VERSION ""

NS_ :

BS_:

BU_: FLZCU_VCU_EP FLZCU_PDCS_EP FLZCU_EP VCU_EP FLZCU_SignalRoute_EP BMS CDU FMCU_ISG FMCU ISG RMCU RMCU_E0V EVCC PDCS_EP PDCS_EP_E0V CIC_EP RmcuCdu RmcuCdu_E0V FmcuVcu_EP FmcuVcu_EP_E0V

BO_ 515 EVCC_1: 24 EVCC
 SG_ EVCC_1_CRC1 : 7|8@0+ (1,0) [0|255] ""  FLZCU_VCU_EP,VCU_EP,BMS,CDU,PDCS_EP,PDCS_EP_E0V,RmcuCdu,RmcuCdu_E0V,FmcuVcu_EP,FmcuVcu_EP_E0V
 SG_ EVCC_1_RollgCntr1 : 11|4@0+ (1,0) [0|14] ""  FLZCU_VCU_EP,VCU_EP,BMS,CDU,PDCS_EP,PDCS_EP_E0V,RmcuCdu,RmcuCdu_E0V,FmcuVcu_EP,FmcuVcu_EP_E0V
 SG_ EVCC_1_Resd1 : 15|4@0+ (1,0) [0|15] ""  FLZCU_VCU_EP,VCU_EP,BMS,CDU,PDCS_EP,PDCS_EP_E0V,RmcuCdu,RmcuCdu_E0V,FmcuVcu_EP,FmcuVcu_EP_E0V
 SG_ EVCC_GunConnectSt : 23|2@0+ (1,0) [0|3] ""  FLZCU_VCU_EP,VCU_EP,BMS,CDU,RMCU,RMCU_E0V,PDCS_EP,PDCS_EP_E0V,RmcuCdu,RmcuCdu_E0V,FmcuVcu_EP,FmcuVcu_EP_E0V
 SG_ EVCC_ElectronicLockSts : 21|3@0+ (1,0) [0|4] ""  FLZCU_VCU_EP,VCU_EP,BMS,CDU,PDCS_EP,PDCS_EP_E0V,RmcuCdu,RmcuCdu_E0V,FmcuVcu_EP,FmcuVcu_EP_E0V
 SG_ EVCC_PPCode : 18|4@0+ (1,0) [0|15] ""  CDU,RmcuCdu,RmcuCdu_E0V
 SG_ EVCC_CC_RCR4_Sts : 30|13@0+ (1,0) [0|3400] "R"  FLZCU_VCU_EP,VCU_EP,BMS,CDU,PDCS_EP,PDCS_EP_E0V,RmcuCdu,RmcuCdu_E0V,FmcuVcu_EP,FmcuVcu_EP_E0V
 SG_ EVCC_CP_DutyCycleFault : 33|1@0+ (1,0) [0|1] ""  FLZCU_VCU_EP,VCU_EP,BMS,CDU,PDCS_EP,PDCS_EP_E0V,RmcuCdu,RmcuCdu_E0V,FmcuVcu_EP,FmcuVcu_EP_E0V
 SG_ EVCC_COUNTRY_SUPPORT : 32|2@0+ (1,0) [0|3] ""  FLZCU_VCU_EP,VCU_EP,BMS,CDU,PDCS_EP,PDCS_EP_E0V,RmcuCdu,RmcuCdu_E0V,FmcuVcu_EP,FmcuVcu_EP_E0V
 SG_ EVCC_CP_DutyCycleValue : 46|8@0+ (1,0) [0|100] "%"  CDU,RmcuCdu,RmcuCdu_E0V
 SG_ EVCC_CPSts : 54|3@0+ (1,0) [0|7] ""  FLZCU_VCU_EP,VCU_EP,BMS,CDU,PDCS_EP,PDCS_EP_E0V,RmcuCdu,RmcuCdu_E0V,FmcuVcu_EP,FmcuVcu_EP_E0V
 SG_ EVCC_S2Swtsts : 51|2@0+ (1,0) [0|3] ""  FLZCU_VCU_EP,VCU_EP,BMS,CDU,PDCS_EP,PDCS_EP_E0V,RmcuCdu,RmcuCdu_E0V,FmcuVcu_EP,FmcuVcu_EP_E0V
 SG_ EVCC_CC_ConnectSts : 49|2@0+ (1,0) [0|3] ""  FLZCU_VCU_EP,VCU_EP,BMS,CDU,PDCS_EP,PDCS_EP_E0V,RmcuCdu,RmcuCdu_E0V,FmcuVcu_EP,FmcuVcu_EP_E0V
 SG_ EVCC_CC_ConnectDischarSts : 63|2@0+ (1,0) [0|3] ""  FLZCU_VCU_EP,VCU_EP,BMS,CDU,PDCS_EP,PDCS_EP_E0V,RmcuCdu,RmcuCdu_E0V,FmcuVcu_EP,FmcuVcu_EP_E0V
 SG_ EVCC_CC2_ConnectSts : 61|2@0+ (1,0) [0|3] ""  FLZCU_VCU_EP,VCU_EP,BMS,RMCU,RMCU_E0V,PDCS_EP,PDCS_EP_E0V,RmcuCdu,RmcuCdu_E0V,FmcuVcu_EP,FmcuVcu_EP_E0V
 SG_ EVCC_CC2_Alarm : 59|1@0+ (1,0) [0|1] ""  FLZCU_VCU_EP,VCU_EP,BMS,PDCS_EP,PDCS_EP_E0V,FmcuVcu_EP,FmcuVcu_EP_E0V
 SG_ EVCC_ChargeType : 58|3@0+ (1,0) [0|7] ""  FLZCU_VCU_EP,VCU_EP,BMS,CDU,RMCU,RMCU_E0V,PDCS_EP,PDCS_EP_E0V,RmcuCdu,RmcuCdu_E0V,FmcuVcu_EP,FmcuVcu_EP_E0V
 SG_ EVCC_1_CRC2 : 71|8@0+ (1,0) [0|255] ""  FLZCU_VCU_EP,VCU_EP,BMS,CDU,PDCS_EP,PDCS_EP_E0V,RmcuCdu,RmcuCdu_E0V,FmcuVcu_EP,FmcuVcu_EP_E0V
 SG_ EVCC_1_RollgCntr2 : 75|4@0+ (1,0) [0|14] ""  FLZCU_VCU_EP,VCU_EP,BMS,CDU,PDCS_EP,PDCS_EP_E0V,RmcuCdu,RmcuCdu_E0V,FmcuVcu_EP,FmcuVcu_EP_E0V
 SG_ EVCC_1_Resd2 : 79|4@0+ (1,0) [0|15] ""  FLZCU_VCU_EP,VCU_EP,BMS,CDU,PDCS_EP,PDCS_EP_E0V,RmcuCdu,RmcuCdu_E0V,FmcuVcu_EP,FmcuVcu_EP_E0V
 SG_ EVCC_FaultLevel : 87|3@0+ (1,0) [0|7] ""  FLZCU_VCU_EP,VCU_EP,BMS,PDCS_EP,PDCS_EP_E0V,FmcuVcu_EP,FmcuVcu_EP_E0V
 SG_ EVCC_CPMaxVolt : 84|10@0+ (0.1,0) [0|102.2] "V"  FLZCU_VCU_EP,VCU_EP,BMS,CDU,PDCS_EP,PDCS_EP_E0V,RmcuCdu,RmcuCdu_E0V,FmcuVcu_EP,FmcuVcu_EP_E0V
 SG_ EVCC_DCPlusTemp : 90|8@0+ (1,-40) [-40|213] "��"  FLZCU_VCU_EP,VCU_EP,BMS,PDCS_EP,PDCS_EP_E0V,FmcuVcu_EP,FmcuVcu_EP_E0V
 SG_ EVCC_DCMinusTemp : 98|8@0+ (1,-40) [-40|213] "��"  FLZCU_VCU_EP,VCU_EP,BMS,PDCS_EP,PDCS_EP_E0V,FmcuVcu_EP,FmcuVcu_EP_E0V
 SG_ EVCC_TotalFaultNum : 106|8@0+ (1,0) [0|63] ""  FLZCU_VCU_EP,VCU_EP,PDCS_EP,PDCS_EP_E0V,FmcuVcu_EP,FmcuVcu_EP_E0V
 SG_ EVCC_1_Resd4 : 122|3@0+ (1,0) [0|7] ""  Vector__XXX
 SG_ EVCC_FaultNum1 : 114|8@0+ (1,0) [0|255] ""  FLZCU_VCU_EP,VCU_EP,PDCS_EP,PDCS_EP_E0V,FmcuVcu_EP,FmcuVcu_EP_E0V
 SG_ EVCC_1_CRC3 : 135|8@0+ (1,0) [0|255] ""  Vector__XXX
 SG_ EVCC_1_RollgCntr3 : 139|4@0+ (1,0) [0|14] ""  Vector__XXX
 SG_ EVCC_1_Resd3 : 143|4@0+ (1,0) [0|15] ""  Vector__XXX
 SG_ EVCC_FaultNum2 : 151|8@0+ (1,0) [0|255] ""  FLZCU_VCU_EP,VCU_EP,PDCS_EP,PDCS_EP_E0V,FmcuVcu_EP,FmcuVcu_EP_E0V
 SG_ EVCC_CPVolt : 159|7@0+ (0.1,0) [0|12.7] "V"  Vector__XXX
 SG_ EVCC_PPRes : 167|13@0+ (1,0) [0|8191] "��"  Vector__XXX
 SG_ EVCC_ChargingStage : 183|8@0+ (1,0) [0|255] ""  FLZCU_VCU_EP,VCU_EP,BMS,RMCU,RMCU_E0V,PDCS_EP,PDCS_EP_E0V,RmcuCdu,RmcuCdu_E0V,FmcuVcu_EP,FmcuVcu_EP_E0V

BO_ 1113 EVCC_2: 64 EVCC
 SG_ EVCC_PLCAvgAttenuation : 7|8@0+ (1,0) [0|255] "db"  Vector__XXX
 SG_ EVCC_StopChrgnReason : 15|2@0+ (1,0) [0|3] ""  Vector__XXX
 SG_ EVCC_A_POSITIVE : 13|2@0+ (1,0) [0|3] ""  Vector__XXX
 SG_ EVCC_SupplierCode : 23|16@0+ (1,0) [0|65535] ""  Vector__XXX
 SG_ EVCC_HwVersion : 39|8@0+ (1,0) [0|255] ""  Vector__XXX
 SG_ EVCC_SwMajorVersion : 47|8@0+ (1,0) [0|255] ""  Vector__XXX
 SG_ EVCC_SwMinorVersion : 55|8@0+ (1,0) [0|255] ""  Vector__XXX
 SG_ EVCC_SwPatchVersion : 63|8@0+ (1,0) [0|255] ""  Vector__XXX
 SG_ EVCC_2_CRC2 : 71|8@0+ (1,0) [0|255] ""  Vector__XXX
 SG_ EVCC_2_RollgCntr2 : 75|4@0+ (1,0) [0|14] ""  Vector__XXX
 SG_ EVCC_2_Resd2 : 79|4@0+ (1,0) [0|15] ""  Vector__XXX
 SG_ EVCC_SwVersionYear : 87|8@0+ (1,0) [0|255] ""  Vector__XXX
 SG_ EVCC_SwVersionMonth : 95|8@0+ (1,0) [0|12] ""  Vector__XXX
 SG_ EVCC_SwVersionDay : 103|8@0+ (1,0) [0|31] ""  Vector__XXX
 SG_ EVSE_MaxVol : 111|14@0+ (0.1,0) [0|1638.3] "V"  FLZCU_VCU_EP,VCU_EP,BMS,RMCU,RMCU_E0V,PDCS_EP,PDCS_EP_E0V,RmcuCdu,RmcuCdu_E0V,FmcuVcu_EP,FmcuVcu_EP_E0V
 SG_ EVCC_GB_RX_ERROR : 123|4@0+ (1,0) [0|15] ""  BMS
 SG_ EVCC_GB_CHM_ERROR : 125|2@0+ (1,0) [0|3] ""  BMS
 SG_ EVCC_GB_CML_ERROR : 126|1@0+ (1,0) [0|1] ""  BMS
 SG_ EVCC_APP_DM_ERROR : 113|3@0+ (1,0) [0|7] ""  Vector__XXX
 SG_ EVCC_2_CRC3 : 135|8@0+ (1,0) [0|255] ""  Vector__XXX
 SG_ EVCC_2_RollgCntr3 : 139|4@0+ (1,0) [0|14] ""  Vector__XXX
 SG_ EVCC_2_Resd3 : 143|4@0+ (1,0) [0|15] ""  Vector__XXX
 SG_ EVSE_MinVol : 151|14@0+ (0.1,0) [0|1638.3] "V"  FLZCU_VCU_EP,VCU_EP,BMS,RMCU,RMCU_E0V,PDCS_EP,PDCS_EP_E0V,RmcuCdu,RmcuCdu_E0V,FmcuVcu_EP,FmcuVcu_EP_E0V
 SG_ EVSE_MaxCur : 153|14@0+ (0.1,0) [0|1638.3] "A"  FLZCU_VCU_EP,VCU_EP,BMS,PDCS_EP,PDCS_EP_E0V,FmcuVcu_EP,FmcuVcu_EP_E0V
 SG_ EVSE_MinCur : 171|10@0+ (0.1,0) [0|102.3] "A"  FLZCU_VCU_EP,VCU_EP,BMS,RMCU,RMCU_E0V,PDCS_EP,PDCS_EP_E0V,RmcuCdu,RmcuCdu_E0V,FmcuVcu_EP,FmcuVcu_EP_E0V
 SG_ EVCC_GB_SPECIAL_ERROR : 186|3@0+ (1,0) [0|7] ""  BMS
 SG_ EVCC_GB_CRM_ERROR : 188|2@0+ (1,0) [0|3] ""  BMS
 SG_ EVCC_GB_CRO_ERROR : 189|1@0+ (1,0) [0|1] ""  BMS
 SG_ EVCC_GB_CCS_ERROR : 177|2@0+ (1,0) [0|3] ""  BMS
 SG_ EVCC_GB_CST_ERROR : 190|1@0+ (1,0) [0|1] ""  BMS
 SG_ EVCC_GB_CSD_ERROR : 191|1@0+ (1,0) [0|1] ""  BMS
 SG_ EVCC_2_CRC4 : 199|8@0+ (1,0) [0|255] ""  Vector__XXX
 SG_ EVCC_2_RollgCntr4 : 203|4@0+ (1,0) [0|14] ""  Vector__XXX
 SG_ EVCC_2_Resd4 : 207|4@0+ (1,0) [0|15] ""  Vector__XXX
 SG_ EVSE_MaxPwr : 215|11@0+ (1,0) [0|2047] "KW"  FLZCU_VCU_EP,VCU_EP,BMS,PDCS_EP,PDCS_EP_E0V,FmcuVcu_EP,FmcuVcu_EP_E0V
 SG_ EVSE_OutputVol : 220|14@0+ (0.1,0) [0|1638.3] "V"  FLZCU_VCU_EP,VCU_EP,BMS,RMCU,RMCU_E0V,PDCS_EP,PDCS_EP_E0V,RmcuCdu,RmcuCdu_E0V,FmcuVcu_EP,FmcuVcu_EP_E0V
 SG_ EVSE_OutputCur : 238|12@0+ (0.5,0) [0|2047.5] "A"  BMS
 SG_ EVCC_MATCHING_ERROR : 242|3@0+ (1,0) [0|7] ""  Vector__XXX
 SG_ EVCC_MATCHED_ERROR : 255|1@0+ (1,0) [0|1] ""  Vector__XXX
 SG_ EVCC_BC_B1_ERROR : 254|2@0+ (1,0) [0|3] ""  Vector__XXX
 SG_ EVCC_BC_B2_ERROR : 252|2@0+ (1,0) [0|3] ""  Vector__XXX
 SG_ EVCC_BC_STATE_REQ_TO : 250|1@0+ (1,0) [0|1] ""  Vector__XXX
 SG_ EVCC_BC_C2_ERROR : 249|2@0+ (1,0) [0|3] ""  Vector__XXX
 SG_ EVCC_2_CRC5 : 263|8@0+ (1,0) [0|255] ""  Vector__XXX
 SG_ EVCC_2_RollgCntr5 : 267|4@0+ (1,0) [0|14] ""  Vector__XXX
 SG_ EVCC_2_Resd5 : 271|4@0+ (1,0) [0|15] ""  Vector__XXX
 SG_ EVCC_BC_EMC_ERROR : 279|3@0+ (1,0) [0|7] ""  Vector__XXX
 SG_ EVCC_BC_STOP_ERROR : 276|3@0+ (1,0) [0|7] ""  Vector__XXX
 SG_ EVCC_CONNECTING_ERROR : 273|3@0+ (1,0) [0|7] ""  Vector__XXX
 SG_ EVCC_SLEEP_AEF_DETECT : 286|1@0+ (1,0) [0|1] ""  Vector__XXX
 SG_ EVCC_V2G_REQ_TO_ERROR : 285|5@0+ (1,0) [0|31] ""  Vector__XXX
 SG_ EVCC_V2G_RES_TO_ERROR : 280|5@0+ (1,0) [0|31] ""  Vector__XXX
 SG_ EVCC_V2G_ERROR : 291|4@0+ (1,0) [0|15] ""  Vector__XXX
 SG_ EVCC_SSETUP_ERROR : 303|3@0+ (1,0) [0|7] ""  Vector__XXX
 SG_ EVCC_SDISCOVERY_ERROR : 300|3@0+ (1,0) [0|7] ""  Vector__XXX
 SG_ EVCC_PSS_ERROR : 297|3@0+ (1,0) [0|7] ""  Vector__XXX
 SG_ EVCC_AUTHORIZATION_ERROR : 310|3@0+ (1,0) [0|7] ""  Vector__XXX
 SG_ EVCC_CPD_ERROR : 307|3@0+ (1,0) [0|7] ""  Vector__XXX
 SG_ EVCC_POWERDELIVERY_CP_STATE : 304|1@0+ (1,0) [0|1] ""  Vector__XXX
 SG_ EVCC_CHARGINGSTATUS_ERROR : 319|3@0+ (1,0) [0|7] ""  Vector__XXX
 SG_ EVCC_SSTOP_ERROR : 316|3@0+ (1,0) [0|7] ""  Vector__XXX
 SG_ EVCC_2_Resd8 : 313|2@0+ (1,0) [0|3] ""  Vector__XXX
 SG_ EVCC_2_CRC6 : 327|8@0+ (1,0) [0|255] ""  Vector__XXX
 SG_ EVCC_2_RollgCntr6 : 331|4@0+ (1,0) [0|14] ""  Vector__XXX
 SG_ EVCC_2_Resd6 : 335|4@0+ (1,0) [0|15] ""  Vector__XXX
 SG_ EVCC_CABLECHECK_ERROR : 343|3@0+ (1,0) [0|7] ""  Vector__XXX
 SG_ EVCC_PRECHARGE_ERROR : 340|3@0+ (1,0) [0|7] ""  Vector__XXX
 SG_ EVCC_CURRENTDEMAND_ERROR : 337|3@0+ (1,0) [0|7] ""  Vector__XXX
 SG_ EVCC_WDETECTION_ERROR : 350|3@0+ (1,0) [0|7] ""  Vector__XXX
 SG_ EVCC_V2GTP_ERROR : 347|3@0+ (1,0) [0|7] ""  Vector__XXX
 SG_ EVCC_EXI_ERROR : 344|3@0+ (1,0) [0|7] ""  Vector__XXX
 SG_ EVCC_NET_ERROR : 357|4@0+ (1,0) [0|15] ""  Vector__XXX
 SG_ EVCC_EMC_ERROR : 353|3@0+ (1,0) [0|7] ""  Vector__XXX
 SG_ EVCC_DIN_ERROR : 366|4@0+ (1,0) [0|15] ""  Vector__XXX
 SG_ EVCC_DIN_SSETUP_ERROR : 362|3@0+ (1,0) [0|7] ""  Vector__XXX
 SG_ EVCC_DIN_SDISCOVERY_ERROR : 375|3@0+ (1,0) [0|7] ""  Vector__XXX
 SG_ EVCC_DIN_SPS_ERROR : 372|3@0+ (1,0) [0|7] ""  Vector__XXX
 SG_ EVCC_DIN_CAUTHENTICATION_ERROR : 369|3@0+ (1,0) [0|7] ""  Vector__XXX
 SG_ EVCC_DIN_CPD_ERROR : 382|3@0+ (1,0) [0|7] ""  Vector__XXX
 SG_ EVCC_2_Resd9 : 376|1@0+ (1,0) [0|1] ""  Vector__XXX
 SG_ EVCC_DIN_CABLECHECK_ERROR : 379|3@0+ (1,0) [0|7] ""  Vector__XXX
 SG_ EVCC_2_CRC7 : 391|8@0+ (1,0) [0|255] ""  Vector__XXX
 SG_ EVCC_2_RollgCntr7 : 395|4@0+ (1,0) [0|14] ""  Vector__XXX
 SG_ EVCC_2_Resd7 : 399|4@0+ (1,0) [0|15] ""  Vector__XXX
 SG_ EVCC_DIN_PRECHARGE_ERROR : 407|3@0+ (1,0) [0|7] ""  Vector__XXX
 SG_ EVCC_DIN_POWERDELIVERY_ERROR : 404|3@0+ (1,0) [0|7] ""  Vector__XXX
 SG_ EVCC_DIN_CURRENTDEMAND_ERROR : 401|3@0+ (1,0) [0|7] ""  Vector__XXX
 SG_ EVCC_DIN_WDETECTION_ERROR : 414|3@0+ (1,0) [0|7] ""  Vector__XXX
 SG_ EVCC_DIN_SSTOP_ERROR : 411|3@0+ (1,0) [0|7] ""  Vector__XXX
 SG_ EVCC_DIN_METERINGRECEIPT_ERROR : 408|3@0+ (1,0) [0|7] ""  Vector__XXX
 SG_ EVCC_SLAC_RETRY_TIMEOUT : 421|1@0+ (1,0) [0|1] ""  Vector__XXX
 SG_ EVCC_SLAC_AMPMAP_ERROR : 420|2@0+ (1,0) [0|3] ""  Vector__XXX
 SG_ EVCC_SLAC_ATTEN_ERROR : 418|2@0+ (1,0) [0|3] ""  Vector__XXX
 SG_ EVCC_SLAC_BCB_FAILED : 416|1@0+ (1,0) [0|1] ""  Vector__XXX
 SG_ EVCC_SLAC_JOIN_ERROR : 431|3@0+ (1,0) [0|7] ""  Vector__XXX
 SG_ EVCC_SLAC_PAUSE_RETRY_OVERFLOW : 428|1@0+ (1,0) [0|1] ""  Vector__XXX
 SG_ EVCC_SLAC_RESUME_ERROR : 427|2@0+ (1,0) [0|3] ""  Vector__XXX
 SG_ EVCC_SLAC_ETH_ERROR : 425|2@0+ (1,0) [0|3] ""  Vector__XXX
 SG_ EVCC_SLAC_DISLINK_RETRY_OVERFLOW : 439|1@0+ (1,0) [0|1] ""  Vector__XXX
 SG_ EVCC_SLAC_INIT_RETRY_OVERFLOW : 438|1@0+ (1,0) [0|1] ""  Vector__XXX
 SG_ EVCC_APP_PSS_ERROR : 437|2@0+ (1,0) [0|3] ""  Vector__XXX
 SG_ EVCC_APP_CPD_ERROR : 435|2@0+ (1,0) [0|3] ""  Vector__XXX
 SG_ EVCC_APP_DTC_ERROR : 433|2@0+ (1,0) [0|3] ""  Vector__XXX
 SG_ EVCC_DIN_CCPC_ERROR : 447|3@0+ (1,0) [0|7] ""  Vector__XXX
 SG_ EVCC_V2G_CCPC_ERROR : 444|3@0+ (1,0) [0|7] ""  Vector__XXX
 SG_ EVCC_GunConnectSt : 471|2@0+ (1,0) [0|3] ""  Vector__XXX
 SG_ EVCC_ElectronicLockRes : 479|16@0+ (1,0) [0|65534] ""  Vector__XXX
 SG_ EVCC_ElectronicLockSignal_Rel : 465|2@0+ (1,0) [0|3] ""  Vector__XXX
 SG_ EVCC_PLCNodeFwVer : 495|16@0+ (1,0) [0|65535] ""  Vector__XXX
 SG_ EVCC_BatVolConfig : 511|2@0+ (1,0) [0|3] ""  Vector__XXX
 SG_ EVCC_2_Resd10 : 509|6@0+ (1,0) [0|63] ""  Vector__XXX

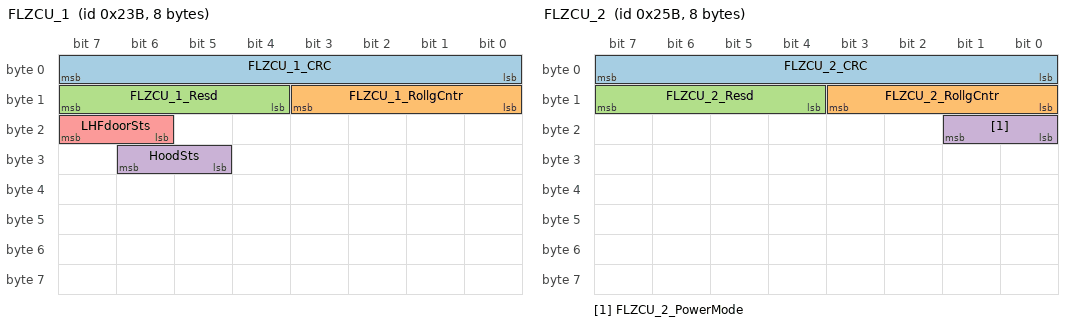
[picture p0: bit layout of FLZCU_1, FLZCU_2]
BO_ 571 FLZCU_1: 8 FLZCU_VCU_EP
 SG_ FLZCU_1_CRC : 7|8@0+ (1,0) [0|255] ""  Vector__XXX
 SG_ FLZCU_1_RollgCntr : 11|4@0+ (1,0) [0|14] ""  Vector__XXX
 SG_ FLZCU_1_Resd : 15|4@0+ (1,0) [0|15] ""  Vector__XXX
 SG_ HoodSts : 30|2@0+ (1,0) [0|3] ""  PDCS_EP,PDCS_EP_E0V,FmcuVcu_EP,FmcuVcu_EP_E0V
 SG_ LHFdoorSts : 23|2@0+ (1,0) [0|3] ""  CDU,RmcuCdu,RmcuCdu_E0V

BO_ 603 FLZCU_2: 8 Vector__XXX
 SG_ FLZCU_2_CRC : 7|8@0+ (1,0) [0|255] ""  FMCU_ISG,FMCU,ISG,RMCU,RMCU_E0V,PDCS_EP,PDCS_EP_E0V,RmcuCdu,RmcuCdu_E0V,FmcuVcu_EP,FmcuVcu_EP_E0V
 SG_ FLZCU_2_RollgCntr : 11|4@0+ (1,0) [0|14] ""  FMCU_ISG,FMCU,ISG,RMCU,RMCU_E0V,PDCS_EP,PDCS_EP_E0V,RmcuCdu,RmcuCdu_E0V,FmcuVcu_EP,FmcuVcu_EP_E0V
 SG_ FLZCU_2_Resd : 15|4@0+ (1,0) [0|15] ""  FMCU_ISG,FMCU,ISG,RMCU,RMCU_E0V,PDCS_EP,PDCS_EP_E0V,RmcuCdu,RmcuCdu_E0V,FmcuVcu_EP,FmcuVcu_EP_E0V
 SG_ FLZCU_2_PowerMode : 17|2@0+ (1,0) [0|3] ""  FMCU_ISG,FMCU,ISG,RMCU,RMCU_E0V,PDCS_EP,PDCS_EP_E0V,RmcuCdu,RmcuCdu_E0V,FmcuVcu_EP,FmcuVcu_EP_E0V

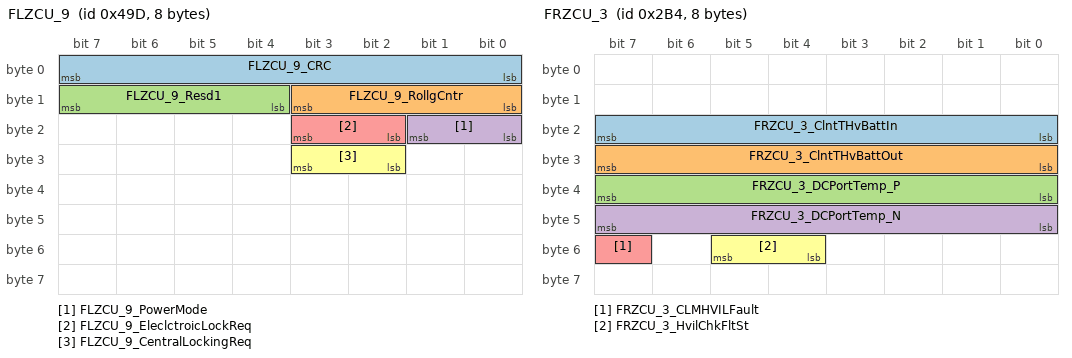
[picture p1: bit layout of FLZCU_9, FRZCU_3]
BO_ 1181 FLZCU_9: 8 FLZCU_VCU_EP
 SG_ FLZCU_9_CRC : 7|8@0+ (1,0) [0|255] ""  CIC_EP
 SG_ FLZCU_9_RollgCntr : 11|4@0+ (1,0) [0|14] ""  CIC_EP
 SG_ FLZCU_9_Resd1 : 15|4@0+ (1,0) [0|15] ""  CIC_EP
 SG_ FLZCU_9_PowerMode : 17|2@0+ (1,0) [0|3] ""  BMS,CIC_EP
 SG_ FLZCU_9_EleclctroicLockReq : 19|2@0+ (1,0) [0|3] ""  CDU,PDCS_EP,PDCS_EP_E0V,RmcuCdu,RmcuCdu_E0V,FmcuVcu_EP,FmcuVcu_EP_E0V
 SG_ FLZCU_9_CentralLockingReq : 27|2@0+ (1,0) [0|3] ""  CDU,EVCC,CIC_EP,RmcuCdu,RmcuCdu_E0V

BO_ 692 FRZCU_3: 8 Vector__XXX
 SG_ FRZCU_3_ClntTHvBattIn : 23|8@0+ (1,-40) [-40|120] "grad celsius (��C)"  BMS,PDCS_EP,PDCS_EP_E0V,FmcuVcu_EP,FmcuVcu_EP_E0V
 SG_ FRZCU_3_ClntTHvBattOut : 31|8@0+ (1,-40) [-40|120] "grad celsius (��C)"  BMS,PDCS_EP,PDCS_EP_E0V,FmcuVcu_EP,FmcuVcu_EP_E0V
 SG_ FRZCU_3_DCPortTemp_P : 39|8@0+ (1,-40) [-40|213] "grad celsius (��C)"  BMS
 SG_ FRZCU_3_DCPortTemp_N : 47|8@0+ (1,-40) [-40|213] "grad celsius (��C)"  BMS
 SG_ FRZCU_3_CLMHVILFault : 55|1@0+ (1,0) [0|1] ""  PDCS_EP,PDCS_EP_E0V,FmcuVcu_EP,FmcuVcu_EP_E0V
 SG_ FRZCU_3_HvilChkFltSt : 53|2@0+ (1,0) [0|3] ""  PDCS_EP,PDCS_EP_E0V,FmcuVcu_EP,FmcuVcu_EP_E0V

BO_ 469 FMCU_1: 32 FMCU_ISG
 SG_ FMCU_1_CRC1 : 7|8@0+ (1,0) [0|255] ""  FLZCU_VCU_EP,FLZCU_PDCS_EP,VCU_EP,PDCS_EP,PDCS_EP_E0V
 SG_ FMCU_1_RollgCntr1 : 11|4@0+ (1,0) [0|14] ""  FLZCU_VCU_EP,FLZCU_PDCS_EP,VCU_EP,PDCS_EP,PDCS_EP_E0V
 SG_ FMCU_1_Resd1 : 15|4@0+ (1,0) [0|15] ""  FLZCU_VCU_EP,FLZCU_PDCS_EP,VCU_EP,PDCS_EP,PDCS_EP_E0V
 SG_ FMCU_TorqMax : 23|12@0+ (0.25,0) [0|350] "Nm"  FLZCU_VCU_EP,FLZCU_PDCS_EP,VCU_EP,RMCU,RMCU_E0V,PDCS_EP,PDCS_EP_E0V,CIC_EP,RmcuCdu,RmcuCdu_E0V
 SG_ FMCU_TorqMin : 27|12@0+ (0.25,-350) [-350|0] "Nm"  FLZCU_VCU_EP,FLZCU_PDCS_EP,VCU_EP,RMCU,RMCU_E0V,PDCS_EP,PDCS_EP_E0V,CIC_EP,RmcuCdu,RmcuCdu_E0V
 SG_ FMCU_TorqAct : 47|12@0+ (0.25,-350) [-350|350] "Nm"  FLZCU_VCU_EP,FLZCU_PDCS_EP,VCU_EP,RMCU,RMCU_E0V,PDCS_EP,PDCS_EP_E0V,RmcuCdu,RmcuCdu_E0V
 SG_ FMCU_ModeSt : 51|4@0+ (1,0) [0|15] ""  FLZCU_VCU_EP,FLZCU_PDCS_EP,VCU_EP,FLZCU_SignalRoute_EP,BMS,PDCS_EP,PDCS_EP_E0V
 SG_ FMCU_1_CRC2 : 71|8@0+ (1,0) [0|255] ""  FLZCU_VCU_EP,FLZCU_PDCS_EP,VCU_EP,PDCS_EP,PDCS_EP_E0V
 SG_ FMCU_1_RollgCntr2 : 75|4@0+ (1,0) [0|14] ""  FLZCU_VCU_EP,FLZCU_PDCS_EP,VCU_EP,PDCS_EP,PDCS_EP_E0V
 SG_ FMCU_1_Resd2 : 79|4@0+ (1,0) [0|15] ""  FLZCU_VCU_EP,FLZCU_PDCS_EP,VCU_EP,PDCS_EP,PDCS_EP_E0V
 SG_ FMCU_SpdAct : 87|16@0+ (1,-32767) [-32767|32766] "rpm"  FLZCU_VCU_EP,FLZCU_PDCS_EP,VCU_EP,RMCU,RMCU_E0V,PDCS_EP,PDCS_EP_E0V,RmcuCdu,RmcuCdu_E0V
 SG_ FMCU_TrqActDampingReq : 103|12@0+ (0.25,-350) [-350|350] "Nm"  FLZCU_VCU_EP,FLZCU_PDCS_EP,VCU_EP,PDCS_EP,PDCS_EP_E0V
 SG_ FMCU_FMCUDeratSts : 107|4@0+ (1,0) [0|15] ""  FLZCU_VCU_EP,FLZCU_PDCS_EP,VCU_EP,FLZCU_SignalRoute_EP,PDCS_EP,PDCS_EP_E0V
 SG_ FMCU_UdcAct : 119|10@0+ (1,0) [0|1021] "V"  FLZCU_VCU_EP,FLZCU_PDCS_EP,VCU_EP,BMS,PDCS_EP,PDCS_EP_E0V
 SG_ FMCU_1_CRC3 : 135|8@0+ (1,0) [0|255] ""  FLZCU_VCU_EP,FLZCU_PDCS_EP,VCU_EP,PDCS_EP,PDCS_EP_E0V
 SG_ FMCU_1_RollgCntr3 : 139|4@0+ (1,0) [0|14] ""  FLZCU_VCU_EP,FLZCU_PDCS_EP,VCU_EP,PDCS_EP,PDCS_EP_E0V
 SG_ FMCU_1_Resd3 : 143|4@0+ (1,0) [0|15] ""  FLZCU_VCU_EP,FLZCU_PDCS_EP,VCU_EP,PDCS_EP,PDCS_EP_E0V
 SG_ FMCU_IdcAct : 151|11@0+ (1,-1023) [-1023|1021] "A"  FLZCU_VCU_EP,FLZCU_PDCS_EP,VCU_EP,BMS,PDCS_EP,PDCS_EP_E0V
 SG_ FMCU_ErrLvl : 156|3@0+ (1,0) [0|7] ""  FLZCU_VCU_EP,FLZCU_PDCS_EP,VCU_EP,RMCU,RMCU_E0V,PDCS_EP,PDCS_EP_E0V,RmcuCdu,RmcuCdu_E0V
 SG_ FMCU_InterlockStatus : 152|1@0+ (1,0) [0|1] ""  FLZCU_VCU_EP,FLZCU_PDCS_EP,VCU_EP,PDCS_EP,PDCS_EP_E0V
 SG_ FMCU_DampActive : 153|1@0+ (1,0) [0|1] ""  FLZCU_VCU_EP,FLZCU_PDCS_EP,VCU_EP,PDCS_EP,PDCS_EP_E0V
 SG_ FMCU_E_ClutchErrLvl : 173|3@0+ (1,0) [0|7] ""  FLZCU_VCU_EP,FLZCU_PDCS_EP,PDCS_EP,PDCS_EP_E0V
 SG_ FMCU_E_ClutchActMod : 170|3@0+ (1,0) [0|7] ""  FLZCU_VCU_EP,FLZCU_PDCS_EP,PDCS_EP,PDCS_EP_E0V
 SG_ FMCU_E_ClutchStus : 183|2@0+ (1,0) [0|3] ""  FLZCU_VCU_EP,FLZCU_PDCS_EP,PDCS_EP,PDCS_EP_E0V
 SG_ FMCU_E_ClutchCurr : 191|6@0+ (0.2,0) [0|10] ""  FLZCU_VCU_EP,FLZCU_PDCS_EP,PDCS_EP,PDCS_EP_E0V
 SG_ FMCU_E_ClutchEngMilLampReq : 185|2@0+ (1,0) [0|3] ""  FLZCU_VCU_EP,FLZCU_PDCS_EP,PDCS_EP,PDCS_EP_E0V
 SG_ FMCU_NegTrqAvailMin_2s : 212|13@0+ (0.25,-350) [-350|0] ""  FLZCU_VCU_EP,FLZCU_PDCS_EP,VCU_EP,PDCS_EP,PDCS_EP_E0V
 SG_ FMCU_PosTrqAvailMax_2s : 228|13@0+ (0.25,0) [0|350] ""  FLZCU_VCU_EP,FLZCU_PDCS_EP,VCU_EP,PDCS_EP,PDCS_EP_E0V

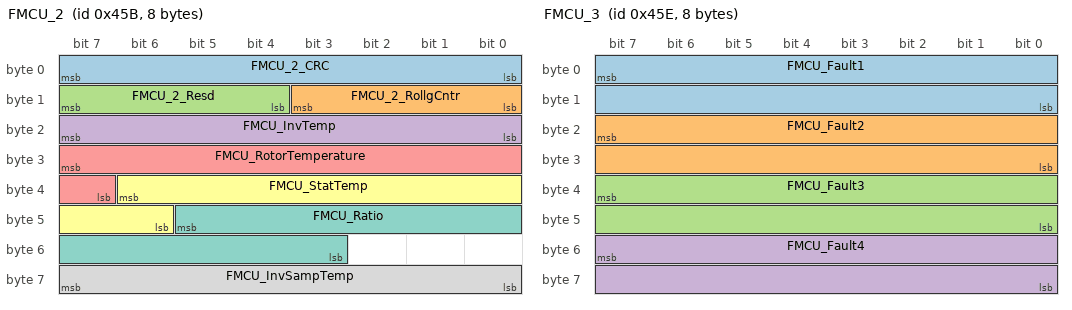
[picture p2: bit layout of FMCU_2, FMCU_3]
BO_ 1115 FMCU_2: 8 FMCU_ISG
 SG_ FMCU_2_CRC : 7|8@0+ (1,0) [0|255] ""  FLZCU_VCU_EP,FLZCU_PDCS_EP,VCU_EP,PDCS_EP,PDCS_EP_E0V
 SG_ FMCU_2_RollgCntr : 11|4@0+ (1,0) [0|14] ""  FLZCU_VCU_EP,FLZCU_PDCS_EP,VCU_EP,PDCS_EP,PDCS_EP_E0V
 SG_ FMCU_2_Resd : 15|4@0+ (1,0) [0|15] ""  FLZCU_VCU_EP,FLZCU_PDCS_EP,VCU_EP,PDCS_EP,PDCS_EP_E0V
 SG_ FMCU_InvTemp : 23|8@0+ (1,-40) [-40|213] "oC"  FLZCU_VCU_EP,FLZCU_PDCS_EP,VCU_EP,PDCS_EP,PDCS_EP_E0V
 SG_ FMCU_RotorTemperature : 31|9@0+ (1,-40) [-40|469] "oC"  FLZCU_VCU_EP,FLZCU_PDCS_EP,VCU_EP,PDCS_EP,PDCS_EP_E0V
 SG_ FMCU_StatTemp : 38|9@0+ (1,-40) [-40|469] "oC"  FLZCU_VCU_EP,FLZCU_PDCS_EP,VCU_EP,PDCS_EP,PDCS_EP_E0V
 SG_ FMCU_Ratio : 45|11@0+ (0.01,1) [8|15] ""  FLZCU_VCU_EP,FLZCU_PDCS_EP,VCU_EP,PDCS_EP,PDCS_EP_E0V
 SG_ FMCU_InvSampTemp : 63|8@0+ (1,-40) [-40|213] "oC"  FLZCU_VCU_EP,FLZCU_PDCS_EP,VCU_EP,PDCS_EP,PDCS_EP_E0V

BO_ 1118 FMCU_3: 8 FMCU_ISG
 SG_ FMCU_Fault1 : 7|16@0+ (1,0) [0|65535] ""  FLZCU_VCU_EP,FLZCU_PDCS_EP
 SG_ FMCU_Fault2 : 23|16@0+ (1,0) [0|65535] ""  FLZCU_VCU_EP,FLZCU_PDCS_EP
 SG_ FMCU_Fault3 : 39|16@0+ (1,0) [0|65535] ""  FLZCU_VCU_EP,FLZCU_PDCS_EP
 SG_ FMCU_Fault4 : 55|16@0+ (1,0) [0|65535] ""  FLZCU_VCU_EP,FLZCU_PDCS_EP

BO_ 1088 FMCU_4: 16 FMCU_ISG
 SG_ FMCU_WPhaseCurrent : 23|11@0+ (1,-1023) [-1023|1023] "A"  FLZCU_VCU_EP,FLZCU_PDCS_EP
 SG_ FMCU_VPhaseCurrent : 26|11@0+ (1,-1023) [-1023|1023] "A"  FLZCU_VCU_EP,FLZCU_PDCS_EP
 SG_ FMCU_UPhaseCurrent : 47|11@0+ (1,-1023) [-1023|1023] "A"  FLZCU_VCU_EP,FLZCU_PDCS_EP
 SG_ FMCU_4_SWInfo : 63|8@0+ (1,0) [0|255] ""  FLZCU_VCU_EP,FLZCU_PDCS_EP
 SG_ FMCU_4_CRC : 71|8@0+ (1,0) [0|255] ""  FLZCU_VCU_EP,FLZCU_PDCS_EP,VCU_EP,PDCS_EP,PDCS_EP_E0V
 SG_ FMCU_4_RollgCntr : 75|4@0+ (1,0) [0|14] ""  FLZCU_VCU_EP,FLZCU_PDCS_EP,VCU_EP,PDCS_EP,PDCS_EP_E0V
 SG_ FMCU_4_Resd : 79|4@0+ (1,0) [0|15] ""  FLZCU_VCU_EP,FLZCU_PDCS_EP,VCU_EP,PDCS_EP,PDCS_EP_E0V
 SG_ FMCU_TempW : 87|8@0+ (1,-40) [-40|213] "oC"  FLZCU_VCU_EP,FLZCU_PDCS_EP,VCU_EP,PDCS_EP,PDCS_EP_E0V
 SG_ FMCU_TempV : 95|8@0+ (1,-40) [-40|213] "oC"  FLZCU_VCU_EP,FLZCU_PDCS_EP,VCU_EP,PDCS_EP,PDCS_EP_E0V
 SG_ FMCU_TempU : 103|8@0+ (1,-40) [-40|213] "oC"  FLZCU_VCU_EP,FLZCU_PDCS_EP,VCU_EP,PDCS_EP,PDCS_EP_E0V
 SG_ FMCU_CoolantTemp : 111|8@0+ (1,-40) [-40|213] "oC"  FLZCU_VCU_EP,FLZCU_PDCS_EP,VCU_EP,PDCS_EP,PDCS_EP_E0V
 SG_ FMCU_Delta_TJ_Coolant : 119|8@0+ (1,-40) [-40|213] "oC"  FLZCU_VCU_EP,FLZCU_PDCS_EP,VCU_EP,PDCS_EP,PDCS_EP_E0V
 SG_ FMCU_IGBTmode : 122|3@0+ (1,0) [0|7] ""  FLZCU_VCU_EP,FLZCU_PDCS_EP,VCU_EP,PDCS_EP,PDCS_EP_E0V

BO_TX_BU_ 571 : FLZCU_VCU_EP,FLZCU_PDCS_EP,FLZCU_EP,FLZCU_SignalRoute_EP;

BO_TX_BU_ 1181 : FLZCU_VCU_EP,FLZCU_PDCS_EP,FLZCU_EP,FLZCU_SignalRoute_EP;

BO_TX_BU_ 469 : FMCU_ISG,FMCU,FmcuVcu_EP,FmcuVcu_EP_E0V;

BO_TX_BU_ 1115 : FMCU_ISG,FMCU,FmcuVcu_EP,FmcuVcu_EP_E0V;

BO_TX_BU_ 1118 : FMCU_ISG,FMCU,FmcuVcu_EP,FmcuVcu_EP_E0V;

BO_TX_BU_ 1088 : FMCU_ISG,FMCU,FmcuVcu_EP,FmcuVcu_EP_E0V;
CM_ SG_ 515 EVCC_1_CRC1 "Profile1A:E2E CRC (SAE J1850 CRC-8) for 8 Bytes
DataID:0x007B";
CM_ SG_ 515 EVCC_1_RollgCntr1 "Profile1A:E2E Rolling message counter(the maximum value of Alive counter is 14)";
CM_ SG_ 515 EVCC_1_Resd1 "Profile1A:E2E Reserved";
CM_ SG_ 515 EVCC_GunConnectSt "���ǹ����״̬
0-δ����
1-������
2-�����쳣";
CM_ SG_ 515 EVCC_PPCode "PP��ֵ����";
CM_ SG_ 515 EVCC_CP_DutyCycleFault "CP pwm fault";
CM_ SG_ 515 EVCC_COUNTRY_SUPPORT "ŷ��������֧��";
CM_ SG_ 515 EVCC_CP_DutyCycleValue "CPռ�ձ�";
CM_ SG_ 515 EVCC_CPSts "CP����";
CM_ SG_ 515 EVCC_S2Swtsts "S2״̬
0-�Ͽ���1-�պ�";
CM_ SG_ 515 EVCC_CC_ConnectSts "CC����״̬
 0x0:CCδ����
0x1:CC������
0x2:CC������    
0x3:��Ч";
CM_ SG_ 515 EVCC_CC_ConnectDischarSts "V2L �ŵ�ǹconnect states  
 0x0:CCδ����
0x1:CC������
0x2:CC������    
0x3:��Ч";
CM_ SG_ 515 EVCC_CC2_ConnectSts "CC2 connect state";
CM_ SG_ 515 EVCC_CC2_Alarm "CC2���ӹ���
0x0:�޹���
0x1:�й���";
CM_ SG_ 515 EVCC_ChargeType "�������
1-���������źų��
2-15118�������
3-15118ֱ�����
4-70121ֱ�����
5-�����ŵ�";
CM_ SG_ 515 EVCC_1_CRC2 "Profile1A:E2E CRC (SAE J1850 CRC-8) for 8 Bytes
DataID:0x007C";
CM_ SG_ 515 EVCC_1_RollgCntr2 "Profile1A:E2E Rolling message counter(the maximum value of Alive counter is 14)";
CM_ SG_ 515 EVCC_1_Resd2 "Profile1A:E2E Reserved";
CM_ SG_ 515 EVCC_FaultLevel "���ϵȼ�";
CM_ SG_ 515 EVCC_CPMaxVolt "charger CP MaxVolt value";
CM_ SG_ 515 EVCC_DCPlusTemp "DC+ temperature";
CM_ SG_ 515 EVCC_DCMinusTemp "DC-temperature";
CM_ SG_ 515 EVCC_TotalFaultNum "������";
CM_ SG_ 515 EVCC_1_Resd4 "Reserved";
CM_ SG_ 515 EVCC_FaultNum1 "���ϴ���";
CM_ SG_ 515 EVCC_1_CRC3 "Profile1A:E2E CRC (SAE J1850 CRC-8) for 8 Bytes
DataID:No ASIL requirements.Not configure
CRC Reserved.";
CM_ SG_ 515 EVCC_1_RollgCntr3 "Profile1A:E2E Rolling message counter(the maximum value of Alive counter is 14)";
CM_ SG_ 515 EVCC_1_Resd3 "Profile1A:E2E Reserved";
CM_ SG_ 515 EVCC_FaultNum2 "���ϴ���";
CM_ SG_ 515 EVCC_CPVolt "CPʵʱ��ѹ";
CM_ SG_ 515 EVCC_PPRes "PPʵʱ��ֵ";
CM_ SG_ 515 EVCC_ChargingStage "ŷ��������״̬";
CM_ SG_ 1113 EVCC_PLCAvgAttenuation "PLCͨѶƽ��˥��ֵ
EVCC�����޽��սڵ�";
CM_ SG_ 1113 EVCC_StopChrgnReason "EVCCֹͣ���ԭ��
EVCC�����޽��սڵ�";
CM_ SG_ 1113 EVCC_A_POSITIVE "A+�ź�
1-A+�ź�
2-û��A+�ź�";
CM_ SG_ 1113 EVCC_SupplierCode "Supplier Code";
CM_ SG_ 1113 EVCC_HwVersion "Hardware Version";
CM_ SG_ 1113 EVCC_SwMajorVersion "Software Major Version";
CM_ SG_ 1113 EVCC_SwMinorVersion "Software Minor Version";
CM_ SG_ 1113 EVCC_SwPatchVersion "Software Patch Version";
CM_ SG_ 1113 EVCC_2_CRC2 "Profile1A:E2E CRC (SAE J1850 CRC-8) for 8 Bytes
DataID:No ASIL requirements.Not configure
CRC Reserved.";
CM_ SG_ 1113 EVCC_2_RollgCntr2 "Profile1A:E2E Rolling message counter(the maximum value of Alive counter is 14)";
CM_ SG_ 1113 EVCC_2_Resd2 "Profile1A:E2E Reserved";
CM_ SG_ 1113 EVCC_SwVersionYear "Software Version Year-2000";
CM_ SG_ 1113 EVCC_SwVersionMonth "Software Version Month";
CM_ SG_ 1113 EVCC_SwVersionDay "Software Version Day";
CM_ SG_ 1113 EVSE_MaxVol "���׮����ѹ";
CM_ SG_ 1113 EVCC_GB_RX_ERROR "GB charge������
0x1:���յ�BST����
0x2:���յ�BEM����
0x3:����BHM��ʱ
0x4:����BRM��ʱ
0x5:����BCP��ʱ
0x6:����BRO��ʱ
0x7:����BCL��ʱ
0x8:����BCS��ʱ
0x9:����BST��ʱ
0xA:����BSD��ʱ";
CM_ SG_ 1113 EVCC_GB_CHM_ERROR "GB CHM������
0x1:����BHM���ݴ���
0x2:����BHM������Ч";
CM_ SG_ 1113 EVCC_GB_CML_ERROR "GB CML������
0x1:����BRO���ݴ���";
CM_ SG_ 1113 EVCC_APP_DM_ERROR "CPCM Decide Message Set������
0x1:���ģʽ(AC/DC)ƥ��ʧ��
0x2:Pnc��Eimƥ��ʧ��
0x3:����ģʽ�ڼ䣬PWM����ȷ
0x4:���ļ�����ʧ��";
CM_ SG_ 1113 EVCC_2_CRC3 "Profile1A:E2E CRC (SAE J1850 CRC-8) for 8 Bytes
DataID:No ASIL requirements.Not configure
CRC Reserved.";
CM_ SG_ 1113 EVCC_2_RollgCntr3 "Profile1A:E2E Rolling message counter(the maximum value of Alive counter is 14)";
CM_ SG_ 1113 EVCC_2_Resd3 "Profile1A:E2E Reserved";
CM_ SG_ 1113 EVSE_MinVol "���׮��С��ѹ";
CM_ SG_ 1113 EVSE_MaxCur "���׮������";
CM_ SG_ 1113 EVSE_MinCur "���׮��С����";
CM_ SG_ 1113 EVCC_GB_SPECIAL_ERROR "GB charge���������
0x1:������״̬����
0x2:��Ե��ⳬʱ
0x3:Ԥ�䳬ʱ
0x4:EV������BRO=0xAA����ʱ
0x5:ǹ������ʱ";
CM_ SG_ 1113 EVCC_GB_CRM_ERROR "GB CRM������
0x1:����BRM���ݴ���
0x2:����BCP���ݴ���";
CM_ SG_ 1113 EVCC_GB_CRO_ERROR "GB CRO������
0x1:����BCL���ݴ���";
CM_ SG_ 1113 EVCC_GB_CCS_ERROR "GB CCS������
0x1:����BCL���ݴ���
0x2:����BCS���ݴ���";
CM_ SG_ 1113 EVCC_GB_CST_ERROR "GB CST������
0x1:����BST���ݴ���";
CM_ SG_ 1113 EVCC_GB_CSD_ERROR "GB CSD������
0x1:����BSD���ݴ���";
CM_ SG_ 1113 EVCC_2_CRC4 "Profile1A:E2E CRC (SAE J1850 CRC-8) for 8 Bytes
DataID:No ASIL requirements.Not configure
CRC Reserved.";
CM_ SG_ 1113 EVCC_2_RollgCntr4 "Profile1A:E2E Rolling message counter(the maximum value of Alive counter is 14)";
CM_ SG_ 1113 EVCC_2_Resd4 "Profile1A:E2E Reserved";
CM_ SG_ 1113 EVSE_MaxPwr "���׮�����";
CM_ SG_ 1113 EVSE_OutputVol "���׮�����ѹ";
CM_ SG_ 1113 EVSE_OutputCur "���׮�������";
CM_ SG_ 1113 EVCC_MATCHING_ERROR "MATCHING������:
0x1:SLAC��ʱ
0x2:SLACʧ��
0x3:SLAC��⵽AEF����
0x4:SLAC��⵽��ǹ
0x5:SLAC�׶μ�⵽C״̬";
CM_ SG_ 1113 EVCC_MATCHED_ERROR "0x1:����Ͽ���ʱ";
CM_ SG_ 1113 EVCC_BC_B1_ERROR "BC_B1������:
0x1:��B1�׶μ�⵽C״̬
0x2:��B1�׶μ�⵽AEF״̬
0x3:��B1�׶μ�⵽Ӧ�ò�APP����";
CM_ SG_ 1113 EVCC_BC_B2_ERROR "BC_B2������:
0x1:B2�׶μ�⵽Ӧ�ò�APP����
0x2:B2�׶μ�⵽AEF����";
CM_ SG_ 1113 EVCC_BC_STATE_REQ_TO "0x1:״̬�仯����ʱB->C /C->B";
CM_ SG_ 1113 EVCC_BC_C2_ERROR "BC_C2������:
0x1:C2״̬ʱ��⵽AEF״̬
0x2:C2�׶μ�⵽B״̬
0x3:C2�׶μ�⵽Ӧ�ò����";
CM_ SG_ 1113 EVCC_2_CRC5 "Profile1A:E2E CRC (SAE J1850 CRC-8) for 8 Bytes
DataID:No ASIL requirements.Not configure
CRC Reserved.";
CM_ SG_ 1113 EVCC_2_RollgCntr5 "Profile1A:E2E Rolling message counter(the maximum value of Alive counter is 14)";
CM_ SG_ 1113 EVCC_2_Resd5 "Profile1A:E2E Reserved";
CM_ SG_ 1113 EVCC_BC_EMC_ERROR "BC_EMC������:
0x1:level2�׶�Ӧ�ò㱨��
0x2:level2�׶γ�ʱ
0x3:level3�׶�Ӧ�ò㱨��
0x4:level3�׶γ�ʱ
0x5:��β�׶γ�ʱ";
CM_ SG_ 1113 EVCC_BC_STOP_ERROR "BC_STOP������:
0x1:Ӧ�ò㱨��
0x2:Ӧ�ò㳬ʱ
0x3:��⵽AEF״̬
0x4:״̬����ʱC->B
0x5:��βӦ�ò����
0x6:��β����ʱ";
CM_ SG_ 1113 EVCC_CONNECTING_ERROR "connecting������:
0x1:connecting��ʱ
0x2:��⵽AEF����
0x3:��⵽C״̬
0x4:��⵽��·��ʧ
0x5:�汾Э��ʧ��
0x6:��Ч��SchemaID
0x7:SuppprtedAppProtocol��ʱ";
CM_ SG_ 1113 EVCC_SLEEP_AEF_DETECT "0x1:sleep�׶μ�⵽A/E/F״̬";
CM_ SG_ 1113 EVCC_V2G_REQ_TO_ERROR "V2G request��ʱ������:
0x1:SESSIONSETUP��ʱ
0x2:SERVICEDISCOVERY��ʱ
0x3:SERVICEDETAIL��ʱ
0x4:PAYMENTSERVICESELECTION��ʱ
0x5:PAYMENTDETAILS��ʱ
0x6:AUTHORIZATION��ʱ
0x7:CHARGEPARAMETERDISCOVERY��ʱ
0x8:POWERDELIVERY��ʱ
0x9:CERTIFICATEUPDATE��ʱ
0xA:CERTIFICATEINSTALLATION��ʱ
0xB:SESSIONSTOP��ʱ
0xC:METERINGRECEIPT��ʱ
0xD:CHARGINGSTATUS��ʱ
0xE:CABLECHECK��ʱ
0xF:PRECHARGE��ʱ
0x10:CURRENTDEMAND��ʱ
0x11:WELDINGDETECTION��ʱ";
CM_ SG_ 1113 EVCC_V2G_RES_TO_ERROR "V2G response��ʱ������:
0x1:SESSIONSETUP��ʱ
0x2:SERVICEDISCOVERY��ʱ
0x3:SERVICEDETAIL��ʱ
0x4:PAYMENTSERVICESELECTION��ʱ
0x5:PAYMENTDETAILS��ʱ
0x6:AUTHORIZATION��ʱ
0x7:CHARGEPARAMETERDISCOVERY��ʱ
0x8:POWERDELIVERY��ʱ
0x9:CERTIFICATEUPDATE��ʱ
0xA:CERTIFICATEINSTALLATION��ʱ
0xB:SESSIONSTOP��ʱ
0xC:METERINGRECEIPT��ʱ
0xD:CHARGINGSTATUS��ʱ
0xE:CABLECHECK��ʱ
0xF:PRECHARGE��ʱ
0x10:CURRENTDEMAND��ʱ
0x11:WELDINGDETECTION��ʱ";
CM_ SG_ 1113 EVCC_V2G_ERROR "V2G session������:
0x1:��⵽AEF����
0x2:��⵽��·��ʧ
0x3:��⵽TCP/TLS���Ӷ�ʧ
0x4:����B2�ڼ䣬��⵽״̬B1
0x5:����C2�ڼ䣬��⵽״̬B1\B2\C1
0x6:Ӧ�ò���ִ���
0x7:connecting�׶εļ�ʱ��ʱ
0x8:PWM���д���";
CM_ SG_ 1113 EVCC_SSETUP_ERROR "SessionSetup������:
0x1:Ӧ�ò㴦��req���ĳ���
0x2:req���ͳ���
0x3:�ȴ�res����
0x4:resӦ�ò㴦�����";
CM_ SG_ 1113 EVCC_SDISCOVERY_ERROR "ServiceDiscovery������:
0x1:Ӧ�ò㴦��req���ĳ���
0x2:req���ͳ���
0x3:�ȴ�res����
0x4:resӦ�ò㴦�����";
CM_ SG_ 1113 EVCC_PSS_ERROR "PaymentServiceSelection������:
0x1:Ӧ�ò㴦��req���ĳ���
0x2:req���ͳ���
0x3:�ȴ�res����
0x4:resӦ�ò㴦�����";
CM_ SG_ 1113 EVCC_AUTHORIZATION_ERROR "AUTHORIZATION������:
0x1:Ӧ�ò㴦��req���ĳ���
0x2:req���ͳ���
0x3:�ȴ�res����
0x4:resӦ�ò㴦�����
0x5:ǩ������
0x6:ongoing��ʱ";
CM_ SG_ 1113 EVCC_CPD_ERROR "ChargeParameterDiscovery������:
0x1:Ӧ�ò㴦��req���ĳ���
0x2:req���ͳ���
0x3:�ȴ�res����
0x4:resӦ�ò㴦�����
0x5:ongoing��ʱ";
CM_ SG_ 1113 EVCC_POWERDELIVERY_CP_STATE "0x1:POWERDELIVERY�׶�CP���Ƴ�ʱ";
CM_ SG_ 1113 EVCC_CHARGINGSTATUS_ERROR "ChargingStatus������:
0x1:Ӧ�ò㴦��req���ĳ���
0x2:req���ͳ���
0x3:�ȴ�res����
0x4:resӦ�ò㴦�����";
CM_ SG_ 1113 EVCC_SSTOP_ERROR "SessionStop������:
0x1:Ӧ�ò㴦��req���ĳ���
0x2:req���ͳ���
0x3:�ȴ�res����
0x4:resӦ�ò㴦�����";
CM_ SG_ 1113 EVCC_2_Resd8 "Reserved";
CM_ SG_ 1113 EVCC_2_CRC6 "Profile1A:E2E CRC (SAE J1850 CRC-8) for 8 Bytes
DataID:No ASIL requirements.Not configure
CRC Reserved.";
CM_ SG_ 1113 EVCC_2_RollgCntr6 "Profile1A:E2E Rolling message counter(the maximum value of Alive counter is 14)";
CM_ SG_ 1113 EVCC_2_Resd6 "Profile1A:E2E Reserved";
CM_ SG_ 1113 EVCC_CABLECHECK_ERROR "CableCheck������:
0x1:Ӧ�ò㴦��req���ĳ���
0x2:req���ͳ���
0x3:�ȴ�res����
0x4:resӦ�ò㴦�����
0x5:CableCheck��ʱ
0x6:cp״̬���Ƴ�ʱ";
CM_ SG_ 1113 EVCC_PRECHARGE_ERROR "PreCharge������:
0x1:Ӧ�ò㴦��req���ĳ���
0x2:req���ͳ���
0x3:�ȴ�res����
0x4:resӦ�ò㴦�����
0x5:PreCharge��ʱ";
CM_ SG_ 1113 EVCC_CURRENTDEMAND_ERROR "CurrentDemand������:
0x1:Ӧ�ò㴦��req���ĳ���
0x2:req���ͳ���
0x3:�ȴ�res����
0x4:resӦ�ò㴦�����";
CM_ SG_ 1113 EVCC_WDETECTION_ERROR "WeldingDetectiong������:
0x1:Ӧ�ò㴦��req���ĳ���
0x2:req���ͳ���
0x3:�ȴ�res����
0x4:resӦ�ò㴦�����";
CM_ SG_ 1113 EVCC_V2GTP_ERROR "OSI V2Gtp������:
0x1:�������ݷǷ�
0x2:v2gtp��ͷ���ʹ���
0x3:�������
0x4:V2GTP��ͷversion����
0x5:payload len����";
CM_ SG_ 1113 EVCC_EXI_ERROR "OSI EXI������:
0x1:appHand���ı���ʧ��
0x2:appHand���Ľ���ʧ��
0x3:һ�㱨�ı���ʧ��
0x4:һ�㱨�Ľ���ʧ��
0x5:din����ʧ��
0x6:din����ʧ��";
CM_ SG_ 1113 EVCC_NET_ERROR "OSI NET������:
0x1:udp�׶�setsocketopt����
0x2:udp�׶�bind����
0x3:udp�׶Σ�send���ʹ���
0x4:tcp�׶Σ���ȡ�׽��ִ���
0x5:tcp�׶Σ�����ʧ��
0x6:tcp�׶Σ��������ݴ���
0x7:udp�׶Σ�recv����
0x8:sdp res��ͷ����
0x9:sdp res ���ȴ���
0xA:sdp ����Ҫ��ƥ��
0xB:����������";
CM_ SG_ 1113 EVCC_EMC_ERROR "��ͣ������:
0x1:������ͣʧ��
0x2:������ͣ��ʱ
0x3:������ͣʧ��
0x4:������ͣ��ʱ
0x5:��β����ʧ��
0x6:��β������ʱ";
CM_ SG_ 1113 EVCC_DIN_ERROR "DinSession������:
0x1:DINSESSIONû����ͣ��ȴ��ȡ����ͣ����
0x2:��ģ�鷵���˴���
0x3:��⵽AEF����
0x4:PWM������Ч
0x5:���ĳ�ʱ
0x6:SLAC����
0x7:����Ͽ�
0x8:msg ���������������
0x9:����C2�ڼ��������״̬
0xA:Ӧ�ò㱨����
0xB:70121��ReadyToCharge��ʱ
0xC:70121��CommunicationSetup��ʱ
0xD:�ڻỰ�г���B1״̬";
CM_ SG_ 1113 EVCC_DIN_SSETUP_ERROR "Din SessionSetup������:
0x1:APP req�׶δ���
0x2:���ķ���ʧ��
0x3:�յ��Ļظ���������
0x4:respondCode = �������д���
0x5:respondCode = fail, pwm=off���쳣
0x6:app res �׶δ���";
CM_ SG_ 1113 EVCC_DIN_SDISCOVERY_ERROR "Din ServiceDiscovery������:
0x1:APP req�׶δ���
0x2:���ķ���ʧ��
0x3:�յ��Ļظ���������
0x4:respondCode = �������д���
0x5:respondCode = fail, pwm=off���쳣
0x6:app res �׶δ���";
CM_ SG_ 1113 EVCC_DIN_SPS_ERROR "Din ServicePaymentSelection������:
0x1:APP req�׶δ���
0x2:���ķ���ʧ��
0x3:�յ��Ļظ���������
0x4:respondCode = �������д���
0x5:respondCode = fail, pwm=off���쳣
0x6:app res �׶δ���";
CM_ SG_ 1113 EVCC_DIN_CAUTHENTICATION_ERROR "Din ContractAuthentication������:
0x1:APP req�׶δ���
0x2:���ķ���ʧ��
0x3:�յ��Ļظ���������
0x4:respondCode = �������д���
0x5:respondCode = fail, pwm=off���쳣
0x6:app res �׶δ���
0x7:CAUTHENTICATION������ʱ";
CM_ SG_ 1113 EVCC_DIN_CPD_ERROR "Din ChargeParameterDiscovery������:
0x1:APP req�׶δ���
0x2:���ķ���ʧ��
0x3:�յ��Ļظ���������
0x4:�����˴�����
0x5:app res �׶δ���
0x6:CPD������ʱ";
CM_ SG_ 1113 EVCC_2_Resd9 "Reserved";
CM_ SG_ 1113 EVCC_DIN_CABLECHECK_ERROR "Din CableCheck������:
0x1:APP req�׶δ���
0x2:���ķ���ʧ��
0x3:�յ��Ļظ���������
0x4:�����˴�����
0x5:app res �׶δ���
0x6:CableCheck������ʱ
0x7:״̬���Ƴ�ʱ";
CM_ SG_ 1113 EVCC_2_CRC7 "Profile1A:E2E CRC (SAE J1850 CRC-8) for 8 Bytes
DataID:No ASIL requirements.Not configure
CRC Reserved.";
CM_ SG_ 1113 EVCC_2_RollgCntr7 "Profile1A:E2E Rolling message counter(the maximum value of Alive counter is 14)";
CM_ SG_ 1113 EVCC_2_Resd7 "Profile1A:E2E Reserved";
CM_ SG_ 1113 EVCC_DIN_PRECHARGE_ERROR "Din PreCharge������:
0x1:APP req�׶δ���
0x2:���ķ���ʧ��
0x3:�յ��Ļظ���������
0x4:�����˴�����
0x5:app res �׶δ���
0x6:precharge������ʱ";
CM_ SG_ 1113 EVCC_DIN_POWERDELIVERY_ERROR "Din PowerDelivery������:
0x1:APP req�׶δ���
0x2:���ķ���ʧ��
0x3:�յ��Ļظ���������
0x4:�����˴�����
0x5:app res �׶δ���
0x6:״̬���Ƴ�ʱ";
CM_ SG_ 1113 EVCC_DIN_CURRENTDEMAND_ERROR "Din CurrentDemand������:
0x1:APP req�׶δ���
0x2:���ķ���ʧ��
0x3:�յ��Ļظ���������
0x4:�����˴�����
0x5:app res �׶δ���";
CM_ SG_ 1113 EVCC_DIN_WDETECTION_ERROR "Din WeldingDetection������:
0x1:APP req�׶δ���
0x2:���ķ���ʧ��
0x3:�յ��Ļظ���������
0x4:�����˴�����
0x5:app res �׶δ���";
CM_ SG_ 1113 EVCC_DIN_SSTOP_ERROR "Din SessionStop������:
0x1:APP req�׶δ���
0x2:���ķ���ʧ��
0x3:�յ��Ļظ���������
0x4:�����˴�����
0x5:app res �׶δ���
0x6:״̬���Ƴ�ʱ";
CM_ SG_ 1113 EVCC_DIN_METERINGRECEIPT_ERROR "MeteringReceipt������:
0x1:Ӧ�ò㴦��req���ĳ���
0x2:req���ͳ���
0x3:�ȴ�res����
0x4:resӦ�ò㴦�����";
CM_ SG_ 1113 EVCC_SLAC_RETRY_TIMEOUT "0x1:����ʱ�䳬ʱ";
CM_ SG_ 1113 EVCC_SLAC_AMPMAP_ERROR "SLAC-AmpMap������
0x1:����AMPMAP CNF���ĳ�ʱ
0x2:AMPMAP���󳬹����Դ���
0x3:AMPMAP CNF��������";
CM_ SG_ 1113 EVCC_SLAC_ATTEN_ERROR "SLAC-Atten������
0x1:SLAC��û�з�����Ч��SECC
0x2:PARA CNF��������";
CM_ SG_ 1113 EVCC_SLAC_BCB_FAILED "0x1:BCB����ʧ�ܣ�û���ҵ���Ч��SECC";
CM_ SG_ 1113 EVCC_SLAC_JOIN_ERROR "SLAC-Join������
0x1:SlacMatchReq ���󳬹����Դ���
0x2:Set Key ���󳬹����Դ���
0x3:SLAC �������糬ʱ 
0x4:SlacMatchCnf ��������";
CM_ SG_ 1113 EVCC_SLAC_PAUSE_RETRY_OVERFLOW "0x1:SLAC��ͣ�׶Σ�set key�������Դ���";
CM_ SG_ 1113 EVCC_SLAC_RESUME_ERROR "SLAC-Resume������
0x1:SLAC�ָ����ӽ׶Σ�set key�������Դ���
0x2:SLAC �ָ����ӽ׶Σ��������糬ʱ";
CM_ SG_ 1113 EVCC_SLAC_ETH_ERROR "SLAC-Eth������
0x1:SLAC ������̫��֡���ȴ���
0x2:SLAC ������̫��֡��ʽ����
0x3:SLAC ������̫��MAC��ַ����";
CM_ SG_ 1113 EVCC_SLAC_DISLINK_RETRY_OVERFLOW "0x1:DisLink�׶Σ�set key�������Դ���";
CM_ SG_ 1113 EVCC_SLAC_INIT_RETRY_OVERFLOW "0x1:SLAC��ʼ���׶Σ���ȡ�汾��Ϣ�������Դ���";
CM_ SG_ 1113 EVCC_APP_PSS_ERROR "CPCM - PaymentServiceSelection������
0x1:res���ĵ�response����
0x2:�������ļ���������";
CM_ SG_ 1113 EVCC_APP_CPD_ERROR "CPCM - CHARGEPARAMETERDISCOVERY������
0x1:������Ӧ��mid��req���ĳ���
0x2:����res���ݴ���
0x3:������Ӧ��mid���res���ĳ���";
CM_ SG_ 1113 EVCC_APP_DTC_ERROR "CPCM - Err Detect������
0x1:ǹ��״̬����
0x2:CCPC�����Ҫ��ֹͣ
0x3:CCPC��Ϊ����ֹͣ";
CM_ SG_ 1113 EVCC_DIN_CCPC_ERROR "Din CCPC������
0x1:EVSE��С��ѹ��EV������ѹ��Ҫ��
0x2:EVSE��С������EV����������Ҫ��
0x3:���׮��ͣ
0x4:���׮��������";
CM_ SG_ 1113 EVCC_V2G_CCPC_ERROR "V2G CCPC������
0x1:EVSE��С��ѹ��EV������ѹ��Ҫ��
0x2:EVSE��С������EV����������Ҫ��
0x3:���׮��ͣ
0x4:���׮��������";
CM_ SG_ 1113 EVCC_GunConnectSt "���ǹ����״̬
0-δ����
1-������
2-�����쳣";
CM_ SG_ 1113 EVCC_ElectronicLockRes "�����������ź�ʵʱ��ֵ";
CM_ SG_ 1113 EVCC_ElectronicLockSignal_Rel "EVCC���Ƶ�������������";
CM_ SG_ 1113 EVCC_PLCNodeFwVer "PLC�̼��汾��";
CM_ SG_ 1113 EVCC_BatVolConfig "EVCC��������ѹƽ̨�����ź�";
CM_ SG_ 1113 EVCC_2_Resd10 "Reserved";
CM_ SG_ 571 FLZCU_1_CRC "Profile1A:E2E CRC (SAE J1850 CRC-8) for 8 Bytes
DataID:0x0036";
CM_ SG_ 571 FLZCU_1_RollgCntr "Profile1A:E2E Rolling message counter(the maximum value of Alive counter is 14)";
CM_ SG_ 571 FLZCU_1_Resd "Profile1A:E2E Reserved";
CM_ SG_ 603 FLZCU_2_CRC "Profile1A:E2E CRC (SAE J1850 CRC-8) for 8 Bytes
DataID:0x00A0";
CM_ SG_ 603 FLZCU_2_RollgCntr "Profile1A:E2E Rolling message counter(the maximum value of Alive counter is 14)";
CM_ SG_ 603 FLZCU_2_Resd "Profile1A:E2E Reserved";
CM_ SG_ 603 FLZCU_2_PowerMode "��ѹ��Դ״̬";
CM_ SG_ 1181 FLZCU_9_CRC "Profile1A:E2E CRC (SAE J1850 CRC-8) for 8 Bytes
DataID:0x009C";
CM_ SG_ 1181 FLZCU_9_RollgCntr "Profile1A:E2E Rolling message counter(the maximum value of Alive counter is 14)";
CM_ SG_ 1181 FLZCU_9_Resd1 "Profile1A:E2E Reserved";
CM_ SG_ 1181 FLZCU_9_PowerMode "��ѹ��Դ״̬";
CM_ SG_ 1181 FLZCU_9_EleclctroicLockReq "CDU�������пؽ���
����һ����������10֡��֮�󷵻�0x0";
CM_ SG_ 692 FRZCU_3_ClntTHvBattIn "battery inlet temperature";
CM_ SG_ 692 FRZCU_3_ClntTHvBattOut "battery oulet temperature";
CM_ SG_ 692 FRZCU_3_DCPortTemp_P "fast charge port pos cable temperature";
CM_ SG_ 692 FRZCU_3_DCPortTemp_N "fast charge port neg cable temperature";
CM_ SG_ 692 FRZCU_3_CLMHVILFault "CLM HVIL fault";
CM_ SG_ 692 FRZCU_3_HvilChkFltSt "��ѹ��������·������Ϣ";
CM_ SG_ 469 FMCU_1_CRC1 "Profile1A:E2E CRC (SAE J1850 CRC-8) for 8 Bytes
DataID:0x003C";
CM_ SG_ 469 FMCU_1_RollgCntr1 "Profile1A:E2E Rolling message counter(the maximum value of Alive counter is 14)";
CM_ SG_ 469 FMCU_1_Resd1 "Profile1A:E2E Reserved";
CM_ SG_ 469 FMCU_TorqMax "avaialbe/allowed maximum drive torque ���ݵ�ѹ����ĵ�������С����
��;D01�����ź����ֵ��Ϊ400���������ֵ��Ϊ0x640";
CM_ SG_ 469 FMCU_TorqMin "avaialbe/allowed minimum regenrative torque ���ݵ�ѹ����ĵ�������С����
��;D01�����ź���Сֵ��Ϊ-400���������ֵ��Ϊ0x640";
CM_ SG_ 469 FMCU_TorqAct "FMCU motor actual torque
��;D01�����ź����ֵ��Сֵ��Ϊ400��-400���������ֵ��Ϊ0xC80";
CM_ SG_ 469 FMCU_ModeSt "actual state of FMCU motor";
CM_ SG_ 469 FMCU_1_CRC2 "Profile1A:E2E CRC (SAE J1850 CRC-8) for 8 Bytes
DataID:0x003D";
CM_ SG_ 469 FMCU_1_RollgCntr2 "Profile1A:E2E Rolling message counter(the maximum value of Alive counter is 14)";
CM_ SG_ 469 FMCU_1_Resd2 "Profile1A:E2E Reserved";
CM_ SG_ 469 FMCU_SpdAct "FMCU motor actual speed";
CM_ SG_ 469 FMCU_TrqActDampingReq "Active damping requirement";
CM_ SG_ 469 FMCU_FMCUDeratSts "FMCU derating status";
CM_ SG_ 469 FMCU_UdcAct "actual bus voltage";
CM_ SG_ 469 FMCU_1_CRC3 "Profile1A:E2E CRC (SAE J1850 CRC-8) for 8 Bytes
DataID:0x003E";
CM_ SG_ 469 FMCU_1_RollgCntr3 "Profile1A:E2E Rolling message counter(the maximum value of Alive counter is 14)";
CM_ SG_ 469 FMCU_1_Resd3 "Profile1A:E2E Reserved";
CM_ SG_ 469 FMCU_IdcAct "actual HV current at generator";
CM_ SG_ 469 FMCU_ErrLvl "Error Level";
CM_ SG_ 469 FMCU_InterlockStatus "Interlock Status
0x0:Not Interlock (Fault) 
0x1:Interlock (Not Fault)";
CM_ SG_ 469 FMCU_DampActive "Damping state of FMCU motor";
CM_ SG_ 469 FMCU_E_ClutchErrLvl "�����������ϵȼ�";
CM_ SG_ 469 FMCU_E_ClutchActMod "0x0: open mode(������Ͽ�)
0x1: peak mode(���������)
0x2: hold mode(�������������)
0x3: peak timeout
��MCU�յ�peak modeָ���5sʱ����û���յ�hold modeָ�MCU�����״̬���Ͽ�����������Ȧ��
0x4��Fault mode";
CM_ SG_ 469 FMCU_E_ClutchStus "��������״̬";
CM_ SG_ 469 FMCU_E_ClutchCurr "����������Ȧ����+AD49";
CM_ SG_ 469 FMCU_E_ClutchEngMilLampReq "���������������MIL���ϵ�";
CM_ SG_ 469 FMCU_NegTrqAvailMin_2s "2s�������ź���Ϊ�˱����������Ť��Ԥ�⣬ֻ�Ǹ��ݵ���¶����ı���";
CM_ SG_ 469 FMCU_PosTrqAvailMax_2s "2s�������ź���Ϊ�˱����������Ť��Ԥ�⣬ֻ�Ǹ��ݵ���¶����ı���";
CM_ SG_ 1115 FMCU_2_CRC "Profile1A:E2E CRC (SAE J1850 CRC-8) for 8 Bytes
DataID:0x003F";
CM_ SG_ 1115 FMCU_2_RollgCntr "Profile1A:E2E Rolling message counter(the maximum value of Alive counter is 14)";
CM_ SG_ 1115 FMCU_2_Resd "Profile1A:E2E Reserved";
CM_ SG_ 1115 FMCU_InvTemp "Inverter temperature";
CM_ SG_ 1115 FMCU_RotorTemperature "Rotor Temperature";
CM_ SG_ 1115 FMCU_StatTemp "Motor stator temperature(NTC, measurement)";
CM_ SG_ 1115 FMCU_Ratio "Gearbox Ratio";
CM_ SG_ 1115 FMCU_InvSampTemp "Inverter temperature";
CM_ SG_ 1118 FMCU_Fault1 "refre to DTC Matrix:FMCU Fault ErroCode1";
CM_ SG_ 1118 FMCU_Fault2 "refre to DTC Matrix:FMCU Fault ErroCode2";
CM_ SG_ 1118 FMCU_Fault3 "refre to DTC Matrix:FMCU Fault ErroCode3";
CM_ SG_ 1118 FMCU_Fault4 "refre to DTC Matrix:FMCU Fault ErroCode4";
CM_ SG_ 1088 FMCU_WPhaseCurrent "W Phase current";
CM_ SG_ 1088 FMCU_VPhaseCurrent "V Phase current";
CM_ SG_ 1088 FMCU_UPhaseCurrent "U Phase current";
CM_ SG_ 1088 FMCU_4_SWInfo "�汾��Ϣ������variant��), �������ּ��,ǰ�ĸ�Bit��ʾ��Ӧ�̣����ĸ���ʾvariant";
CM_ SG_ 1088 FMCU_4_CRC "Profile1A:E2E CRC (SAE J1850 CRC-8) for 8 Bytes
DataID:0x0084";
CM_ SG_ 1088 FMCU_4_RollgCntr "Profile1A:E2E Rolling message counter(the maximum value of Alive counter is 14)";
CM_ SG_ 1088 FMCU_4_Resd "Profile1A:E2E Reserved";
CM_ SG_ 1088 FMCU_TempW "Temperature of phase W of NTC";
CM_ SG_ 1088 FMCU_TempV "Temperature of phase V of NTC";
CM_ SG_ 1088 FMCU_TempU "Temperature of phase U of NTC";
CM_ SG_ 1088 FMCU_CoolantTemp "Temperature of inverter cooling water";
CM_ SG_ 1088 FMCU_Delta_TJ_Coolant "Temperature of Tj minus coolant";
CM_ SG_ 1088 FMCU_IGBTmode "Motor drive state";

BA_DEF_ BO_  "NmMessage" ENUM "No","Yes";
BA_DEF_ BO_  "DiagState" ENUM  "No","Yes";
BA_DEF_ BO_  "GenMsgSendType" ENUM  "Cyclic","Event","IfActive","CE","CA","NoMsgSendType";
BA_DEF_ BO_  "GenMsgCycleTime" INT 0 0;
BA_DEF_ SG_  "GenSigSendType" ENUM  "Cyclic","OnChange","OnWrite","IfActive","OnChangeWithRepetition","OnWriteWithRepetition","IfActiveWithRepetition","NoSigSendType","OnChangeAndIfActive","OnChangeAndIfActiveWithRepetition","CA","CE","Event";
BA_DEF_ SG_  "GenSigStartValue" INT 0 0;
BA_DEF_ SG_  "GenSigInactiveValue" INT 0 0;
BA_DEF_ BO_  "GenMsgCycleTimeFast" INT 0 0;
BA_DEF_ BO_  "GenMsgNrOfRepetition" INT 0 0;
BA_DEF_ BO_  "GenMsgDelayTime" INT 0 0;
BA_DEF_ BO_  "CANFD_BRS" ENUM  "0","1";
BA_DEF_ BO_  "VFrameFormat" ENUM  "StandardCAN","ExtendedCAN","reserved","reserved","reserved","reserved","reserved","reserved","reserved","reserved","reserved","reserved","reserved","reserved","StandardCAN_FD","ExtendedCAN_FD";
BA_DEF_ BO_  "GenMsgILSupport" ENUM  "No","Yes";
BA_DEF_ SG_ "GenSigASIL" ENUM "QM","A","B","C","D","";
BA_DEF_DEF_  "NmMessage" "No";
BA_DEF_DEF_  "DiagState" "No";
BA_DEF_DEF_  "GenMsgSendType" "Cyclic";
BA_DEF_DEF_  "GenMsgCycleTime" 0;
BA_DEF_DEF_  "GenSigSendType" "Cyclic";
BA_DEF_DEF_  "GenSigStartValue" 0;
BA_DEF_DEF_  "GenSigInactiveValue" 0;
BA_DEF_DEF_  "GenMsgCycleTimeFast" 0;
BA_DEF_DEF_  "GenMsgNrOfRepetition" 0;
BA_DEF_DEF_  "GenMsgDelayTime" 0;
BA_DEF_DEF_  "CANFD_BRS" "1";
BA_DEF_DEF_  "VFrameFormat" "StandardCAN_FD";
BA_DEF_DEF_  "GenMsgILSupport" "No";
BA_DEF_DEF_ "GenSigASIL" "QM";
BA_ "GenMsgILSupport" BO_ 515 1;
BA_ "GenMsgCycleTime" BO_ 515 20;
BA_ "GenSigASIL"  SG_ 515 EVCC_1_CRC1 5;
BA_ "GenSigASIL"  SG_ 515 EVCC_1_RollgCntr1 5;
BA_ "GenSigASIL"  SG_ 515 EVCC_1_Resd1 5;
BA_ "GenSigASIL"  SG_ 515 EVCC_GunConnectSt 1;
BA_ "GenSigASIL"  SG_ 515 EVCC_ElectronicLockSts 1;
BA_ "GenSigASIL"  SG_ 515 EVCC_PPCode 5;
BA_ "GenSigASIL"  SG_ 515 EVCC_CC_RCR4_Sts 5;
BA_ "GenSigASIL"  SG_ 515 EVCC_CP_DutyCycleFault 1;
BA_ "GenSigASIL"  SG_ 515 EVCC_COUNTRY_SUPPORT 5;
BA_ "GenSigASIL"  SG_ 515 EVCC_CP_DutyCycleValue 1;
BA_ "GenSigASIL"  SG_ 515 EVCC_CPSts 1;
BA_ "GenSigASIL"  SG_ 515 EVCC_S2Swtsts 1;
BA_ "GenSigASIL"  SG_ 515 EVCC_CC_ConnectSts 1;
BA_ "GenSigASIL"  SG_ 515 EVCC_CC_ConnectDischarSts 1;
BA_ "GenSigASIL"  SG_ 515 EVCC_CC2_ConnectSts 1;
BA_ "GenSigASIL"  SG_ 515 EVCC_CC2_Alarm 1;
BA_ "GenSigASIL"  SG_ 515 EVCC_ChargeType 1;
BA_ "GenSigASIL"  SG_ 515 EVCC_1_CRC2 5;
BA_ "GenSigASIL"  SG_ 515 EVCC_1_RollgCntr2 5;
BA_ "GenSigASIL"  SG_ 515 EVCC_1_Resd2 5;
BA_ "GenSigASIL"  SG_ 515 EVCC_FaultLevel 1;
BA_ "GenSigASIL"  SG_ 515 EVCC_CPMaxVolt 5;
BA_ "GenSigStartValue" SG_ 515 EVCC_DCPlusTemp 254;
BA_ "GenSigASIL"  SG_ 515 EVCC_DCPlusTemp 5;
BA_ "GenSigStartValue" SG_ 515 EVCC_DCMinusTemp 254;
BA_ "GenSigASIL"  SG_ 515 EVCC_DCMinusTemp 5;
BA_ "GenSigASIL"  SG_ 515 EVCC_TotalFaultNum 5;
BA_ "GenSigASIL"  SG_ 515 EVCC_1_Resd4 5;
BA_ "GenSigASIL"  SG_ 515 EVCC_FaultNum1 5;
BA_ "GenSigASIL"  SG_ 515 EVCC_1_CRC3 5;
BA_ "GenSigASIL"  SG_ 515 EVCC_1_RollgCntr3 5;
BA_ "GenSigASIL"  SG_ 515 EVCC_1_Resd3 5;
BA_ "GenSigASIL"  SG_ 515 EVCC_FaultNum2 5;
BA_ "GenSigASIL"  SG_ 515 EVCC_CPVolt 1;
BA_ "GenSigASIL"  SG_ 515 EVCC_PPRes 1;
BA_ "GenSigASIL"  SG_ 515 EVCC_ChargingStage 5;
BA_ "GenMsgILSupport" BO_ 1113 1;
BA_ "GenMsgCycleTime" BO_ 1113 100;
BA_ "GenSigASIL"  SG_ 1113 EVCC_PLCAvgAttenuation 5;
BA_ "GenSigASIL"  SG_ 1113 EVCC_StopChrgnReason 5;
BA_ "GenSigASIL"  SG_ 1113 EVCC_A_POSITIVE 5;
BA_ "GenSigASIL"  SG_ 1113 EVCC_SupplierCode 5;
BA_ "GenSigASIL"  SG_ 1113 EVCC_HwVersion 5;
BA_ "GenSigASIL"  SG_ 1113 EVCC_SwMajorVersion 5;
BA_ "GenSigASIL"  SG_ 1113 EVCC_SwMinorVersion 5;
BA_ "GenSigASIL"  SG_ 1113 EVCC_SwPatchVersion 5;
BA_ "GenSigASIL"  SG_ 1113 EVCC_2_CRC2 5;
BA_ "GenSigASIL"  SG_ 1113 EVCC_2_RollgCntr2 5;
BA_ "GenSigASIL"  SG_ 1113 EVCC_2_Resd2 5;
BA_ "GenSigASIL"  SG_ 1113 EVCC_SwVersionYear 5;
BA_ "GenSigASIL"  SG_ 1113 EVCC_SwVersionMonth 5;
BA_ "GenSigASIL"  SG_ 1113 EVCC_SwVersionDay 5;
BA_ "GenSigASIL"  SG_ 1113 EVSE_MaxVol 5;
BA_ "GenSigASIL"  SG_ 1113 EVCC_GB_RX_ERROR 5;
BA_ "GenSigASIL"  SG_ 1113 EVCC_GB_CHM_ERROR 5;
BA_ "GenSigASIL"  SG_ 1113 EVCC_GB_CML_ERROR 5;
BA_ "GenSigASIL"  SG_ 1113 EVCC_APP_DM_ERROR 5;
BA_ "GenSigASIL"  SG_ 1113 EVCC_2_CRC3 5;
BA_ "GenSigASIL"  SG_ 1113 EVCC_2_RollgCntr3 5;
BA_ "GenSigASIL"  SG_ 1113 EVCC_2_Resd3 5;
BA_ "GenSigASIL"  SG_ 1113 EVSE_MinVol 5;
BA_ "GenSigASIL"  SG_ 1113 EVSE_MaxCur 5;
BA_ "GenSigASIL"  SG_ 1113 EVSE_MinCur 5;
BA_ "GenSigASIL"  SG_ 1113 EVCC_GB_SPECIAL_ERROR 5;
BA_ "GenSigASIL"  SG_ 1113 EVCC_GB_CRM_ERROR 5;
BA_ "GenSigASIL"  SG_ 1113 EVCC_GB_CRO_ERROR 5;
BA_ "GenSigASIL"  SG_ 1113 EVCC_GB_CCS_ERROR 5;
BA_ "GenSigASIL"  SG_ 1113 EVCC_GB_CST_ERROR 5;
BA_ "GenSigASIL"  SG_ 1113 EVCC_GB_CSD_ERROR 5;
BA_ "GenSigASIL"  SG_ 1113 EVCC_2_CRC4 5;
BA_ "GenSigASIL"  SG_ 1113 EVCC_2_RollgCntr4 5;
BA_ "GenSigASIL"  SG_ 1113 EVCC_2_Resd4 5;
BA_ "GenSigASIL"  SG_ 1113 EVSE_MaxPwr 5;
BA_ "GenSigASIL"  SG_ 1113 EVSE_OutputVol 5;
BA_ "GenSigASIL"  SG_ 1113 EVSE_OutputCur 5;
BA_ "GenSigASIL"  SG_ 1113 EVCC_MATCHING_ERROR 5;
BA_ "GenSigASIL"  SG_ 1113 EVCC_MATCHED_ERROR 5;
BA_ "GenSigASIL"  SG_ 1113 EVCC_BC_B1_ERROR 5;
BA_ "GenSigASIL"  SG_ 1113 EVCC_BC_B2_ERROR 5;
BA_ "GenSigASIL"  SG_ 1113 EVCC_BC_STATE_REQ_TO 5;
BA_ "GenSigASIL"  SG_ 1113 EVCC_BC_C2_ERROR 5;
BA_ "GenSigASIL"  SG_ 1113 EVCC_2_CRC5 5;
BA_ "GenSigASIL"  SG_ 1113 EVCC_2_RollgCntr5 5;
BA_ "GenSigASIL"  SG_ 1113 EVCC_2_Resd5 5;
BA_ "GenSigASIL"  SG_ 1113 EVCC_BC_EMC_ERROR 5;
BA_ "GenSigASIL"  SG_ 1113 EVCC_BC_STOP_ERROR 5;
BA_ "GenSigASIL"  SG_ 1113 EVCC_CONNECTING_ERROR 5;
BA_ "GenSigASIL"  SG_ 1113 EVCC_SLEEP_AEF_DETECT 5;
BA_ "GenSigASIL"  SG_ 1113 EVCC_V2G_REQ_TO_ERROR 5;
BA_ "GenSigASIL"  SG_ 1113 EVCC_V2G_RES_TO_ERROR 5;
BA_ "GenSigASIL"  SG_ 1113 EVCC_V2G_ERROR 5;
BA_ "GenSigASIL"  SG_ 1113 EVCC_SSETUP_ERROR 5;
BA_ "GenSigASIL"  SG_ 1113 EVCC_SDISCOVERY_ERROR 5;
BA_ "GenSigASIL"  SG_ 1113 EVCC_PSS_ERROR 5;
BA_ "GenSigASIL"  SG_ 1113 EVCC_AUTHORIZATION_ERROR 5;
BA_ "GenSigASIL"  SG_ 1113 EVCC_CPD_ERROR 5;
BA_ "GenSigASIL"  SG_ 1113 EVCC_POWERDELIVERY_CP_STATE 5;
BA_ "GenSigASIL"  SG_ 1113 EVCC_CHARGINGSTATUS_ERROR 5;
BA_ "GenSigASIL"  SG_ 1113 EVCC_SSTOP_ERROR 5;
BA_ "GenSigASIL"  SG_ 1113 EVCC_2_Resd8 5;
BA_ "GenSigASIL"  SG_ 1113 EVCC_2_CRC6 5;
BA_ "GenSigASIL"  SG_ 1113 EVCC_2_RollgCntr6 5;
BA_ "GenSigASIL"  SG_ 1113 EVCC_2_Resd6 5;
BA_ "GenSigASIL"  SG_ 1113 EVCC_CABLECHECK_ERROR 5;
BA_ "GenSigASIL"  SG_ 1113 EVCC_PRECHARGE_ERROR 5;
BA_ "GenSigASIL"  SG_ 1113 EVCC_CURRENTDEMAND_ERROR 5;
BA_ "GenSigASIL"  SG_ 1113 EVCC_WDETECTION_ERROR 5;
BA_ "GenSigASIL"  SG_ 1113 EVCC_V2GTP_ERROR 5;
BA_ "GenSigASIL"  SG_ 1113 EVCC_EXI_ERROR 5;
BA_ "GenSigASIL"  SG_ 1113 EVCC_NET_ERROR 5;
BA_ "GenSigASIL"  SG_ 1113 EVCC_EMC_ERROR 5;
BA_ "GenSigASIL"  SG_ 1113 EVCC_DIN_ERROR 5;
BA_ "GenSigASIL"  SG_ 1113 EVCC_DIN_SSETUP_ERROR 5;
BA_ "GenSigASIL"  SG_ 1113 EVCC_DIN_SDISCOVERY_ERROR 5;
BA_ "GenSigASIL"  SG_ 1113 EVCC_DIN_SPS_ERROR 5;
BA_ "GenSigASIL"  SG_ 1113 EVCC_DIN_CAUTHENTICATION_ERROR 5;
BA_ "GenSigASIL"  SG_ 1113 EVCC_DIN_CPD_ERROR 5;
BA_ "GenSigASIL"  SG_ 1113 EVCC_2_Resd9 5;
BA_ "GenSigASIL"  SG_ 1113 EVCC_DIN_CABLECHECK_ERROR 5;
BA_ "GenSigASIL"  SG_ 1113 EVCC_2_CRC7 5;
BA_ "GenSigASIL"  SG_ 1113 EVCC_2_RollgCntr7 5;
BA_ "GenSigASIL"  SG_ 1113 EVCC_2_Resd7 5;
BA_ "GenSigASIL"  SG_ 1113 EVCC_DIN_PRECHARGE_ERROR 5;
BA_ "GenSigASIL"  SG_ 1113 EVCC_DIN_POWERDELIVERY_ERROR 5;
BA_ "GenSigASIL"  SG_ 1113 EVCC_DIN_CURRENTDEMAND_ERROR 5;
BA_ "GenSigASIL"  SG_ 1113 EVCC_DIN_WDETECTION_ERROR 5;
BA_ "GenSigASIL"  SG_ 1113 EVCC_DIN_SSTOP_ERROR 5;
BA_ "GenSigASIL"  SG_ 1113 EVCC_DIN_METERINGRECEIPT_ERROR 5;
BA_ "GenSigASIL"  SG_ 1113 EVCC_SLAC_RETRY_TIMEOUT 5;
BA_ "GenSigASIL"  SG_ 1113 EVCC_SLAC_AMPMAP_ERROR 5;
BA_ "GenSigASIL"  SG_ 1113 EVCC_SLAC_ATTEN_ERROR 5;
BA_ "GenSigASIL"  SG_ 1113 EVCC_SLAC_BCB_FAILED 5;
BA_ "GenSigASIL"  SG_ 1113 EVCC_SLAC_JOIN_ERROR 5;
BA_ "GenSigASIL"  SG_ 1113 EVCC_SLAC_PAUSE_RETRY_OVERFLOW 5;
BA_ "GenSigASIL"  SG_ 1113 EVCC_SLAC_RESUME_ERROR 5;
BA_ "GenSigASIL"  SG_ 1113 EVCC_SLAC_ETH_ERROR 5;
BA_ "GenSigASIL"  SG_ 1113 EVCC_SLAC_DISLINK_RETRY_OVERFLOW 5;
BA_ "GenSigASIL"  SG_ 1113 EVCC_SLAC_INIT_RETRY_OVERFLOW 5;
BA_ "GenSigASIL"  SG_ 1113 EVCC_APP_PSS_ERROR 5;
BA_ "GenSigASIL"  SG_ 1113 EVCC_APP_CPD_ERROR 5;
BA_ "GenSigASIL"  SG_ 1113 EVCC_APP_DTC_ERROR 5;
BA_ "GenSigASIL"  SG_ 1113 EVCC_DIN_CCPC_ERROR 5;
BA_ "GenSigASIL"  SG_ 1113 EVCC_V2G_CCPC_ERROR 5;
BA_ "GenSigASIL"  SG_ 1113 EVCC_GunConnectSt 5;
BA_ "GenSigStartValue" SG_ 1113 EVCC_ElectronicLockRes 65535;
BA_ "GenSigASIL"  SG_ 1113 EVCC_ElectronicLockRes 5;
BA_ "GenSigASIL"  SG_ 1113 EVCC_ElectronicLockSignal_Rel 5;
BA_ "GenSigASIL"  SG_ 1113 EVCC_PLCNodeFwVer 5;
BA_ "GenSigASIL"  SG_ 1113 EVCC_BatVolConfig 5;
BA_ "GenSigASIL"  SG_ 1113 EVCC_2_Resd10 5;
BA_ "GenMsgILSupport" BO_ 571 1;
BA_ "GenMsgCycleTime" BO_ 571 20;
BA_ "GenSigASIL"  SG_ 571 FLZCU_1_CRC 5;
BA_ "GenSigASIL"  SG_ 571 FLZCU_1_RollgCntr 5;
BA_ "GenSigASIL"  SG_ 571 FLZCU_1_Resd 5;
BA_ "GenSigASIL"  SG_ 571 HoodSts 1;
BA_ "GenSigASIL"  SG_ 571 LHFdoorSts 1;
BA_ "GenMsgILSupport" BO_ 603 1;
BA_ "GenMsgCycleTime" BO_ 603 20;
BA_ "GenSigASIL"  SG_ 603 FLZCU_2_CRC 5;
BA_ "GenSigASIL"  SG_ 603 FLZCU_2_RollgCntr 5;
BA_ "GenSigASIL"  SG_ 603 FLZCU_2_Resd 5;
BA_ "GenSigASIL"  SG_ 603 FLZCU_2_PowerMode 3;
BA_ "GenMsgILSupport" BO_ 1181 1;
BA_ "GenMsgCycleTime" BO_ 1181 100;
BA_ "GenSigASIL"  SG_ 1181 FLZCU_9_CRC 5;
BA_ "GenSigASIL"  SG_ 1181 FLZCU_9_RollgCntr 5;
BA_ "GenSigASIL"  SG_ 1181 FLZCU_9_Resd1 5;
BA_ "GenSigASIL"  SG_ 1181 FLZCU_9_PowerMode 2;
BA_ "GenSigASIL"  SG_ 1181 FLZCU_9_EleclctroicLockReq 5;
BA_ "GenSigASIL"  SG_ 1181 FLZCU_9_CentralLockingReq 5;
BA_ "GenMsgILSupport" BO_ 692 1;
BA_ "GenMsgCycleTime" BO_ 692 20;
BA_ "GenSigStartValue" SG_ 692 FRZCU_3_ClntTHvBattIn 254;
BA_ "GenSigASIL"  SG_ 692 FRZCU_3_ClntTHvBattIn 5;
BA_ "GenSigStartValue" SG_ 692 FRZCU_3_ClntTHvBattOut 254;
BA_ "GenSigASIL"  SG_ 692 FRZCU_3_ClntTHvBattOut 5;
BA_ "GenSigStartValue" SG_ 692 FRZCU_3_DCPortTemp_P 254;
BA_ "GenSigASIL"  SG_ 692 FRZCU_3_DCPortTemp_P 5;
BA_ "GenSigStartValue" SG_ 692 FRZCU_3_DCPortTemp_N 254;
BA_ "GenSigASIL"  SG_ 692 FRZCU_3_DCPortTemp_N 5;
BA_ "GenSigASIL"  SG_ 692 FRZCU_3_CLMHVILFault 5;
BA_ "GenSigASIL"  SG_ 692 FRZCU_3_HvilChkFltSt 5;
BA_ "GenMsgILSupport" BO_ 469 1;
BA_ "GenMsgCycleTime" BO_ 469 10;
BA_ "GenSigASIL"  SG_ 469 FMCU_1_CRC1 5;
BA_ "GenSigASIL"  SG_ 469 FMCU_1_RollgCntr1 5;
BA_ "GenSigASIL"  SG_ 469 FMCU_1_Resd1 5;
BA_ "GenSigASIL"  SG_ 469 FMCU_TorqMax 1;
BA_ "GenSigStartValue" SG_ 469 FMCU_TorqMin 1400;
BA_ "GenSigASIL"  SG_ 469 FMCU_TorqMin 1;
BA_ "GenSigStartValue" SG_ 469 FMCU_TorqAct 2804;
BA_ "GenSigASIL"  SG_ 469 FMCU_TorqAct 3;
BA_ "GenSigASIL"  SG_ 469 FMCU_ModeSt 3;
BA_ "GenSigASIL"  SG_ 469 FMCU_1_CRC2 5;
BA_ "GenSigASIL"  SG_ 469 FMCU_1_RollgCntr2 5;
BA_ "GenSigASIL"  SG_ 469 FMCU_1_Resd2 5;
BA_ "GenSigASIL"  SG_ 469 FMCU_SpdAct 3;
BA_ "GenSigStartValue" SG_ 469 FMCU_TrqActDampingReq 1400;
BA_ "GenSigASIL"  SG_ 469 FMCU_TrqActDampingReq 1;
BA_ "GenSigASIL"  SG_ 469 FMCU_FMCUDeratSts 5;
BA_ "GenSigStartValue" SG_ 469 FMCU_UdcAct 1022;
BA_ "GenSigASIL"  SG_ 469 FMCU_UdcAct 3;
BA_ "GenSigASIL"  SG_ 469 FMCU_1_CRC3 5;
BA_ "GenSigASIL"  SG_ 469 FMCU_1_RollgCntr3 5;
BA_ "GenSigASIL"  SG_ 469 FMCU_1_Resd3 5;
BA_ "GenSigASIL"  SG_ 469 FMCU_IdcAct 3;
BA_ "GenSigASIL"  SG_ 469 FMCU_ErrLvl 5;
BA_ "GenSigStartValue" SG_ 469 FMCU_InterlockStatus 1;
BA_ "GenSigASIL"  SG_ 469 FMCU_InterlockStatus 5;
BA_ "GenSigASIL"  SG_ 469 FMCU_DampActive 1;
BA_ "GenSigASIL"  SG_ 469 FMCU_E_ClutchErrLvl 3;
BA_ "GenSigASIL"  SG_ 469 FMCU_E_ClutchActMod 3;
BA_ "GenSigASIL"  SG_ 469 FMCU_E_ClutchStus 3;
BA_ "GenSigASIL"  SG_ 469 FMCU_E_ClutchCurr 3;
BA_ "GenSigASIL"  SG_ 469 FMCU_E_ClutchEngMilLampReq 3;
BA_ "GenSigStartValue" SG_ 469 FMCU_NegTrqAvailMin_2s 1400;
BA_ "GenSigASIL"  SG_ 469 FMCU_NegTrqAvailMin_2s 5;
BA_ "GenSigASIL"  SG_ 469 FMCU_PosTrqAvailMax_2s 5;
BA_ "GenMsgILSupport" BO_ 1115 1;
BA_ "GenMsgCycleTime" BO_ 1115 100;
BA_ "GenSigASIL"  SG_ 1115 FMCU_2_CRC 5;
BA_ "GenSigASIL"  SG_ 1115 FMCU_2_RollgCntr 5;
BA_ "GenSigASIL"  SG_ 1115 FMCU_2_Resd 5;
BA_ "GenSigStartValue" SG_ 1115 FMCU_InvTemp 250;
BA_ "GenSigASIL"  SG_ 1115 FMCU_InvTemp 1;
BA_ "GenSigStartValue" SG_ 1115 FMCU_RotorTemperature 40;
BA_ "GenSigASIL"  SG_ 1115 FMCU_RotorTemperature 5;
BA_ "GenSigStartValue" SG_ 1115 FMCU_StatTemp 40;
BA_ "GenSigASIL"  SG_ 1115 FMCU_StatTemp 1;
BA_ "GenSigASIL"  SG_ 1115 FMCU_Ratio 3;
BA_ "GenSigStartValue" SG_ 1115 FMCU_InvSampTemp 250;
BA_ "GenSigASIL"  SG_ 1115 FMCU_InvSampTemp 1;
BA_ "GenMsgILSupport" BO_ 1118 1;
BA_ "GenMsgCycleTime" BO_ 1118 100;
BA_ "GenSigASIL"  SG_ 1118 FMCU_Fault1 5;
BA_ "GenSigASIL"  SG_ 1118 FMCU_Fault2 5;
BA_ "GenSigASIL"  SG_ 1118 FMCU_Fault3 5;
BA_ "GenSigASIL"  SG_ 1118 FMCU_Fault4 5;
BA_ "GenMsgILSupport" BO_ 1088 1;
BA_ "GenMsgCycleTime" BO_ 1088 100;
BA_ "GenSigASIL"  SG_ 1088 FMCU_WPhaseCurrent 5;
BA_ "GenSigASIL"  SG_ 1088 FMCU_VPhaseCurrent 5;
BA_ "GenSigASIL"  SG_ 1088 FMCU_UPhaseCurrent 5;
BA_ "GenSigASIL"  SG_ 1088 FMCU_4_SWInfo 5;
BA_ "GenSigASIL"  SG_ 1088 FMCU_4_CRC 5;
BA_ "GenSigASIL"  SG_ 1088 FMCU_4_RollgCntr 5;
BA_ "GenSigASIL"  SG_ 1088 FMCU_4_Resd 5;
BA_ "GenSigASIL"  SG_ 1088 FMCU_TempW 1;
BA_ "GenSigASIL"  SG_ 1088 FMCU_TempV 1;
BA_ "GenSigASIL"  SG_ 1088 FMCU_TempU 1;
BA_ "GenSigASIL"  SG_ 1088 FMCU_CoolantTemp 1;
BA_ "GenSigASIL"  SG_ 1088 FMCU_Delta_TJ_Coolant 1;
BA_ "GenSigASIL"  SG_ 1088 FMCU_IGBTmode 5;
VAL_ 515 EVCC_GunConnectSt 3 "Reserved" 2 "The connection is abnormal." 1 "Connect" 0 "Disconnect" ;
VAL_ 515 EVCC_ElectronicLockSts 4 "Elock error" 3 "Unlock error" 2 "Lock error" 1 "Lock" 0 "Unlock" ;
VAL_ 515 EVCC_PPCode 15 "Reserved" 14 "Reserved" 13 "Reserved" 12 "Reserved" 11 "Reserved" 10 "Abnormal value" 9 "V2L gun connected��AC��" 8 "S3 close��150 ����" 7 "S3 open��480 ����" 6 "Detection circuit fault" 5 "Disconnect" 4 "100��" 3 "220��" 2 "680��" 1 "1500��" 0 "Unknown" ;
VAL_ 515 EVCC_CC_RCR4_Sts 8191 "Invalid" 8190 "Valid" 8189 "Valid" 8188 "Valid" 8187 "Valid" 8186 "Valid" 8185 "Valid" 8184 "Valid" 8183 "Valid" 8182 "Valid" 8181 "Valid" 8180 "Valid" 8179 "Valid" 8178 "Valid" 8177 "Valid" 8176 "Valid" 8175 "Valid" 8174 "Valid" 8173 "Valid" 8172 "Valid" 8171 "Valid" 8170 "Valid" 8169 "Valid" 8168 "Valid" 8167 "Valid" 8166 "Valid" 8165 "Valid" 8164 "Valid" 8163 "Valid" 8162 "Valid" 8161 "Valid" 8160 "Valid" 8159 "Valid" 8158 "Valid" 8157 "Valid" 8156 "Valid" 8155 "Valid" 8154 "Valid" 8153 "Valid" 8152 "Valid" 8151 "Valid" 8150 "Valid" 8149 "Valid" 8148 "Valid" 8147 "Valid" 8146 "Valid" 8145 "Valid" 8144 "Valid" 8143 "Valid" 8142 "Valid" 8141 "Valid" 8140 "Valid" 8139 "Valid" 8138 "Valid" 8137 "Valid" 8136 "Valid" 8135 "Valid" 8134 "Valid" 8133 "Valid" 8132 "Valid" 8131 "Valid" 8130 "Valid" 8129 "Valid" 8128 "Valid" 8127 "Valid" 8126 "Valid" 8125 "Valid" 8124 "Valid" 8123 "Valid" 8122 "Valid" 8121 "Valid" 8120 "Valid" 8119 "Valid" 8118 "Valid" 8117 "Valid" 8116 "Valid" 8115 "Valid" 8114 "Valid" 8113 "Valid" 8112 "Valid" 8111 "Valid" 8110 "Valid" 8109 "Valid" 8108 "Valid" 8107 "Valid" 8106 "Valid" 8105 "Valid" 8104 "Valid" 8103 "Valid" 8102 "Valid" 8101 "Valid" 8100 "Valid" 8099 "Valid" 8098 "Valid" 8097 "Valid" 8096 "Valid" 8095 "Valid" 8094 "Valid" 8093 "Valid" 8092 "Valid" 8091 "Valid" 8090 "Valid" 8089 "Valid" 8088 "Valid" 8087 "Valid" 8086 "Valid" 8085 "Valid" 8084 "Valid" 8083 "Valid" 8082 "Valid" 8081 "Valid" 8080 "Valid" 8079 "Valid" 8078 "Valid" 8077 "Valid" 8076 "Valid" 8075 "Valid" 8074 "Valid" 8073 "Valid" 8072 "Valid" 8071 "Valid" 8070 "Valid" 8069 "Valid" 8068 "Valid" 8067 "Valid" 8066 "Valid" 8065 "Valid" 8064 "Valid" 8063 "Valid" 8062 "Valid" 8061 "Valid" 8060 "Valid" 8059 "Valid" 8058 "Valid" 8057 "Valid" 8056 "Valid" 8055 "Valid" 8054 "Valid" 8053 "Valid" 8052 "Valid" 8051 "Valid" 8050 "Valid" 8049 "Valid" 8048 "Valid" 8047 "Valid" 8046 "Valid" 8045 "Valid" 8044 "Valid" 8043 "Valid" 8042 "Valid" 8041 "Valid" 8040 "Valid" 8039 "Valid" 8038 "Valid" 8037 "Valid" 8036 "Valid" 8035 "Valid" 8034 "Valid" 8033 "Valid" 8032 "Valid" 8031 "Valid" 8030 "Valid" 8029 "Valid" 8028 "Valid" 8027 "Valid" 8026 "Valid" 8025 "Valid" 8024 "Valid" 8023 "Valid" 8022 "Valid" 8021 "Valid" 8020 "Valid" 8019 "Valid" 8018 "Valid" 8017 "Valid" 8016 "Valid" 8015 "Valid" 8014 "Valid" 8013 "Valid" 8012 "Valid" 8011 "Valid" 8010 "Valid" 8009 "Valid" 8008 "Valid" 8007 "Valid" 8006 "Valid" 8005 "Valid" 8004 "Valid" 8003 "Valid" 8002 "Valid" 8001 "Valid" 8000 "Valid" 7999 "Valid" 7998 "Valid" 7997 "Valid" 7996 "Valid" 7995 "Valid" 7994 "Valid" 7993 "Valid" 7992 "Valid" 7991 "Valid" 7990 "Valid" 7989 "Valid" 7988 "Valid" 7987 "Valid" 7986 "Valid" 7985 "Valid" 7984 "Valid" 7983 "Valid" 7982 "Valid" 7981 "Valid" 7980 "Valid" 7979 "Valid" 7978 "Valid" 7977 "Valid" 7976 "Valid" 7975 "Valid" 7974 "Valid" 7973 "Valid" 7972 "Valid" 7971 "Valid" 7970 "Valid" 7969 "Valid" 7968 "Valid" 7967 "Valid" 7966 "Valid" 7965 "Valid" 7964 "Valid" 7963 "Valid" 7962 "Valid" 7961 "Valid" 7960 "Valid" 7959 "Valid" 7958 "Valid" 7957 "Valid" 7956 "Valid" 7955 "Valid" 7954 "Valid" 7953 "Valid" 7952 "Valid" 7951 "Valid" 7950 "Valid" 7949 "Valid" 7948 "Valid" 7947 "Valid" 7946 "Valid" 7945 "Valid" 7944 "Valid" 7943 "Valid" 7942 "Valid" 7941 "Valid" 7940 "Valid" 7939 "Valid" 7938 "Valid" 7937 "Valid" 7936 "Valid" 7935 "Valid" 7934 "Valid" 7933 "Valid" 7932 "Valid" 7931 "Valid" 7930 "Valid" 7929 "Valid" 7928 "Valid" 7927 "Valid" 7926 "Valid" 7925 "Valid" 7924 "Valid" 7923 "Valid" 7922 "Valid" 7921 "Valid" 7920 "Valid" 7919 "Valid" 7918 "Valid" 7917 "Valid" 7916 "Valid" 7915 "Valid" 7914 "Valid" 7913 "Valid" 7912 "Valid" 7911 "Valid" 7910 "Valid" 7909 "Valid" 7908 "Valid" 7907 "Valid" 7906 "Valid" 7905 "Valid" 7904 "Valid" 7903 "Valid" 7902 "Valid" 7901 "Valid" 7900 "Valid" 7899 "Valid" 7898 "Valid" 7897 "Valid" 7896 "Valid" 7895 "Valid" 7894 "Valid" 7893 "Valid" 7892 "Valid" 7891 "Valid" 7890 "Valid" 7889 "Valid" 7888 "Valid" 7887 "Valid" 7886 "Valid" 7885 "Valid" 7884 "Valid" 7883 "Valid" 7882 "Valid" 7881 "Valid" 7880 "Valid" 7879 "Valid" 7878 "Valid" 7877 "Valid" 7876 "Valid" 7875 "Valid" 7874 "Valid" 7873 "Valid" 7872 "Valid" 7871 "Valid" 7870 "Valid" 7869 "Valid" 7868 "Valid" 7867 "Valid" 7866 "Valid" 7865 "Valid" 7864 "Valid" 7863 "Valid" 7862 "Valid" 7861 "Valid" 7860 "Valid" 7859 "Valid" 7858 "Valid" 7857 "Valid" 7856 "Valid" 7855 "Valid" 7854 "Valid" 7853 "Valid" 7852 "Valid" 7851 "Valid" 7850 "Valid" 7849 "Valid" 7848 "Valid" 7847 "Valid" 7846 "Valid" 7845 "Valid" 7844 "Valid" 7843 "Valid" 7842 "Valid" 7841 "Valid" 7840 "Valid" 7839 "Valid" 7838 "Valid" 7837 "Valid" 7836 "Valid" 7835 "Valid" 7834 "Valid" 7833 "Valid" 7832 "Valid" 7831 "Valid" 7830 "Valid" 7829 "Valid" 7828 "Valid" 7827 "Valid" 7826 "Valid" 7825 "Valid" 7824 "Valid" 7823 "Valid" 7822 "Valid" 7821 "Valid" 7820 "Valid" 7819 "Valid" 7818 "Valid" 7817 "Valid" 7816 "Valid" 7815 "Valid" 7814 "Valid" 7813 "Valid" 7812 "Valid" 7811 "Valid" 7810 "Valid" 7809 "Valid" 7808 "Valid" 7807 "Valid" 7806 "Valid" 7805 "Valid" 7804 "Valid" 7803 "Valid" 7802 "Valid" 7801 "Valid" 7800 "Valid" 7799 "Valid" 7798 "Valid" 7797 "Valid" 7796 "Valid" 7795 "Valid" 7794 "Valid" 7793 "Valid" 7792 "Valid" 7791 "Valid" 7790 "Valid" 7789 "Valid" 7788 "Valid" 7787 "Valid" 7786 "Valid" 7785 "Valid" 7784 "Valid" 7783 "Valid" 7782 "Valid" 7781 "Valid" 7780 "Valid" 7779 "Valid" 7778 "Valid" 7777 "Valid" 7776 "Valid" 7775 "Valid" 7774 "Valid" 7773 "Valid" 7772 "Valid" 7771 "Valid" 7770 "Valid" 7769 "Valid" 7768 "Valid" 7767 "Valid" 7766 "Valid" 7765 "Valid" 7764 "Valid" 7763 "Valid" 7762 "Valid" 7761 "Valid" 7760 "Valid" 7759 "Valid" 7758 "Valid" 7757 "Valid" 7756 "Valid" 7755 "Valid" 7754 "Valid" 7753 "Valid" 7752 "Valid" 7751 "Valid" 7750 "Valid" 7749 "Valid" 7748 "Valid" 7747 "Valid" 7746 "Valid" 7745 "Valid" 7744 "Valid" 7743 "Valid" 7742 "Valid" 7741 "Valid" 7740 "Valid" 7739 "Valid" 7738 "Valid" 7737 "Valid" 7736 "Valid" 7735 "Valid" 7734 "Valid" 7733 "Valid" 7732 "Valid" 7731 "Valid" 7730 "Valid" 7729 "Valid" 7728 "Valid" 7727 "Valid" 7726 "Valid" 7725 "Valid" 7724 "Valid" 7723 "Valid" 7722 "Valid" 7721 "Valid" 7720 "Valid" 7719 "Valid" 7718 "Valid" 7717 "Valid" 7716 "Valid" 7715 "Valid" 7714 "Valid" 7713 "Valid" 7712 "Valid" 7711 "Valid" 7710 "Valid" 7709 "Valid" 7708 "Valid" 7707 "Valid" 7706 "Valid" 7705 "Valid" 7704 "Valid" 7703 "Valid" 7702 "Valid" 7701 "Valid" 7700 "Valid" 7699 "Valid" 7698 "Valid" 7697 "Valid" 7696 "Valid" 7695 "Valid" 7694 "Valid" 7693 "Valid" 7692 "Valid" 7691 "Valid" 7690 "Valid" 7689 "Valid" 7688 "Valid" 7687 "Valid" 7686 "Valid" 7685 "Valid" 7684 "Valid" 7683 "Valid" 7682 "Valid" 7681 "Valid" 7680 "Valid" 7679 "Valid" 7678 "Valid" 7677 "Valid" 7676 "Valid" 7675 "Valid" 7674 "Valid" 7673 "Valid" 7672 "Valid" 7671 "Valid" 7670 "Valid" 7669 "Valid" 7668 "Valid" 7667 "Valid" 7666 "Valid" 7665 "Valid" 7664 "Valid" 7663 "Valid" 7662 "Valid" 7661 "Valid" 7660 "Valid" 7659 "Valid" 7658 "Valid" 7657 "Valid" 7656 "Valid" 7655 "Valid" 7654 "Valid" 7653 "Valid" 7652 "Valid" 7651 "Valid" 7650 "Valid" 7649 "Valid" 7648 "Valid" 7647 "Valid" 7646 "Valid" 7645 "Valid" 7644 "Valid" 7643 "Valid" 7642 "Valid" 7641 "Valid" 7640 "Valid" 7639 "Valid" 7638 "Valid" 7637 "Valid" 7636 "Valid" 7635 "Valid" 7634 "Valid" 7633 "Valid" 7632 "Valid" 7631 "Valid" 7630 "Valid" 7629 "Valid" 7628 "Valid" 7627 "Valid" 7626 "Valid" 7625 "Valid" 7624 "Valid" 7623 "Valid" 7622 "Valid" 7621 "Valid" 7620 "Valid" 7619 "Valid" 7618 "Valid" 7617 "Valid" 7616 "Valid" 7615 "Valid" 7614 "Valid" 7613 "Valid" 7612 "Valid" 7611 "Valid" 7610 "Valid" 7609 "Valid" 7608 "Valid" 7607 "Valid" 7606 "Valid" 7605 "Valid" 7604 "Valid" 7603 "Valid" 7602 "Valid" 7601 "Valid" 7600 "Valid" 7599 "Valid" 7598 "Valid" 7597 "Valid" 7596 "Valid" 7595 "Valid" 7594 "Valid" 7593 "Valid" 7592 "Valid" 7591 "Valid" 7590 "Valid" 7589 "Valid" 7588 "Valid" 7587 "Valid" 7586 "Valid" 7585 "Valid" 7584 "Valid" 7583 "Valid" 7582 "Valid" 7581 "Valid" 7580 "Valid" 7579 "Valid" 7578 "Valid" 7577 "Valid" 7576 "Valid" 7575 "Valid" 7574 "Valid" 7573 "Valid" 7572 "Valid" 7571 "Valid" 7570 "Valid" 7569 "Valid" 7568 "Valid" 7567 "Valid" 7566 "Valid" 7565 "Valid" 7564 "Valid" 7563 "Valid" 7562 "Valid" 7561 "Valid" 7560 "Valid" 7559 "Valid" 7558 "Valid" 7557 "Valid" 7556 "Valid" 7555 "Valid" 7554 "Valid" 7553 "Valid" 7552 "Valid" 7551 "Valid" 7550 "Valid" 7549 "Valid" 7548 "Valid" 7547 "Valid" 7546 "Valid" 7545 "Valid" 7544 "Valid" 7543 "Valid" 7542 "Valid" 7541 "Valid" 7540 "Valid" 7539 "Valid" 7538 "Valid" 7537 "Valid" 7536 "Valid" 7535 "Valid" 7534 "Valid" 7533 "Valid" 7532 "Valid" 7531 "Valid" 7530 "Valid" 7529 "Valid" 7528 "Valid" 7527 "Valid" 7526 "Valid" 7525 "Valid" 7524 "Valid" 7523 "Valid" 7522 "Valid" 7521 "Valid" 7520 "Valid" 7519 "Valid" 7518 "Valid" 7517 "Valid" 7516 "Valid" 7515 "Valid" 7514 "Valid" 7513 "Valid" 7512 "Valid" 7511 "Valid" 7510 "Valid" 7509 "Valid" 7508 "Valid" 7507 "Valid" 7506 "Valid" 7505 "Valid" 7504 "Valid" 7503 "Valid" 7502 "Valid" 7501 "Valid" 7500 "Valid" 7499 "Valid" 7498 "Valid" 7497 "Valid" 7496 "Valid" 7495 "Valid" 7494 "Valid" 7493 "Valid" 7492 "Valid" 7491 "Valid" 7490 "Valid" 7489 "Valid" 7488 "Valid" 7487 "Valid" 7486 "Valid" 7485 "Valid" 7484 "Valid" 7483 "Valid" 7482 "Valid" 7481 "Valid" 7480 "Valid" 7479 "Valid" 7478 "Valid" 7477 "Valid" 7476 "Valid" 7475 "Valid" 7474 "Valid" 7473 "Valid" 7472 "Valid" 7471 "Valid" 7470 "Valid" 7469 "Valid" 7468 "Valid" 7467 "Valid" 7466 "Valid" 7465 "Valid" 7464 "Valid" 7463 "Valid" 7462 "Valid" 7461 "Valid" 7460 "Valid" 7459 "Valid" 7458 "Valid" 7457 "Valid" 7456 "Valid" 7455 "Valid" 7454 "Valid" 7453 "Valid" 7452 "Valid" 7451 "Valid" 7450 "Valid" 7449 "Valid" 7448 "Valid" 7447 "Valid" 7446 "Valid" 7445 "Valid" 7444 "Valid" 7443 "Valid" 7442 "Valid" 7441 "Valid" 7440 "Valid" 7439 "Valid" 7438 "Valid" 7437 "Valid" 7436 "Valid" 7435 "Valid" 7434 "Valid" 7433 "Valid" 7432 "Valid" 7431 "Valid" 7430 "Valid" 7429 "Valid" 7428 "Valid" 7427 "Valid" 7426 "Valid" 7425 "Valid" 7424 "Valid" 7423 "Valid" 7422 "Valid" 7421 "Valid" 7420 "Valid" 7419 "Valid" 7418 "Valid" 7417 "Valid" 7416 "Valid" 7415 "Valid" 7414 "Valid" 7413 "Valid" 7412 "Valid" 7411 "Valid" 7410 "Valid" 7409 "Valid" 7408 "Valid" 7407 "Valid" 7406 "Valid" 7405 "Valid" 7404 "Valid" 7403 "Valid" 7402 "Valid" 7401 "Valid" 7400 "Valid" 7399 "Valid" 7398 "Valid" 7397 "Valid" 7396 "Valid" 7395 "Valid" 7394 "Valid" 7393 "Valid" 7392 "Valid" 7391 "Valid" 7390 "Valid" 7389 "Valid" 7388 "Valid" 7387 "Valid" 7386 "Valid" 7385 "Valid" 7384 "Valid" 7383 "Valid" 7382 "Valid" 7381 "Valid" 7380 "Valid" 7379 "Valid" 7378 "Valid" 7377 "Valid" 7376 "Valid" 7375 "Valid" 7374 "Valid" 7373 "Valid" 7372 "Valid" 7371 "Valid" 7370 "Valid" 7369 "Valid" 7368 "Valid" 7367 "Valid" 7366 "Valid" 7365 "Valid" 7364 "Valid" 7363 "Valid" 7362 "Valid" 7361 "Valid" 7360 "Valid" 7359 "Valid" 7358 "Valid" 7357 "Valid" 7356 "Valid" 7355 "Valid" 7354 "Valid" 7353 "Valid" 7352 "Valid" 7351 "Valid" 7350 "Valid" 7349 "Valid" 7348 "Valid" 7347 "Valid" 7346 "Valid" 7345 "Valid" 7344 "Valid" 7343 "Valid" 7342 "Valid" 7341 "Valid" 7340 "Valid" 7339 "Valid" 7338 "Valid" 7337 "Valid" 7336 "Valid" 7335 "Valid" 7334 "Valid" 7333 "Valid" 7332 "Valid" 7331 "Valid" 7330 "Valid" 7329 "Valid" 7328 "Valid" 7327 "Valid" 7326 "Valid" 7325 "Valid" 7324 "Valid" 7323 "Valid" 7322 "Valid" 7321 "Valid" 7320 "Valid" 7319 "Valid" 7318 "Valid" 7317 "Valid" 7316 "Valid" 7315 "Valid" 7314 "Valid" 7313 "Valid" 7312 "Valid" 7311 "Valid" 7310 "Valid" 7309 "Valid" 7308 "Valid" 7307 "Valid" 7306 "Valid" 7305 "Valid" 7304 "Valid" 7303 "Valid" 7302 "Valid" 7301 "Valid" 7300 "Valid" 7299 "Valid" 7298 "Valid" 7297 "Valid" 7296 "Valid" 7295 "Valid" 7294 "Valid" 7293 "Valid" 7292 "Valid" 7291 "Valid" 7290 "Valid" 7289 "Valid" 7288 "Valid" 7287 "Valid" 7286 "Valid" 7285 "Valid" 7284 "Valid" 7283 "Valid" 7282 "Valid" 7281 "Valid" 7280 "Valid" 7279 "Valid" 7278 "Valid" 7277 "Valid" 7276 "Valid" 7275 "Valid" 7274 "Valid" 7273 "Valid" 7272 "Valid" 7271 "Valid" 7270 "Valid" 7269 "Valid" 7268 "Valid" 7267 "Valid" 7266 "Valid" 7265 "Valid" 7264 "Valid" 7263 "Valid" 7262 "Valid" 7261 "Valid" 7260 "Valid" 7259 "Valid" 7258 "Valid" 7257 "Valid" 7256 "Valid" 7255 "Valid" 7254 "Valid" 7253 "Valid" 7252 "Valid" 7251 "Valid" 7250 "Valid" 7249 "Valid" 7248 "Valid" 7247 "Valid" 7246 "Valid" 7245 "Valid" 7244 "Valid" 7243 "Valid" 7242 "Valid" 7241 "Valid" 7240 "Valid" 7239 "Valid" 7238 "Valid" 7237 "Valid" 7236 "Valid" 7235 "Valid" 7234 "Valid" 7233 "Valid" 7232 "Valid" 7231 "Valid" 7230 "Valid" 7229 "Valid" 7228 "Valid" 7227 "Valid" 7226 "Valid" 7225 "Valid" 7224 "Valid" 7223 "Valid" 7222 "Valid" 7221 "Valid" 7220 "Valid" 7219 "Valid" 7218 "Valid" 7217 "Valid" 7216 "Valid" 7215 "Valid" 7214 "Valid" 7213 "Valid" 7212 "Valid" 7211 "Valid" 7210 "Valid" 7209 "Valid" 7208 "Valid" 7207 "Valid" 7206 "Valid" 7205 "Valid" 7204 "Valid" 7203 "Valid" 7202 "Valid" 7201 "Valid" 7200 "Valid" 7199 "Valid" 7198 "Valid" 7197 "Valid" 7196 "Valid" 7195 "Valid" 7194 "Valid" 7193 "Valid" 7192 "Valid" 7191 "Valid" 7190 "Valid" 7189 "Valid" 7188 "Valid" 7187 "Valid" 7186 "Valid" 7185 "Valid" 7184 "Valid" 7183 "Valid" 7182 "Valid" 7181 "Valid" 7180 "Valid" 7179 "Valid" 7178 "Valid" 7177 "Valid" 7176 "Valid" 7175 "Valid" 7174 "Valid" 7173 "Valid" 7172 "Valid" 7171 "Valid" 7170 "Valid" 7169 "Valid" 7168 "Valid" 7167 "Valid" 7166 "Valid" 7165 "Valid" 7164 "Valid" 7163 "Valid" 7162 "Valid" 7161 "Valid" 7160 "Valid" 7159 "Valid" 7158 "Valid" 7157 "Valid" 7156 "Valid" 7155 "Valid" 7154 "Valid" 7153 "Valid" 7152 "Valid" 7151 "Valid" 7150 "Valid" 7149 "Valid" 7148 "Valid" 7147 "Valid" 7146 "Valid" 7145 "Valid" 7144 "Valid" 7143 "Valid" 7142 "Valid" 7141 "Valid" 7140 "Valid" 7139 "Valid" 7138 "Valid" 7137 "Valid" 7136 "Valid" 7135 "Valid" 7134 "Valid" 7133 "Valid" 7132 "Valid" 7131 "Valid" 7130 "Valid" 7129 "Valid" 7128 "Valid" 7127 "Valid" 7126 "Valid" 7125 "Valid" 7124 "Valid" 7123 "Valid" 7122 "Valid" 7121 "Valid" 7120 "Valid" 7119 "Valid" 7118 "Valid" 7117 "Valid" 7116 "Valid" 7115 "Valid" 7114 "Valid" 7113 "Valid" 7112 "Valid" 7111 "Valid" 7110 "Valid" 7109 "Valid" 7108 "Valid" 7107 "Valid" 7106 "Valid" 7105 "Valid" 7104 "Valid" 7103 "Valid" 7102 "Valid" 7101 "Valid" 7100 "Valid" 7099 "Valid" 7098 "Valid" 7097 "Valid" 7096 "Valid" 7095 "Valid" 7094 "Valid" 7093 "Valid" 7092 "Valid" 7091 "Valid" 7090 "Valid" 7089 "Valid" 7088 "Valid" 7087 "Valid" 7086 "Valid" 7085 "Valid" 7084 "Valid" 7083 "Valid" 7082 "Valid" 7081 "Valid" 7080 "Valid" 7079 "Valid" 7078 "Valid" 7077 "Valid" 7076 "Valid" 7075 "Valid" 7074 "Valid" 7073 "Valid" 7072 "Valid" 7071 "Valid" 7070 "Valid" 7069 "Valid" 7068 "Valid" 7067 "Valid" 7066 "Valid" 7065 "Valid" 7064 "Valid" 7063 "Valid" 7062 "Valid" 7061 "Valid" 7060 "Valid" 7059 "Valid" 7058 "Valid" 7057 "Valid" 7056 "Valid" 7055 "Valid" 7054 "Valid" 7053 "Valid" 7052 "Valid" 7051 "Valid" 7050 "Valid" 7049 "Valid" 7048 "Valid" 7047 "Valid" 7046 "Valid" 7045 "Valid" 7044 "Valid" 7043 "Valid" 7042 "Valid" 7041 "Valid" 7040 "Valid" 7039 "Valid" 7038 "Valid" 7037 "Valid" 7036 "Valid" 7035 "Valid" 7034 "Valid" 7033 "Valid" 7032 "Valid" 7031 "Valid" 7030 "Valid" 7029 "Valid" 7028 "Valid" 7027 "Valid" 7026 "Valid" 7025 "Valid" 7024 "Valid" 7023 "Valid" 7022 "Valid" 7021 "Valid" 7020 "Valid" 7019 "Valid" 7018 "Valid" 7017 "Valid" 7016 "Valid" 7015 "Valid" 7014 "Valid" 7013 "Valid" 7012 "Valid" 7011 "Valid" 7010 "Valid" 7009 "Valid" 7008 "Valid" 7007 "Valid" 7006 "Valid" 7005 "Valid" 7004 "Valid" 7003 "Valid" 7002 "Valid" 7001 "Valid" 7000 "Valid" 6999 "Valid" 6998 "Valid" 6997 "Valid" 6996 "Valid" 6995 "Valid" 6994 "Valid" 6993 "Valid" 6992 "Valid" 6991 "Valid" 6990 "Valid" 6989 "Valid" 6988 "Valid" 6987 "Valid" 6986 "Valid" 6985 "Valid" 6984 "Valid" 6983 "Valid" 6982 "Valid" 6981 "Valid" 6980 "Valid" 6979 "Valid" 6978 "Valid" 6977 "Valid" 6976 "Valid" 6975 "Valid" 6974 "Valid" 6973 "Valid" 6972 "Valid" 6971 "Valid" 6970 "Valid" 6969 "Valid" 6968 "Valid" 6967 "Valid" 6966 "Valid" 6965 "Valid" 6964 "Valid" 6963 "Valid" 6962 "Valid" 6961 "Valid" 6960 "Valid" 6959 "Valid" 6958 "Valid" 6957 "Valid" 6956 "Valid" 6955 "Valid" 6954 "Valid" 6953 "Valid" 6952 "Valid" 6951 "Valid" 6950 "Valid" 6949 "Valid" 6948 "Valid" 6947 "Valid" 6946 "Valid" 6945 "Valid" 6944 "Valid" 6943 "Valid" 6942 "Valid" 6941 "Valid" 6940 "Valid" 6939 "Valid" 6938 "Valid" 6937 "Valid" 6936 "Valid" 6935 "Valid" 6934 "Valid" 6933 "Valid" 6932 "Valid" 6931 "Valid" 6930 "Valid" 6929 "Valid" 6928 "Valid" 6927 "Valid" 6926 "Valid" 6925 "Valid" 6924 "Valid" 6923 "Valid" 6922 "Valid" 6921 "Valid" 6920 "Valid" 6919 "Valid" 6918 "Valid" 6917 "Valid" 6916 "Valid" 6915 "Valid" 6914 "Valid" 6913 "Valid" 6912 "Valid" 6911 "Valid" 6910 "Valid" 6909 "Valid" 6908 "Valid" 6907 "Valid" 6906 "Valid" 6905 "Valid" 6904 "Valid" 6903 "Valid" 6902 "Valid" 6901 "Valid" 6900 "Valid" 6899 "Valid" 6898 "Valid" 6897 "Valid" 6896 "Valid" 6895 "Valid" 6894 "Valid" 6893 "Valid" 6892 "Valid" 6891 "Valid" 6890 "Valid" 6889 "Valid" 6888 "Valid" 6887 "Valid" 6886 "Valid" 6885 "Valid" 6884 "Valid" 6883 "Valid" 6882 "Valid" 6881 "Valid" 6880 "Valid" 6879 "Valid" 6878 "Valid" 6877 "Valid" 6876 "Valid" 6875 "Valid" 6874 "Valid" 6873 "Valid" 6872 "Valid" 6871 "Valid" 6870 "Valid" 6869 "Valid" 6868 "Valid" 6867 "Valid" 6866 "Valid" 6865 "Valid" 6864 "Valid" 6863 "Valid" 6862 "Valid" 6861 "Valid" 6860 "Valid" 6859 "Valid" 6858 "Valid" 6857 "Valid" 6856 "Valid" 6855 "Valid" 6854 "Valid" 6853 "Valid" 6852 "Valid" 6851 "Valid" 6850 "Valid" 6849 "Valid" 6848 "Valid" 6847 "Valid" 6846 "Valid" 6845 "Valid" 6844 "Valid" 6843 "Valid" 6842 "Valid" 6841 "Valid" 6840 "Valid" 6839 "Valid" 6838 "Valid" 6837 "Valid" 6836 "Valid" 6835 "Valid" 6834 "Valid" 6833 "Valid" 6832 "Valid" 6831 "Valid" 6830 "Valid" 6829 "Valid" 6828 "Valid" 6827 "Valid" 6826 "Valid" 6825 "Valid" 6824 "Valid" 6823 "Valid" 6822 "Valid" 6821 "Valid" 6820 "Valid" 6819 "Valid" 6818 "Valid" 6817 "Valid" 6816 "Valid" 6815 "Valid" 6814 "Valid" 6813 "Valid" 6812 "Valid" 6811 "Valid" 6810 "Valid" 6809 "Valid" 6808 "Valid" 6807 "Valid" 6806 "Valid" 6805 "Valid" 6804 "Valid" 6803 "Valid" 6802 "Valid" 6801 "Valid" 6800 "Valid" 6799 "Valid" 6798 "Valid" 6797 "Valid" 6796 "Valid" 6795 "Valid" 6794 "Valid" 6793 "Valid" 6792 "Valid" 6791 "Valid" 6790 "Valid" 6789 "Valid" 6788 "Valid" 6787 "Valid" 6786 "Valid" 6785 "Valid" 6784 "Valid" 6783 "Valid" 6782 "Valid" 6781 "Valid" 6780 "Valid" 6779 "Valid" 6778 "Valid" 6777 "Valid" 6776 "Valid" 6775 "Valid" 6774 "Valid" 6773 "Valid" 6772 "Valid" 6771 "Valid" 6770 "Valid" 6769 "Valid" 6768 "Valid" 6767 "Valid" 6766 "Valid" 6765 "Valid" 6764 "Valid" 6763 "Valid" 6762 "Valid" 6761 "Valid" 6760 "Valid" 6759 "Valid" 6758 "Valid" 6757 "Valid" 6756 "Valid" 6755 "Valid" 6754 "Valid" 6753 "Valid" 6752 "Valid" 6751 "Valid" 6750 "Valid" 6749 "Valid" 6748 "Valid" 6747 "Valid" 6746 "Valid" 6745 "Valid" 6744 "Valid" 6743 "Valid" 6742 "Valid" 6741 "Valid" 6740 "Valid" 6739 "Valid" 6738 "Valid" 6737 "Valid" 6736 "Valid" 6735 "Valid" 6734 "Valid" 6733 "Valid" 6732 "Valid" 6731 "Valid" 6730 "Valid" 6729 "Valid" 6728 "Valid" 6727 "Valid" 6726 "Valid" 6725 "Valid" 6724 "Valid" 6723 "Valid" 6722 "Valid" 6721 "Valid" 6720 "Valid" 6719 "Valid" 6718 "Valid" 6717 "Valid" 6716 "Valid" 6715 "Valid" 6714 "Valid" 6713 "Valid" 6712 "Valid" 6711 "Valid" 6710 "Valid" 6709 "Valid" 6708 "Valid" 6707 "Valid" 6706 "Valid" 6705 "Valid" 6704 "Valid" 6703 "Valid" 6702 "Valid" 6701 "Valid" 6700 "Valid" 6699 "Valid" 6698 "Valid" 6697 "Valid" 6696 "Valid" 6695 "Valid" 6694 "Valid" 6693 "Valid" 6692 "Valid" 6691 "Valid" 6690 "Valid" 6689 "Valid" 6688 "Valid" 6687 "Valid" 6686 "Valid" 6685 "Valid" 6684 "Valid" 6683 "Valid" 6682 "Valid" 6681 "Valid" 6680 "Valid" 6679 "Valid" 6678 "Valid" 6677 "Valid" 6676 "Valid" 6675 "Valid" 6674 "Valid" 6673 "Valid" 6672 "Valid" 6671 "Valid" 6670 "Valid" 6669 "Valid" 6668 "Valid" 6667 "Valid" 6666 "Valid" 6665 "Valid" 6664 "Valid" 6663 "Valid" 6662 "Valid" 6661 "Valid" 6660 "Valid" 6659 "Valid" 6658 "Valid" 6657 "Valid" 6656 "Valid" 6655 "Valid" 6654 "Valid" 6653 "Valid" 6652 "Valid" 6651 "Valid" 6650 "Valid" 6649 "Valid" 6648 "Valid" 6647 "Valid" 6646 "Valid" 6645 "Valid" 6644 "Valid" 6643 "Valid" 6642 "Valid" 6641 "Valid" 6640 "Valid" 6639 "Valid" 6638 "Valid" 6637 "Valid" 6636 "Valid" 6635 "Valid" 6634 "Valid" 6633 "Valid" 6632 "Valid" 6631 "Valid" 6630 "Valid" 6629 "Valid" 6628 "Valid" 6627 "Valid" 6626 "Valid" 6625 "Valid" 6624 "Valid" 6623 "Valid" 6622 "Valid" 6621 "Valid" 6620 "Valid" 6619 "Valid" 6618 "Valid" 6617 "Valid" 6616 "Valid" 6615 "Valid" 6614 "Valid" 6613 "Valid" 6612 "Valid" 6611 "Valid" 6610 "Valid" 6609 "Valid" 6608 "Valid" 6607 "Valid" 6606 "Valid" 6605 "Valid" 6604 "Valid" 6603 "Valid" 6602 "Valid" 6601 "Valid" 6600 "Valid" 6599 "Valid" 6598 "Valid" 6597 "Valid" 6596 "Valid" 6595 "Valid" 6594 "Valid" 6593 "Valid" 6592 "Valid" 6591 "Valid" 6590 "Valid" 6589 "Valid" 6588 "Valid" 6587 "Valid" 6586 "Valid" 6585 "Valid" 6584 "Valid" 6583 "Valid" 6582 "Valid" 6581 "Valid" 6580 "Valid" 6579 "Valid" 6578 "Valid" 6577 "Valid" 6576 "Valid" 6575 "Valid" 6574 "Valid" 6573 "Valid" 6572 "Valid" 6571 "Valid" 6570 "Valid" 6569 "Valid" 6568 "Valid" 6567 "Valid" 6566 "Valid" 6565 "Valid" 6564 "Valid" 6563 "Valid" 6562 "Valid" 6561 "Valid" 6560 "Valid" 6559 "Valid" 6558 "Valid" 6557 "Valid" 6556 "Valid" 6555 "Valid" 6554 "Valid" 6553 "Valid" 6552 "Valid" 6551 "Valid" 6550 "Valid" 6549 "Valid" 6548 "Valid" 6547 "Valid" 6546 "Valid" 6545 "Valid" 6544 "Valid" 6543 "Valid" 6542 "Valid" 6541 "Valid" 6540 "Valid" 6539 "Valid" 6538 "Valid" 6537 "Valid" 6536 "Valid" 6535 "Valid" 6534 "Valid" 6533 "Valid" 6532 "Valid" 6531 "Valid" 6530 "Valid" 6529 "Valid" 6528 "Valid" 6527 "Valid" 6526 "Valid" 6525 "Valid" 6524 "Valid" 6523 "Valid" 6522 "Valid" 6521 "Valid" 6520 "Valid" 6519 "Valid" 6518 "Valid" 6517 "Valid" 6516 "Valid" 6515 "Valid" 6514 "Valid" 6513 "Valid" 6512 "Valid" 6511 "Valid" 6510 "Valid" 6509 "Valid" 6508 "Valid" 6507 "Valid" 6506 "Valid" 6505 "Valid" 6504 "Valid" 6503 "Valid" 6502 "Valid" 6501 "Valid" 6500 "Valid" 6499 "Valid" 6498 "Valid" 6497 "Valid" 6496 "Valid" 6495 "Valid" 6494 "Valid" 6493 "Valid" 6492 "Valid" 6491 "Valid" 6490 "Valid" 6489 "Valid" 6488 "Valid" 6487 "Valid" 6486 "Valid" 6485 "Valid" 6484 "Valid" 6483 "Valid" 6482 "Valid" 6481 "Valid" 6480 "Valid" 6479 "Valid" 6478 "Valid" 6477 "Valid" 6476 "Valid" 6475 "Valid" 6474 "Valid" 6473 "Valid" 6472 "Valid" 6471 "Valid" 6470 "Valid" 6469 "Valid" 6468 "Valid" 6467 "Valid" 6466 "Valid" 6465 "Valid" 6464 "Valid" 6463 "Valid" 6462 "Valid" 6461 "Valid" 6460 "Valid" 6459 "Valid" 6458 "Valid" 6457 "Valid" 6456 "Valid" 6455 "Valid" 6454 "Valid" 6453 "Valid" 6452 "Valid" 6451 "Valid" 6450 "Valid" 6449 "Valid" 6448 "Valid" 6447 "Valid" 6446 "Valid" 6445 "Valid" 6444 "Valid" 6443 "Valid" 6442 "Valid" 6441 "Valid" 6440 "Valid" 6439 "Valid" 6438 "Valid" 6437 "Valid" 6436 "Valid" 6435 "Valid" 6434 "Valid" 6433 "Valid" 6432 "Valid" 6431 "Valid" 6430 "Valid" 6429 "Valid" 6428 "Valid" 6427 "Valid" 6426 "Valid" 6425 "Valid" 6424 "Valid" 6423 "Valid" 6422 "Valid" 6421 "Valid" 6420 "Valid" 6419 "Valid" 6418 "Valid" 6417 "Valid" 6416 "Valid" 6415 "Valid" 6414 "Valid" 6413 "Valid" 6412 "Valid" 6411 "Valid" 6410 "Valid" 6409 "Valid" 6408 "Valid" 6407 "Valid" 6406 "Valid" 6405 "Valid" 6404 "Valid" 6403 "Valid" 6402 "Valid" 6401 "Valid" 6400 "Valid" 6399 "Valid" 6398 "Valid" 6397 "Valid" 6396 "Valid" 6395 "Valid" 6394 "Valid" 6393 "Valid" 6392 "Valid" 6391 "Valid" 6390 "Valid" 6389 "Valid" 6388 "Valid" 6387 "Valid" 6386 "Valid" 6385 "Valid" 6384 "Valid" 6383 "Valid" 6382 "Valid" 6381 "Valid" 6380 "Valid" 6379 "Valid" 6378 "Valid" 6377 "Valid" 6376 "Valid" 6375 "Valid" 6374 "Valid" 6373 "Valid" 6372 "Valid" 6371 "Valid" 6370 "Valid" 6369 "Valid" 6368 "Valid" 6367 "Valid" 6366 "Valid" 6365 "Valid" 6364 "Valid" 6363 "Valid" 6362 "Valid" 6361 "Valid" 6360 "Valid" 6359 "Valid" 6358 "Valid" 6357 "Valid" 6356 "Valid" 6355 "Valid" 6354 "Valid" 6353 "Valid" 6352 "Valid" 6351 "Valid" 6350 "Valid" 6349 "Valid" 6348 "Valid" 6347 "Valid" 6346 "Valid" 6345 "Valid" 6344 "Valid" 6343 "Valid" 6342 "Valid" 6341 "Valid" 6340 "Valid" 6339 "Valid" 6338 "Valid" 6337 "Valid" 6336 "Valid" 6335 "Valid" 6334 "Valid" 6333 "Valid" 6332 "Valid" 6331 "Valid" 6330 "Valid" 6329 "Valid" 6328 "Valid" 6327 "Valid" 6326 "Valid" 6325 "Valid" 6324 "Valid" 6323 "Valid" 6322 "Valid" 6321 "Valid" 6320 "Valid" 6319 "Valid" 6318 "Valid" 6317 "Valid" 6316 "Valid" 6315 "Valid" 6314 "Valid" 6313 "Valid" 6312 "Valid" 6311 "Valid" 6310 "Valid" 6309 "Valid" 6308 "Valid" 6307 "Valid" 6306 "Valid" 6305 "Valid" 6304 "Valid" 6303 "Valid" 6302 "Valid" 6301 "Valid" 6300 "Valid" 6299 "Valid" 6298 "Valid" 6297 "Valid" 6296 "Valid" 6295 "Valid" 6294 "Valid" 6293 "Valid" 6292 "Valid" 6291 "Valid" 6290 "Valid" 6289 "Valid" 6288 "Valid" 6287 "Valid" 6286 "Valid" 6285 "Valid" 6284 "Valid" 6283 "Valid" 6282 "Valid" 6281 "Valid" 6280 "Valid" 6279 "Valid" 6278 "Valid" 6277 "Valid" 6276 "Valid" 6275 "Valid" 6274 "Valid" 6273 "Valid" 6272 "Valid" 6271 "Valid" 6270 "Valid" 6269 "Valid" 6268 "Valid" 6267 "Valid" 6266 "Valid" 6265 "Valid" 6264 "Valid" 6263 "Valid" 6262 "Valid" 6261 "Valid" 6260 "Valid" 6259 "Valid" 6258 "Valid" 6257 "Valid" 6256 "Valid" 6255 "Valid" 6254 "Valid" 6253 "Valid" 6252 "Valid" 6251 "Valid" 6250 "Valid" 6249 "Valid" 6248 "Valid" 6247 "Valid" 6246 "Valid" 6245 "Valid" 6244 "Valid" 6243 "Valid" 6242 "Valid" 6241 "Valid" 6240 "Valid" 6239 "Valid" 6238 "Valid" 6237 "Valid" 6236 "Valid" 6235 "Valid" 6234 "Valid" 6233 "Valid" 6232 "Valid" 6231 "Valid" 6230 "Valid" 6229 "Valid" 6228 "Valid" 6227 "Valid" 6226 "Valid" 6225 "Valid" 6224 "Valid" 6223 "Valid" 6222 "Valid" 6221 "Valid" 6220 "Valid" 6219 "Valid" 6218 "Valid" 6217 "Valid" 6216 "Valid" 6215 "Valid" 6214 "Valid" 6213 "Valid" 6212 "Valid" 6211 "Valid" 6210 "Valid" 6209 "Valid" 6208 "Valid" 6207 "Valid" 6206 "Valid" 6205 "Valid" 6204 "Valid" 6203 "Valid" 6202 "Valid" 6201 "Valid" 6200 "Valid" 6199 "Valid" 6198 "Valid" 6197 "Valid" 6196 "Valid" 6195 "Valid" 6194 "Valid" 6193 "Valid" 6192 "Valid" 6191 "Valid" 6190 "Valid" 6189 "Valid" 6188 "Valid" 6187 "Valid" 6186 "Valid" 6185 "Valid" 6184 "Valid" 6183 "Valid" 6182 "Valid" 6181 "Valid" 6180 "Valid" 6179 "Valid" 6178 "Valid" 6177 "Valid" 6176 "Valid" 6175 "Valid" 6174 "Valid" 6173 "Valid" 6172 "Valid" 6171 "Valid" 6170 "Valid" 6169 "Valid" 6168 "Valid" 6167 "Valid" 6166 "Valid" 6165 "Valid" 6164 "Valid" 6163 "Valid" 6162 "Valid" 6161 "Valid" 6160 "Valid" 6159 "Valid" 6158 "Valid" 6157 "Valid" 6156 "Valid" 6155 "Valid" 6154 "Valid" 6153 "Valid" 6152 "Valid" 6151 "Valid" 6150 "Valid" 6149 "Valid" 6148 "Valid" 6147 "Valid" 6146 "Valid" 6145 "Valid" 6144 "Valid" 6143 "Valid" 6142 "Valid" 6141 "Valid" 6140 "Valid" 6139 "Valid" 6138 "Valid" 6137 "Valid" 6136 "Valid" 6135 "Valid" 6134 "Valid" 6133 "Valid" 6132 "Valid" 6131 "Valid" 6130 "Valid" 6129 "Valid" 6128 "Valid" 6127 "Valid" 6126 "Valid" 6125 "Valid" 6124 "Valid" 6123 "Valid" 6122 "Valid" 6121 "Valid" 6120 "Valid" 6119 "Valid" 6118 "Valid" 6117 "Valid" 6116 "Valid" 6115 "Valid" 6114 "Valid" 6113 "Valid" 6112 "Valid" 6111 "Valid" 6110 "Valid" 6109 "Valid" 6108 "Valid" 6107 "Valid" 6106 "Valid" 6105 "Valid" 6104 "Valid" 6103 "Valid" 6102 "Valid" 6101 "Valid" 6100 "Valid" 6099 "Valid" 6098 "Valid" 6097 "Valid" 6096 "Valid" 6095 "Valid" 6094 "Valid" 6093 "Valid" 6092 "Valid" 6091 "Valid" 6090 "Valid" 6089 "Valid" 6088 "Valid" 6087 "Valid" 6086 "Valid" 6085 "Valid" 6084 "Valid" 6083 "Valid" 6082 "Valid" 6081 "Valid" 6080 "Valid" 6079 "Valid" 6078 "Valid" 6077 "Valid" 6076 "Valid" 6075 "Valid" 6074 "Valid" 6073 "Valid" 6072 "Valid" 6071 "Valid" 6070 "Valid" 6069 "Valid" 6068 "Valid" 6067 "Valid" 6066 "Valid" 6065 "Valid" 6064 "Valid" 6063 "Valid" 6062 "Valid" 6061 "Valid" 6060 "Valid" 6059 "Valid" 6058 "Valid" 6057 "Valid" 6056 "Valid" 6055 "Valid" 6054 "Valid" 6053 "Valid" 6052 "Valid" 6051 "Valid" 6050 "Valid" 6049 "Valid" 6048 "Valid" 6047 "Valid" 6046 "Valid" 6045 "Valid" 6044 "Valid" 6043 "Valid" 6042 "Valid" 6041 "Valid" 6040 "Valid" 6039 "Valid" 6038 "Valid" 6037 "Valid" 6036 "Valid" 6035 "Valid" 6034 "Valid" 6033 "Valid" 6032 "Valid" 6031 "Valid" 6030 "Valid" 6029 "Valid" 6028 "Valid" 6027 "Valid" 6026 "Valid" 6025 "Valid" 6024 "Valid" 6023 "Valid" 6022 "Valid" 6021 "Valid" 6020 "Valid" 6019 "Valid" 6018 "Valid" 6017 "Valid" 6016 "Valid" 6015 "Valid" 6014 "Valid" 6013 "Valid" 6012 "Valid" 6011 "Valid" 6010 "Valid" 6009 "Valid" 6008 "Valid" 6007 "Valid" 6006 "Valid" 6005 "Valid" 6004 "Valid" 6003 "Valid" 6002 "Valid" 6001 "Valid" 6000 "Valid" 5999 "Valid" 5998 "Valid" 5997 "Valid" 5996 "Valid" 5995 "Valid" 5994 "Valid" 5993 "Valid" 5992 "Valid" 5991 "Valid" 5990 "Valid" 5989 "Valid" 5988 "Valid" 5987 "Valid" 5986 "Valid" 5985 "Valid" 5984 "Valid" 5983 "Valid" 5982 "Valid" 5981 "Valid" 5980 "Valid" 5979 "Valid" 5978 "Valid" 5977 "Valid" 5976 "Valid" 5975 "Valid" 5974 "Valid" 5973 "Valid" 5972 "Valid" 5971 "Valid" 5970 "Valid" 5969 "Valid" 5968 "Valid" 5967 "Valid" 5966 "Valid" 5965 "Valid" 5964 "Valid" 5963 "Valid" 5962 "Valid" 5961 "Valid" 5960 "Valid" 5959 "Valid" 5958 "Valid" 5957 "Valid" 5956 "Valid" 5955 "Valid" 5954 "Valid" 5953 "Valid" 5952 "Valid" 5951 "Valid" 5950 "Valid" 5949 "Valid" 5948 "Valid" 5947 "Valid" 5946 "Valid" 5945 "Valid" 5944 "Valid" 5943 "Valid" 5942 "Valid" 5941 "Valid" 5940 "Valid" 5939 "Valid" 5938 "Valid" 5937 "Valid" 5936 "Valid" 5935 "Valid" 5934 "Valid" 5933 "Valid" 5932 "Valid" 5931 "Valid" 5930 "Valid" 5929 "Valid" 5928 "Valid" 5927 "Valid" 5926 "Valid" 5925 "Valid" 5924 "Valid" 5923 "Valid" 5922 "Valid" 5921 "Valid" 5920 "Valid" 5919 "Valid" 5918 "Valid" 5917 "Valid" 5916 "Valid" 5915 "Valid" 5914 "Valid" 5913 "Valid" 5912 "Valid" 5911 "Valid" 5910 "Valid" 5909 "Valid" 5908 "Valid" 5907 "Valid" 5906 "Valid" 5905 "Valid" 5904 "Valid" 5903 "Valid" 5902 "Valid" 5901 "Valid" 5900 "Valid" 5899 "Valid" 5898 "Valid" 5897 "Valid" 5896 "Valid" 5895 "Valid" 5894 "Valid" 5893 "Valid" 5892 "Valid" 5891 "Valid" 5890 "Valid" 5889 "Valid" 5888 "Valid" 5887 "Valid" 5886 "Valid" 5885 "Valid" 5884 "Valid" 5883 "Valid" 5882 "Valid" 5881 "Valid" 5880 "Valid" 5879 "Valid" 5878 "Valid" 5877 "Valid" 5876 "Valid" 5875 "Valid" 5874 "Valid" 5873 "Valid" 5872 "Valid" 5871 "Valid" 5870 "Valid" 5869 "Valid" 5868 "Valid" 5867 "Valid" 5866 "Valid" 5865 "Valid" 5864 "Valid" 5863 "Valid" 5862 "Valid" 5861 "Valid" 5860 "Valid" 5859 "Valid" 5858 "Valid" 5857 "Valid" 5856 "Valid" 5855 "Valid" 5854 "Valid" 5853 "Valid" 5852 "Valid" 5851 "Valid" 5850 "Valid" 5849 "Valid" 5848 "Valid" 5847 "Valid" 5846 "Valid" 5845 "Valid" 5844 "Valid" 5843 "Valid" 5842 "Valid" 5841 "Valid" 5840 "Valid" 5839 "Valid" 5838 "Valid" 5837 "Valid" 5836 "Valid" 5835 "Valid" 5834 "Valid" 5833 "Valid" 5832 "Valid" 5831 "Valid" 5830 "Valid" 5829 "Valid" 5828 "Valid" 5827 "Valid" 5826 "Valid" 5825 "Valid" 5824 "Valid" 5823 "Valid" 5822 "Valid" 5821 "Valid" 5820 "Valid" 5819 "Valid" 5818 "Valid" 5817 "Valid" 5816 "Valid" 5815 "Valid" 5814 "Valid" 5813 "Valid" 5812 "Valid" 5811 "Valid" 5810 "Valid" 5809 "Valid" 5808 "Valid" 5807 "Valid" 5806 "Valid" 5805 "Valid" 5804 "Valid" 5803 "Valid" 5802 "Valid" 5801 "Valid" 5800 "Valid" 5799 "Valid" 5798 "Valid" 5797 "Valid" 5796 "Valid" 5795 "Valid" 5794 "Valid" 5793 "Valid" 5792 "Valid" 5791 "Valid" 5790 "Valid" 5789 "Valid" 5788 "Valid" 5787 "Valid" 5786 "Valid" 5785 "Valid" 5784 "Valid" 5783 "Valid" 5782 "Valid" 5781 "Valid" 5780 "Valid" 5779 "Valid" 5778 "Valid" 5777 "Valid" 5776 "Valid" 5775 "Valid" 5774 "Valid" 5773 "Valid" 5772 "Valid" 5771 "Valid" 5770 "Valid" 5769 "Valid" 5768 "Valid" 5767 "Valid" 5766 "Valid" 5765 "Valid" 5764 "Valid" 5763 "Valid" 5762 "Valid" 5761 "Valid" 5760 "Valid" 5759 "Valid" 5758 "Valid" 5757 "Valid" 5756 "Valid" 5755 "Valid" 5754 "Valid" 5753 "Valid" 5752 "Valid" 5751 "Valid" 5750 "Valid" 5749 "Valid" 5748 "Valid" 5747 "Valid" 5746 "Valid" 5745 "Valid" 5744 "Valid" 5743 "Valid" 5742 "Valid" 5741 "Valid" 5740 "Valid" 5739 "Valid" 5738 "Valid" 5737 "Valid" 5736 "Valid" 5735 "Valid" 5734 "Valid" 5733 "Valid" 5732 "Valid" 5731 "Valid" 5730 "Valid" 5729 "Valid" 5728 "Valid" 5727 "Valid" 5726 "Valid" 5725 "Valid" 5724 "Valid" 5723 "Valid" 5722 "Valid" 5721 "Valid" 5720 "Valid" 5719 "Valid" 5718 "Valid" 5717 "Valid" 5716 "Valid" 5715 "Valid" 5714 "Valid" 5713 "Valid" 5712 "Valid" 5711 "Valid" 5710 "Valid" 5709 "Valid" 5708 "Valid" 5707 "Valid" 5706 "Valid" 5705 "Valid" 5704 "Valid" 5703 "Valid" 5702 "Valid" 5701 "Valid" 5700 "Valid" 5699 "Valid" 5698 "Valid" 5697 "Valid" 5696 "Valid" 5695 "Valid" 5694 "Valid" 5693 "Valid" 5692 "Valid" 5691 "Valid" 5690 "Valid" 5689 "Valid" 5688 "Valid" 5687 "Valid" 5686 "Valid" 5685 "Valid" 5684 "Valid" 5683 "Valid" 5682 "Valid" 5681 "Valid" 5680 "Valid" 5679 "Valid" 5678 "Valid" 5677 "Valid" 5676 "Valid" 5675 "Valid" 5674 "Valid" 5673 "Valid" 5672 "Valid" 5671 "Valid" 5670 "Valid" 5669 "Valid" 5668 "Valid" 5667 "Valid" 5666 "Valid" 5665 "Valid" 5664 "Valid" 5663 "Valid" 5662 "Valid" 5661 "Valid" 5660 "Valid" 5659 "Valid" 5658 "Valid" 5657 "Valid" 5656 "Valid" 5655 "Valid" 5654 "Valid" 5653 "Valid" 5652 "Valid" 5651 "Valid" 5650 "Valid" 5649 "Valid" 5648 "Valid" 5647 "Valid" 5646 "Valid" 5645 "Valid" 5644 "Valid" 5643 "Valid" 5642 "Valid" 5641 "Valid" 5640 "Valid" 5639 "Valid" 5638 "Valid" 5637 "Valid" 5636 "Valid" 5635 "Valid" 5634 "Valid" 5633 "Valid" 5632 "Valid" 5631 "Valid" 5630 "Valid" 5629 "Valid" 5628 "Valid" 5627 "Valid" 5626 "Valid" 5625 "Valid" 5624 "Valid" 5623 "Valid" 5622 "Valid" 5621 "Valid" 5620 "Valid" 5619 "Valid" 5618 "Valid" 5617 "Valid" 5616 "Valid" 5615 "Valid" 5614 "Valid" 5613 "Valid" 5612 "Valid" 5611 "Valid" 5610 "Valid" 5609 "Valid" 5608 "Valid" 5607 "Valid" 5606 "Valid" 5605 "Valid" 5604 "Valid" 5603 "Valid" 5602 "Valid" 5601 "Valid" 5600 "Valid" 5599 "Valid" 5598 "Valid" 5597 "Valid" 5596 "Valid" 5595 "Valid" 5594 "Valid" 5593 "Valid" 5592 "Valid" 5591 "Valid" 5590 "Valid" 5589 "Valid" 5588 "Valid" 5587 "Valid" 5586 "Valid" 5585 "Valid" 5584 "Valid" 5583 "Valid" 5582 "Valid" 5581 "Valid" 5580 "Valid" 5579 "Valid" 5578 "Valid" 5577 "Valid" 5576 "Valid" 5575 "Valid" 5574 "Valid" 5573 "Valid" 5572 "Valid" 5571 "Valid" 5570 "Valid" 5569 "Valid" 5568 "Valid" 5567 "Valid" 5566 "Valid" 5565 "Valid" 5564 "Valid" 5563 "Valid" 5562 "Valid" 5561 "Valid" 5560 "Valid" 5559 "Valid" 5558 "Valid" 5557 "Valid" 5556 "Valid" 5555 "Valid" 5554 "Valid" 5553 "Valid" 5552 "Valid" 5551 "Valid" 5550 "Valid" 5549 "Valid" 5548 "Valid" 5547 "Valid" 5546 "Valid" 5545 "Valid" 5544 "Valid" 5543 "Valid" 5542 "Valid" 5541 "Valid" 5540 "Valid" 5539 "Valid" 5538 "Valid" 5537 "Valid" 5536 "Valid" 5535 "Valid" 5534 "Valid" 5533 "Valid" 5532 "Valid" 5531 "Valid" 5530 "Valid" 5529 "Valid" 5528 "Valid" 5527 "Valid" 5526 "Valid" 5525 "Valid" 5524 "Valid" 5523 "Valid" 5522 "Valid" 5521 "Valid" 5520 "Valid" 5519 "Valid" 5518 "Valid" 5517 "Valid" 5516 "Valid" 5515 "Valid" 5514 "Valid" 5513 "Valid" 5512 "Valid" 5511 "Valid" 5510 "Valid" 5509 "Valid" 5508 "Valid" 5507 "Valid" 5506 "Valid" 5505 "Valid" 5504 "Valid" 5503 "Valid" 5502 "Valid" 5501 "Valid" 5500 "Valid" 5499 "Valid" 5498 "Valid" 5497 "Valid" 5496 "Valid" 5495 "Valid" 5494 "Valid" 5493 "Valid" 5492 "Valid" 5491 "Valid" 5490 "Valid" 5489 "Valid" 5488 "Valid" 5487 "Valid" 5486 "Valid" 5485 "Valid" 5484 "Valid" 5483 "Valid" 5482 "Valid" 5481 "Valid" 5480 "Valid" 5479 "Valid" 5478 "Valid" 5477 "Valid" 5476 "Valid" 5475 "Valid" 5474 "Valid" 5473 "Valid" 5472 "Valid" 5471 "Valid" 5470 "Valid" 5469 "Valid" 5468 "Valid" 5467 "Valid" 5466 "Valid" 5465 "Valid" 5464 "Valid" 5463 "Valid" 5462 "Valid" 5461 "Valid" 5460 "Valid" 5459 "Valid" 5458 "Valid" 5457 "Valid" 5456 "Valid" 5455 "Valid" 5454 "Valid" 5453 "Valid" 5452 "Valid" 5451 "Valid" 5450 "Valid" 5449 "Valid" 5448 "Valid" 5447 "Valid" 5446 "Valid" 5445 "Valid" 5444 "Valid" 5443 "Valid" 5442 "Valid" 5441 "Valid" 5440 "Valid" 5439 "Valid" 5438 "Valid" 5437 "Valid" 5436 "Valid" 5435 "Valid" 5434 "Valid" 5433 "Valid" 5432 "Valid" 5431 "Valid" 5430 "Valid" 5429 "Valid" 5428 "Valid" 5427 "Valid" 5426 "Valid" 5425 "Valid" 5424 "Valid" 5423 "Valid" 5422 "Valid" 5421 "Valid" 5420 "Valid" 5419 "Valid" 5418 "Valid" 5417 "Valid" 5416 "Valid" 5415 "Valid" 5414 "Valid" 5413 "Valid" 5412 "Valid" 5411 "Valid" 5410 "Valid" 5409 "Valid" 5408 "Valid" 5407 "Valid" 5406 "Valid" 5405 "Valid" 5404 "Valid" 5403 "Valid" 5402 "Valid" 5401 "Valid" 5400 "Valid" 5399 "Valid" 5398 "Valid" 5397 "Valid" 5396 "Valid" 5395 "Valid" 5394 "Valid" 5393 "Valid" 5392 "Valid" 5391 "Valid" 5390 "Valid" 5389 "Valid" 5388 "Valid" 5387 "Valid" 5386 "Valid" 5385 "Valid" 5384 "Valid" 5383 "Valid" 5382 "Valid" 5381 "Valid" 5380 "Valid" 5379 "Valid" 5378 "Valid" 5377 "Valid" 5376 "Valid" 5375 "Valid" 5374 "Valid" 5373 "Valid" 5372 "Valid" 5371 "Valid" 5370 "Valid" 5369 "Valid" 5368 "Valid" 5367 "Valid" 5366 "Valid" 5365 "Valid" 5364 "Valid" 5363 "Valid" 5362 "Valid" 5361 "Valid" 5360 "Valid" 5359 "Valid" 5358 "Valid" 5357 "Valid" 5356 "Valid" 5355 "Valid" 5354 "Valid" 5353 "Valid" 5352 "Valid" 5351 "Valid" 5350 "Valid" 5349 "Valid" 5348 "Valid" 5347 "Valid" 5346 "Valid" 5345 "Valid" 5344 "Valid" 5343 "Valid" 5342 "Valid" 5341 "Valid" 5340 "Valid" 5339 "Valid" 5338 "Valid" 5337 "Valid" 5336 "Valid" 5335 "Valid" 5334 "Valid" 5333 "Valid" 5332 "Valid" 5331 "Valid" 5330 "Valid" 5329 "Valid" 5328 "Valid" 5327 "Valid" 5326 "Valid" 5325 "Valid" 5324 "Valid" 5323 "Valid" 5322 "Valid" 5321 "Valid" 5320 "Valid" 5319 "Valid" 5318 "Valid" 5317 "Valid" 5316 "Valid" 5315 "Valid" 5314 "Valid" 5313 "Valid" 5312 "Valid" 5311 "Valid" 5310 "Valid" 5309 "Valid" 5308 "Valid" 5307 "Valid" 5306 "Valid" 5305 "Valid" 5304 "Valid" 5303 "Valid" 5302 "Valid" 5301 "Valid" 5300 "Valid" 5299 "Valid" 5298 "Valid" 5297 "Valid" 5296 "Valid" 5295 "Valid" 5294 "Valid" 5293 "Valid" 5292 "Valid" 5291 "Valid" 5290 "Valid" 5289 "Valid" 5288 "Valid" 5287 "Valid" 5286 "Valid" 5285 "Valid" 5284 "Valid" 5283 "Valid" 5282 "Valid" 5281 "Valid" 5280 "Valid" 5279 "Valid" 5278 "Valid" 5277 "Valid" 5276 "Valid" 5275 "Valid" 5274 "Valid" 5273 "Valid" 5272 "Valid" 5271 "Valid" 5270 "Valid" 5269 "Valid" 5268 "Valid" 5267 "Valid" 5266 "Valid" 5265 "Valid" 5264 "Valid" 5263 "Valid" 5262 "Valid" 5261 "Valid" 5260 "Valid" 5259 "Valid" 5258 "Valid" 5257 "Valid" 5256 "Valid" 5255 "Valid" 5254 "Valid" 5253 "Valid" 5252 "Valid" 5251 "Valid" 5250 "Valid" 5249 "Valid" 5248 "Valid" 5247 "Valid" 5246 "Valid" 5245 "Valid" 5244 "Valid" 5243 "Valid" 5242 "Valid" 5241 "Valid" 5240 "Valid" 5239 "Valid" 5238 "Valid" 5237 "Valid" 5236 "Valid" 5235 "Valid" 5234 "Valid" 5233 "Valid" 5232 "Valid" 5231 "Valid" 5230 "Valid" 5229 "Valid" 5228 "Valid" 5227 "Valid" 5226 "Valid" 5225 "Valid" 5224 "Valid" 5223 "Valid" 5222 "Valid" 5221 "Valid" 5220 "Valid" 5219 "Valid" 5218 "Valid" 5217 "Valid" 5216 "Valid" 5215 "Valid" 5214 "Valid" 5213 "Valid" 5212 "Valid" 5211 "Valid" 5210 "Valid" 5209 "Valid" 5208 "Valid" 5207 "Valid" 5206 "Valid" 5205 "Valid" 5204 "Valid" 5203 "Valid" 5202 "Valid" 5201 "Valid" 5200 "Valid" 5199 "Valid" 5198 "Valid" 5197 "Valid" 5196 "Valid" 5195 "Valid" 5194 "Valid" 5193 "Valid" 5192 "Valid" 5191 "Valid" 5190 "Valid" 5189 "Valid" 5188 "Valid" 5187 "Valid" 5186 "Valid" 5185 "Valid" 5184 "Valid" 5183 "Valid" 5182 "Valid" 5181 "Valid" 5180 "Valid" 5179 "Valid" 5178 "Valid" 5177 "Valid" 5176 "Valid" 5175 "Valid" 5174 "Valid" 5173 "Valid" 5172 "Valid" 5171 "Valid" 5170 "Valid" 5169 "Valid" 5168 "Valid" 5167 "Valid" 5166 "Valid" 5165 "Valid" 5164 "Valid" 5163 "Valid" 5162 "Valid" 5161 "Valid" 5160 "Valid" 5159 "Valid" 5158 "Valid" 5157 "Valid" 5156 "Valid" 5155 "Valid" 5154 "Valid" 5153 "Valid" 5152 "Valid" 5151 "Valid" 5150 "Valid" 5149 "Valid" 5148 "Valid" 5147 "Valid" 5146 "Valid" 5145 "Valid" 5144 "Valid" 5143 "Valid" 5142 "Valid" 5141 "Valid" 5140 "Valid" 5139 "Valid" 5138 "Valid" 5137 "Valid" 5136 "Valid" 5135 "Valid" 5134 "Valid" 5133 "Valid" 5132 "Valid" 5131 "Valid" 5130 "Valid" 5129 "Valid" 5128 "Valid" 5127 "Valid" 5126 "Valid" 5125 "Valid" 5124 "Valid" 5123 "Valid" 5122 "Valid" 5121 "Valid" 5120 "Valid" 5119 "Valid" 5118 "Valid" 5117 "Valid" 5116 "Valid" 5115 "Valid" 5114 "Valid" 5113 "Valid" 5112 "Valid" 5111 "Valid" 5110 "Valid" 5109 "Valid" 5108 "Valid" 5107 "Valid" 5106 "Valid" 5105 "Valid" 5104 "Valid" 5103 "Valid" 5102 "Valid" 5101 "Valid" 5100 "Valid" 5099 "Valid" 5098 "Valid" 5097 "Valid" 5096 "Valid" 5095 "Valid" 5094 "Valid" 5093 "Valid" 5092 "Valid" 5091 "Valid" 5090 "Valid" 5089 "Valid" 5088 "Valid" 5087 "Valid" 5086 "Valid" 5085 "Valid" 5084 "Valid" 5083 "Valid" 5082 "Valid" 5081 "Valid" 5080 "Valid" 5079 "Valid" 5078 "Valid" 5077 "Valid" 5076 "Valid" 5075 "Valid" 5074 "Valid" 5073 "Valid" 5072 "Valid" 5071 "Valid" 5070 "Valid" 5069 "Valid" 5068 "Valid" 5067 "Valid" 5066 "Valid" 5065 "Valid" 5064 "Valid" 5063 "Valid" 5062 "Valid" 5061 "Valid" 5060 "Valid" 5059 "Valid" 5058 "Valid" 5057 "Valid" 5056 "Valid" 5055 "Valid" 5054 "Valid" 5053 "Valid" 5052 "Valid" 5051 "Valid" 5050 "Valid" 5049 "Valid" 5048 "Valid" 5047 "Valid" 5046 "Valid" 5045 "Valid" 5044 "Valid" 5043 "Valid" 5042 "Valid" 5041 "Valid" 5040 "Valid" 5039 "Valid" 5038 "Valid" 5037 "Valid" 5036 "Valid" 5035 "Valid" 5034 "Valid" 5033 "Valid" 5032 "Valid" 5031 "Valid" 5030 "Valid" 5029 "Valid" 5028 "Valid" 5027 "Valid" 5026 "Valid" 5025 "Valid" 5024 "Valid" 5023 "Valid" 5022 "Valid" 5021 "Valid" 5020 "Valid" 5019 "Valid" 5018 "Valid" 5017 "Valid" 5016 "Valid" 5015 "Valid" 5014 "Valid" 5013 "Valid" 5012 "Valid" 5011 "Valid" 5010 "Valid" 5009 "Valid" 5008 "Valid" 5007 "Valid" 5006 "Valid" 5005 "Valid" 5004 "Valid" 5003 "Valid" 5002 "Valid" 5001 "Valid" 5000 "Valid" 4999 "Valid" 4998 "Valid" 4997 "Valid" 4996 "Valid" 4995 "Valid" 4994 "Valid" 4993 "Valid" 4992 "Valid" 4991 "Valid" 4990 "Valid" 4989 "Valid" 4988 "Valid" 4987 "Valid" 4986 "Valid" 4985 "Valid" 4984 "Valid" 4983 "Valid" 4982 "Valid" 4981 "Valid" 4980 "Valid" 4979 "Valid" 4978 "Valid" 4977 "Valid" 4976 "Valid" 4975 "Valid" 4974 "Valid" 4973 "Valid" 4972 "Valid" 4971 "Valid" 4970 "Valid" 4969 "Valid" 4968 "Valid" 4967 "Valid" 4966 "Valid" 4965 "Valid" 4964 "Valid" 4963 "Valid" 4962 "Valid" 4961 "Valid" 4960 "Valid" 4959 "Valid" 4958 "Valid" 4957 "Valid" 4956 "Valid" 4955 "Valid" 4954 "Valid" 4953 "Valid" 4952 "Valid" 4951 "Valid" 4950 "Valid" 4949 "Valid" 4948 "Valid" 4947 "Valid" 4946 "Valid" 4945 "Valid" 4944 "Valid" 4943 "Valid" 4942 "Valid" 4941 "Valid" 4940 "Valid" 4939 "Valid" 4938 "Valid" 4937 "Valid" 4936 "Valid" 4935 "Valid" 4934 "Valid" 4933 "Valid" 4932 "Valid" 4931 "Valid" 4930 "Valid" 4929 "Valid" 4928 "Valid" 4927 "Valid" 4926 "Valid" 4925 "Valid" 4924 "Valid" 4923 "Valid" 4922 "Valid" 4921 "Valid" 4920 "Valid" 4919 "Valid" 4918 "Valid" 4917 "Valid" 4916 "Valid" 4915 "Valid" 4914 "Valid" 4913 "Valid" 4912 "Valid" 4911 "Valid" 4910 "Valid" 4909 "Valid" 4908 "Valid" 4907 "Valid" 4906 "Valid" 4905 "Valid" 4904 "Valid" 4903 "Valid" 4902 "Valid" 4901 "Valid" 4900 "Valid" 4899 "Valid" 4898 "Valid" 4897 "Valid" 4896 "Valid" 4895 "Valid" 4894 "Valid" 4893 "Valid" 4892 "Valid" 4891 "Valid" 4890 "Valid" 4889 "Valid" 4888 "Valid" 4887 "Valid" 4886 "Valid" 4885 "Valid" 4884 "Valid" 4883 "Valid" 4882 "Valid" 4881 "Valid" 4880 "Valid" 4879 "Valid" 4878 "Valid" 4877 "Valid" 4876 "Valid" 4875 "Valid" 4874 "Valid" 4873 "Valid" 4872 "Valid" 4871 "Valid" 4870 "Valid" 4869 "Valid" 4868 "Valid" 4867 "Valid" 4866 "Valid" 4865 "Valid" 4864 "Valid" 4863 "Valid" 4862 "Valid" 4861 "Valid" 4860 "Valid" 4859 "Valid" 4858 "Valid" 4857 "Valid" 4856 "Valid" 4855 "Valid" 4854 "Valid" 4853 "Valid" 4852 "Valid" 4851 "Valid" 4850 "Valid" 4849 "Valid" 4848 "Valid" 4847 "Valid" 4846 "Valid" 4845 "Valid" 4844 "Valid" 4843 "Valid" 4842 "Valid" 4841 "Valid" 4840 "Valid" 4839 "Valid" 4838 "Valid" 4837 "Valid" 4836 "Valid" 4835 "Valid" 4834 "Valid" 4833 "Valid" 4832 "Valid" 4831 "Valid" 4830 "Valid" 4829 "Valid" 4828 "Valid" 4827 "Valid" 4826 "Valid" 4825 "Valid" 4824 "Valid" 4823 "Valid" 4822 "Valid" 4821 "Valid" 4820 "Valid" 4819 "Valid" 4818 "Valid" 4817 "Valid" 4816 "Valid" 4815 "Valid" 4814 "Valid" 4813 "Valid" 4812 "Valid" 4811 "Valid" 4810 "Valid" 4809 "Valid" 4808 "Valid" 4807 "Valid" 4806 "Valid" 4805 "Valid" 4804 "Valid" 4803 "Valid" 4802 "Valid" 4801 "Valid" 4800 "Valid" 4799 "Valid" 4798 "Valid" 4797 "Valid" 4796 "Valid" 4795 "Valid" 4794 "Valid" 4793 "Valid" 4792 "Valid" 4791 "Valid" 4790 "Valid" 4789 "Valid" 4788 "Valid" 4787 "Valid" 4786 "Valid" 4785 "Valid" 4784 "Valid" 4783 "Valid" 4782 "Valid" 4781 "Valid" 4780 "Valid" 4779 "Valid" 4778 "Valid" 4777 "Valid" 4776 "Valid" 4775 "Valid" 4774 "Valid" 4773 "Valid" 4772 "Valid" 4771 "Valid" 4770 "Valid" 4769 "Valid" 4768 "Valid" 4767 "Valid" 4766 "Valid" 4765 "Valid" 4764 "Valid" 4763 "Valid" 4762 "Valid" 4761 "Valid" 4760 "Valid" 4759 "Valid" 4758 "Valid" 4757 "Valid" 4756 "Valid" 4755 "Valid" 4754 "Valid" 4753 "Valid" 4752 "Valid" 4751 "Valid" 4750 "Valid" 4749 "Valid" 4748 "Valid" 4747 "Valid" 4746 "Valid" 4745 "Valid" 4744 "Valid" 4743 "Valid" 4742 "Valid" 4741 "Valid" 4740 "Valid" 4739 "Valid" 4738 "Valid" 4737 "Valid" 4736 "Valid" 4735 "Valid" 4734 "Valid" 4733 "Valid" 4732 "Valid" 4731 "Valid" 4730 "Valid" 4729 "Valid" 4728 "Valid" 4727 "Valid" 4726 "Valid" 4725 "Valid" 4724 "Valid" 4723 "Valid" 4722 "Valid" 4721 "Valid" 4720 "Valid" 4719 "Valid" 4718 "Valid" 4717 "Valid" 4716 "Valid" 4715 "Valid" 4714 "Valid" 4713 "Valid" 4712 "Valid" 4711 "Valid" 4710 "Valid" 4709 "Valid" 4708 "Valid" 4707 "Valid" 4706 "Valid" 4705 "Valid" 4704 "Valid" 4703 "Valid" 4702 "Valid" 4701 "Valid" 4700 "Valid" 4699 "Valid" 4698 "Valid" 4697 "Valid" 4696 "Valid" 4695 "Valid" 4694 "Valid" 4693 "Valid" 4692 "Valid" 4691 "Valid" 4690 "Valid" 4689 "Valid" 4688 "Valid" 4687 "Valid" 4686 "Valid" 4685 "Valid" 4684 "Valid" 4683 "Valid" 4682 "Valid" 4681 "Valid" 4680 "Valid" 4679 "Valid" 4678 "Valid" 4677 "Valid" 4676 "Valid" 4675 "Valid" 4674 "Valid" 4673 "Valid" 4672 "Valid" 4671 "Valid" 4670 "Valid" 4669 "Valid" 4668 "Valid" 4667 "Valid" 4666 "Valid" 4665 "Valid" 4664 "Valid" 4663 "Valid" 4662 "Valid" 4661 "Valid" 4660 "Valid" 4659 "Valid" 4658 "Valid" 4657 "Valid" 4656 "Valid" 4655 "Valid" 4654 "Valid" 4653 "Valid" 4652 "Valid" 4651 "Valid" 4650 "Valid" 4649 "Valid" 4648 "Valid" 4647 "Valid" 4646 "Valid" 4645 "Valid" 4644 "Valid" 4643 "Valid" 4642 "Valid" 4641 "Valid" 4640 "Valid" 4639 "Valid" 4638 "Valid" 4637 "Valid" 4636 "Valid" 4635 "Valid" 4634 "Valid" 4633 "Valid" 4632 "Valid" 4631 "Valid" 4630 "Valid" 4629 "Valid" 4628 "Valid" 4627 "Valid" 4626 "Valid" 4625 "Valid" 4624 "Valid" 4623 "Valid" 4622 "Valid" 4621 "Valid" 4620 "Valid" 4619 "Valid" 4618 "Valid" 4617 "Valid" 4616 "Valid" 4615 "Valid" 4614 "Valid" 4613 "Valid" 4612 "Valid" 4611 "Valid" 4610 "Valid" 4609 "Valid" 4608 "Valid" 4607 "Valid" 4606 "Valid" 4605 "Valid" 4604 "Valid" 4603 "Valid" 4602 "Valid" 4601 "Valid" 4600 "Valid" 4599 "Valid" 4598 "Valid" 4597 "Valid" 4596 "Valid" 4595 "Valid" 4594 "Valid" 4593 "Valid" 4592 "Valid" 4591 "Valid" 4590 "Valid" 4589 "Valid" 4588 "Valid" 4587 "Valid" 4586 "Valid" 4585 "Valid" 4584 "Valid" 4583 "Valid" 4582 "Valid" 4581 "Valid" 4580 "Valid" 4579 "Valid" 4578 "Valid" 4577 "Valid" 4576 "Valid" 4575 "Valid" 4574 "Valid" 4573 "Valid" 4572 "Valid" 4571 "Valid" 4570 "Valid" 4569 "Valid" 4568 "Valid" 4567 "Valid" 4566 "Valid" 4565 "Valid" 4564 "Valid" 4563 "Valid" 4562 "Valid" 4561 "Valid" 4560 "Valid" 4559 "Valid" 4558 "Valid" 4557 "Valid" 4556 "Valid" 4555 "Valid" 4554 "Valid" 4553 "Valid" 4552 "Valid" 4551 "Valid" 4550 "Valid" 4549 "Valid" 4548 "Valid" 4547 "Valid" 4546 "Valid" 4545 "Valid" 4544 "Valid" 4543 "Valid" 4542 "Valid" 4541 "Valid" 4540 "Valid" 4539 "Valid" 4538 "Valid" 4537 "Valid" 4536 "Valid" 4535 "Valid" 4534 "Valid" 4533 "Valid" 4532 "Valid" 4531 "Valid" 4530 "Valid" 4529 "Valid" 4528 "Valid" 4527 "Valid" 4526 "Valid" 4525 "Valid" 4524 "Valid" 4523 "Valid" 4522 "Valid" 4521 "Valid" 4520 "Valid" 4519 "Valid" 4518 "Valid" 4517 "Valid" 4516 "Valid" 4515 "Valid" 4514 "Valid" 4513 "Valid" 4512 "Valid" 4511 "Valid" 4510 "Valid" 4509 "Valid" 4508 "Valid" 4507 "Valid" 4506 "Valid" 4505 "Valid" 4504 "Valid" 4503 "Valid" 4502 "Valid" 4501 "Valid" 4500 "Valid" 4499 "Valid" 4498 "Valid" 4497 "Valid" 4496 "Valid" 4495 "Valid" 4494 "Valid" 4493 "Valid" 4492 "Valid" 4491 "Valid" 4490 "Valid" 4489 "Valid" 4488 "Valid" 4487 "Valid" 4486 "Valid" 4485 "Valid" 4484 "Valid" 4483 "Valid" 4482 "Valid" 4481 "Valid" 4480 "Valid" 4479 "Valid" 4478 "Valid" 4477 "Valid" 4476 "Valid" 4475 "Valid" 4474 "Valid" 4473 "Valid" 4472 "Valid" 4471 "Valid" 4470 "Valid" 4469 "Valid" 4468 "Valid" 4467 "Valid" 4466 "Valid" 4465 "Valid" 4464 "Valid" 4463 "Valid" 4462 "Valid" 4461 "Valid" 4460 "Valid" 4459 "Valid" 4458 "Valid" 4457 "Valid" 4456 "Valid" 4455 "Valid" 4454 "Valid" 4453 "Valid" 4452 "Valid" 4451 "Valid" 4450 "Valid" 4449 "Valid" 4448 "Valid" 4447 "Valid" 4446 "Valid" 4445 "Valid" 4444 "Valid" 4443 "Valid" 4442 "Valid" 4441 "Valid" 4440 "Valid" 4439 "Valid" 4438 "Valid" 4437 "Valid" 4436 "Valid" 4435 "Valid" 4434 "Valid" 4433 "Valid" 4432 "Valid" 4431 "Valid" 4430 "Valid" 4429 "Valid" 4428 "Valid" 4427 "Valid" 4426 "Valid" 4425 "Valid" 4424 "Valid" 4423 "Valid" 4422 "Valid" 4421 "Valid" 4420 "Valid" 4419 "Valid" 4418 "Valid" 4417 "Valid" 4416 "Valid" 4415 "Valid" 4414 "Valid" 4413 "Valid" 4412 "Valid" 4411 "Valid" 4410 "Valid" 4409 "Valid" 4408 "Valid" 4407 "Valid" 4406 "Valid" 4405 "Valid" 4404 "Valid" 4403 "Valid" 4402 "Valid" 4401 "Valid" 4400 "Valid" 4399 "Valid" 4398 "Valid" 4397 "Valid" 4396 "Valid" 4395 "Valid" 4394 "Valid" 4393 "Valid" 4392 "Valid" 4391 "Valid" 4390 "Valid" 4389 "Valid" 4388 "Valid" 4387 "Valid" 4386 "Valid" 4385 "Valid" 4384 "Valid" 4383 "Valid" 4382 "Valid" 4381 "Valid" 4380 "Valid" 4379 "Valid" 4378 "Valid" 4377 "Valid" 4376 "Valid" 4375 "Valid" 4374 "Valid" 4373 "Valid" 4372 "Valid" 4371 "Valid" 4370 "Valid" 4369 "Valid" 4368 "Valid" 4367 "Valid" 4366 "Valid" 4365 "Valid" 4364 "Valid" 4363 "Valid" 4362 "Valid" 4361 "Valid" 4360 "Valid" 4359 "Valid" 4358 "Valid" 4357 "Valid" 4356 "Valid" 4355 "Valid" 4354 "Valid" 4353 "Valid" 4352 "Valid" 4351 "Valid" 4350 "Valid" 4349 "Valid" 4348 "Valid" 4347 "Valid" 4346 "Valid" 4345 "Valid" 4344 "Valid" 4343 "Valid" 4342 "Valid" 4341 "Valid" 4340 "Valid" 4339 "Valid" 4338 "Valid" 4337 "Valid" 4336 "Valid" 4335 "Valid" 4334 "Valid" 4333 "Valid" 4332 "Valid" 4331 "Valid" 4330 "Valid" 4329 "Valid" 4328 "Valid" 4327 "Valid" 4326 "Valid" 4325 "Valid" 4324 "Valid" 4323 "Valid" 4322 "Valid" 4321 "Valid" 4320 "Valid" 4319 "Valid" 4318 "Valid" 4317 "Valid" 4316 "Valid" 4315 "Valid" 4314 "Valid" 4313 "Valid" 4312 "Valid" 4311 "Valid" 4310 "Valid" 4309 "Valid" 4308 "Valid" 4307 "Valid" 4306 "Valid" 4305 "Valid" 4304 "Valid" 4303 "Valid" 4302 "Valid" 4301 "Valid" 4300 "Valid" 4299 "Valid" 4298 "Valid" 4297 "Valid" 4296 "Valid" 4295 "Valid" 4294 "Valid" 4293 "Valid" 4292 "Valid" 4291 "Valid" 4290 "Valid" 4289 "Valid" 4288 "Valid" 4287 "Valid" 4286 "Valid" 4285 "Valid" 4284 "Valid" 4283 "Valid" 4282 "Valid" 4281 "Valid" 4280 "Valid" 4279 "Valid" 4278 "Valid" 4277 "Valid" 4276 "Valid" 4275 "Valid" 4274 "Valid" 4273 "Valid" 4272 "Valid" 4271 "Valid" 4270 "Valid" 4269 "Valid" 4268 "Valid" 4267 "Valid" 4266 "Valid" 4265 "Valid" 4264 "Valid" 4263 "Valid" 4262 "Valid" 4261 "Valid" 4260 "Valid" 4259 "Valid" 4258 "Valid" 4257 "Valid" 4256 "Valid" 4255 "Valid" 4254 "Valid" 4253 "Valid" 4252 "Valid" 4251 "Valid" 4250 "Valid" 4249 "Valid" 4248 "Valid" 4247 "Valid" 4246 "Valid" 4245 "Valid" 4244 "Valid" 4243 "Valid" 4242 "Valid" 4241 "Valid" 4240 "Valid" 4239 "Valid" 4238 "Valid" 4237 "Valid" 4236 "Valid" 4235 "Valid" 4234 "Valid" 4233 "Valid" 4232 "Valid" 4231 "Valid" 4230 "Valid" 4229 "Valid" 4228 "Valid" 4227 "Valid" 4226 "Valid" 4225 "Valid" 4224 "Valid" 4223 "Valid" 4222 "Valid" 4221 "Valid" 4220 "Valid" 4219 "Valid" 4218 "Valid" 4217 "Valid" 4216 "Valid" 4215 "Valid" 4214 "Valid" 4213 "Valid" 4212 "Valid" 4211 "Valid" 4210 "Valid" 4209 "Valid" 4208 "Valid" 4207 "Valid" 4206 "Valid" 4205 "Valid" 4204 "Valid" 4203 "Valid" 4202 "Valid" 4201 "Valid" 4200 "Valid" 4199 "Valid" 4198 "Valid" 4197 "Valid" 4196 "Valid" 4195 "Valid" 4194 "Valid" 4193 "Valid" 4192 "Valid" 4191 "Valid" 4190 "Valid" 4189 "Valid" 4188 "Valid" 4187 "Valid" 4186 "Valid" 4185 "Valid" 4184 "Valid" 4183 "Valid" 4182 "Valid" 4181 "Valid" 4180 "Valid" 4179 "Valid" 4178 "Valid" 4177 "Valid" 4176 "Valid" 4175 "Valid" 4174 "Valid" 4173 "Valid" 4172 "Valid" 4171 "Valid" 4170 "Valid" 4169 "Valid" 4168 "Valid" 4167 "Valid" 4166 "Valid" 4165 "Valid" 4164 "Valid" 4163 "Valid" 4162 "Valid" 4161 "Valid" 4160 "Valid" 4159 "Valid" 4158 "Valid" 4157 "Valid" 4156 "Valid" 4155 "Valid" 4154 "Valid" 4153 "Valid" 4152 "Valid" 4151 "Valid" 4150 "Valid" 4149 "Valid" 4148 "Valid" 4147 "Valid" 4146 "Valid" 4145 "Valid" 4144 "Valid" 4143 "Valid" 4142 "Valid" 4141 "Valid" 4140 "Valid" 4139 "Valid" 4138 "Valid" 4137 "Valid" 4136 "Valid" 4135 "Valid" 4134 "Valid" 4133 "Valid" 4132 "Valid" 4131 "Valid" 4130 "Valid" 4129 "Valid" 4128 "Valid" 4127 "Valid" 4126 "Valid" 4125 "Valid" 4124 "Valid" 4123 "Valid" 4122 "Valid" 4121 "Valid" 4120 "Valid" 4119 "Valid" 4118 "Valid" 4117 "Valid" 4116 "Valid" 4115 "Valid" 4114 "Valid" 4113 "Valid" 4112 "Valid" 4111 "Valid" 4110 "Valid" 4109 "Valid" 4108 "Valid" 4107 "Valid" 4106 "Valid" 4105 "Valid" 4104 "Valid" 4103 "Valid" 4102 "Valid" 4101 "Valid" 4100 "Valid" 4099 "Valid" 4098 "Valid" 4097 "Valid" 4096 "Valid" 4095 "Valid" 4094 "Valid" 4093 "Valid" 4092 "Valid" 4091 "Valid" 4090 "Valid" 4089 "Valid" 4088 "Valid" 4087 "Valid" 4086 "Valid" 4085 "Valid" 4084 "Valid" 4083 "Valid" 4082 "Valid" 4081 "Valid" 4080 "Valid" 4079 "Valid" 4078 "Valid" 4077 "Valid" 4076 "Valid" 4075 "Valid" 4074 "Valid" 4073 "Valid" 4072 "Valid" 4071 "Valid" 4070 "Valid" 4069 "Valid" 4068 "Valid" 4067 "Valid" 4066 "Valid" 4065 "Valid" 4064 "Valid" 4063 "Valid" 4062 "Valid" 4061 "Valid" 4060 "Valid" 4059 "Valid" 4058 "Valid" 4057 "Valid" 4056 "Valid" 4055 "Valid" 4054 "Valid" 4053 "Valid" 4052 "Valid" 4051 "Valid" 4050 "Valid" 4049 "Valid" 4048 "Valid" 4047 "Valid" 4046 "Valid" 4045 "Valid" 4044 "Valid" 4043 "Valid" 4042 "Valid" 4041 "Valid" 4040 "Valid" 4039 "Valid" 4038 "Valid" 4037 "Valid" 4036 "Valid" 4035 "Valid" 4034 "Valid" 4033 "Valid" 4032 "Valid" 4031 "Valid" 4030 "Valid" 4029 "Valid" 4028 "Valid" 4027 "Valid" 4026 "Valid" 4025 "Valid" 4024 "Valid" 4023 "Valid" 4022 "Valid" 4021 "Valid" 4020 "Valid" 4019 "Valid" 4018 "Valid" 4017 "Valid" 4016 "Valid" 4015 "Valid" 4014 "Valid" 4013 "Valid" 4012 "Valid" 4011 "Valid" 4010 "Valid" 4009 "Valid" 4008 "Valid" 4007 "Valid" 4006 "Valid" 4005 "Valid" 4004 "Valid" 4003 "Valid" 4002 "Valid" 4001 "Valid" 4000 "Valid" 3999 "Valid" 3998 "Valid" 3997 "Valid" 3996 "Valid" 3995 "Valid" 3994 "Valid" 3993 "Valid" 3992 "Valid" 3991 "Valid" 3990 "Valid" 3989 "Valid" 3988 "Valid" 3987 "Valid" 3986 "Valid" 3985 "Valid" 3984 "Valid" 3983 "Valid" 3982 "Valid" 3981 "Valid" 3980 "Valid" 3979 "Valid" 3978 "Valid" 3977 "Valid" 3976 "Valid" 3975 "Valid" 3974 "Valid" 3973 "Valid" 3972 "Valid" 3971 "Valid" 3970 "Valid" 3969 "Valid" 3968 "Valid" 3967 "Valid" 3966 "Valid" 3965 "Valid" 3964 "Valid" 3963 "Valid" 3962 "Valid" 3961 "Valid" 3960 "Valid" 3959 "Valid" 3958 "Valid" 3957 "Valid" 3956 "Valid" 3955 "Valid" 3954 "Valid" 3953 "Valid" 3952 "Valid" 3951 "Valid" 3950 "Valid" 3949 "Valid" 3948 "Valid" 3947 "Valid" 3946 "Valid" 3945 "Valid" 3944 "Valid" 3943 "Valid" 3942 "Valid" 3941 "Valid" 3940 "Valid" 3939 "Valid" 3938 "Valid" 3937 "Valid" 3936 "Valid" 3935 "Valid" 3934 "Valid" 3933 "Valid" 3932 "Valid" 3931 "Valid" 3930 "Valid" 3929 "Valid" 3928 "Valid" 3927 "Valid" 3926 "Valid" 3925 "Valid" 3924 "Valid" 3923 "Valid" 3922 "Valid" 3921 "Valid" 3920 "Valid" 3919 "Valid" 3918 "Valid" 3917 "Valid" 3916 "Valid" 3915 "Valid" 3914 "Valid" 3913 "Valid" 3912 "Valid" 3911 "Valid" 3910 "Valid" 3909 "Valid" 3908 "Valid" 3907 "Valid" 3906 "Valid" 3905 "Valid" 3904 "Valid" 3903 "Valid" 3902 "Valid" 3901 "Valid" 3900 "Valid" 3899 "Valid" 3898 "Valid" 3897 "Valid" 3896 "Valid" 3895 "Valid" 3894 "Valid" 3893 "Valid" 3892 "Valid" 3891 "Valid" 3890 "Valid" 3889 "Valid" 3888 "Valid" 3887 "Valid" 3886 "Valid" 3885 "Valid" 3884 "Valid" 3883 "Valid" 3882 "Valid" 3881 "Valid" 3880 "Valid" 3879 "Valid" 3878 "Valid" 3877 "Valid" 3876 "Valid" 3875 "Valid" 3874 "Valid" 3873 "Valid" 3872 "Valid" 3871 "Valid" 3870 "Valid" 3869 "Valid" 3868 "Valid" 3867 "Valid" 3866 "Valid" 3865 "Valid" 3864 "Valid" 3863 "Valid" 3862 "Valid" 3861 "Valid" 3860 "Valid" 3859 "Valid" 3858 "Valid" 3857 "Valid" 3856 "Valid" 3855 "Valid" 3854 "Valid" 3853 "Valid" 3852 "Valid" 3851 "Valid" 3850 "Valid" 3849 "Valid" 3848 "Valid" 3847 "Valid" 3846 "Valid" 3845 "Valid" 3844 "Valid" 3843 "Valid" 3842 "Valid" 3841 "Valid" 3840 "Valid" 3839 "Valid" 3838 "Valid" 3837 "Valid" 3836 "Valid" 3835 "Valid" 3834 "Valid" 3833 "Valid" 3832 "Valid" 3831 "Valid" 3830 "Valid" 3829 "Valid" 3828 "Valid" 3827 "Valid" 3826 "Valid" 3825 "Valid" 3824 "Valid" 3823 "Valid" 3822 "Valid" 3821 "Valid" 3820 "Valid" 3819 "Valid" 3818 "Valid" 3817 "Valid" 3816 "Valid" 3815 "Valid" 3814 "Valid" 3813 "Valid" 3812 "Valid" 3811 "Valid" 3810 "Valid" 3809 "Valid" 3808 "Valid" 3807 "Valid" 3806 "Valid" 3805 "Valid" 3804 "Valid" 3803 "Valid" 3802 "Valid" 3801 "Valid" 3800 "Valid" 3799 "Valid" 3798 "Valid" 3797 "Valid" 3796 "Valid" 3795 "Valid" 3794 "Valid" 3793 "Valid" 3792 "Valid" 3791 "Valid" 3790 "Valid" 3789 "Valid" 3788 "Valid" 3787 "Valid" 3786 "Valid" 3785 "Valid" 3784 "Valid" 3783 "Valid" 3782 "Valid" 3781 "Valid" 3780 "Valid" 3779 "Valid" 3778 "Valid" 3777 "Valid" 3776 "Valid" 3775 "Valid" 3774 "Valid" 3773 "Valid" 3772 "Valid" 3771 "Valid" 3770 "Valid" 3769 "Valid" 3768 "Valid" 3767 "Valid" 3766 "Valid" 3765 "Valid" 3764 "Valid" 3763 "Valid" 3762 "Valid" 3761 "Valid" 3760 "Valid" 3759 "Valid" 3758 "Valid" 3757 "Valid" 3756 "Valid" 3755 "Valid" 3754 "Valid" 3753 "Valid" 3752 "Valid" 3751 "Valid" 3750 "Valid" 3749 "Valid" 3748 "Valid" 3747 "Valid" 3746 "Valid" 3745 "Valid" 3744 "Valid" 3743 "Valid" 3742 "Valid" 3741 "Valid" 3740 "Valid" 3739 "Valid" 3738 "Valid" 3737 "Valid" 3736 "Valid" 3735 "Valid" 3734 "Valid" 3733 "Valid" 3732 "Valid" 3731 "Valid" 3730 "Valid" 3729 "Valid" 3728 "Valid" 3727 "Valid" 3726 "Valid" 3725 "Valid" 3724 "Valid" 3723 "Valid" 3722 "Valid" 3721 "Valid" 3720 "Valid" 3719 "Valid" 3718 "Valid" 3717 "Valid" 3716 "Valid" 3715 "Valid" 3714 "Valid" 3713 "Valid" 3712 "Valid" 3711 "Valid" 3710 "Valid" 3709 "Valid" 3708 "Valid" 3707 "Valid" 3706 "Valid" 3705 "Valid" 3704 "Valid" 3703 "Valid" 3702 "Valid" 3701 "Valid" 3700 "Valid" 3699 "Valid" 3698 "Valid" 3697 "Valid" 3696 "Valid" 3695 "Valid" 3694 "Valid" 3693 "Valid" 3692 "Valid" 3691 "Valid" 3690 "Valid" 3689 "Valid" 3688 "Valid" 3687 "Valid" 3686 "Valid" 3685 "Valid" 3684 "Valid" 3683 "Valid" 3682 "Valid" 3681 "Valid" 3680 "Valid" 3679 "Valid" 3678 "Valid" 3677 "Valid" 3676 "Valid" 3675 "Valid" 3674 "Valid" 3673 "Valid" 3672 "Valid" 3671 "Valid" 3670 "Valid" 3669 "Valid" 3668 "Valid" 3667 "Valid" 3666 "Valid" 3665 "Valid" 3664 "Valid" 3663 "Valid" 3662 "Valid" 3661 "Valid" 3660 "Valid" 3659 "Valid" 3658 "Valid" 3657 "Valid" 3656 "Valid" 3655 "Valid" 3654 "Valid" 3653 "Valid" 3652 "Valid" 3651 "Valid" 3650 "Valid" 3649 "Valid" 3648 "Valid" 3647 "Valid" 3646 "Valid" 3645 "Valid" 3644 "Valid" 3643 "Valid" 3642 "Valid" 3641 "Valid" 3640 "Valid" 3639 "Valid" 3638 "Valid" 3637 "Valid" 3636 "Valid" 3635 "Valid" 3634 "Valid" 3633 "Valid" 3632 "Valid" 3631 "Valid" 3630 "Valid" 3629 "Valid" 3628 "Valid" 3627 "Valid" 3626 "Valid" 3625 "Valid" 3624 "Valid" 3623 "Valid" 3622 "Valid" 3621 "Valid" 3620 "Valid" 3619 "Valid" 3618 "Valid" 3617 "Valid" 3616 "Valid" 3615 "Valid" 3614 "Valid" 3613 "Valid" 3612 "Valid" 3611 "Valid" 3610 "Valid" 3609 "Valid" 3608 "Valid" 3607 "Valid" 3606 "Valid" 3605 "Valid" 3604 "Valid" 3603 "Valid" 3602 "Valid" 3601 "Valid" 3600 "Valid" 3599 "Valid" 3598 "Valid" 3597 "Valid" 3596 "Valid" 3595 "Valid" 3594 "Valid" 3593 "Valid" 3592 "Valid" 3591 "Valid" 3590 "Valid" 3589 "Valid" 3588 "Valid" 3587 "Valid" 3586 "Valid" 3585 "Valid" 3584 "Valid" 3583 "Valid" 3582 "Valid" 3581 "Valid" 3580 "Valid" 3579 "Valid" 3578 "Valid" 3577 "Valid" 3576 "Valid" 3575 "Valid" 3574 "Valid" 3573 "Valid" 3572 "Valid" 3571 "Valid" 3570 "Valid" 3569 "Valid" 3568 "Valid" 3567 "Valid" 3566 "Valid" 3565 "Valid" 3564 "Valid" 3563 "Valid" 3562 "Valid" 3561 "Valid" 3560 "Valid" 3559 "Valid" 3558 "Valid" 3557 "Valid" 3556 "Valid" 3555 "Valid" 3554 "Valid" 3553 "Valid" 3552 "Valid" 3551 "Valid" 3550 "Valid" 3549 "Valid" 3548 "Valid" 3547 "Valid" 3546 "Valid" 3545 "Valid" 3544 "Valid" 3543 "Valid" 3542 "Valid" 3541 "Valid" 3540 "Valid" 3539 "Valid" 3538 "Valid" 3537 "Valid" 3536 "Valid" 3535 "Valid" 3534 "Valid" 3533 "Valid" 3532 "Valid" 3531 "Valid" 3530 "Valid" 3529 "Valid" 3528 "Valid" 3527 "Valid" 3526 "Valid" 3525 "Valid" 3524 "Valid" 3523 "Valid" 3522 "Valid" 3521 "Valid" 3520 "Valid" 3519 "Valid" 3518 "Valid" 3517 "Valid" 3516 "Valid" 3515 "Valid" 3514 "Valid" 3513 "Valid" 3512 "Valid" 3511 "Valid" 3510 "Valid" 3509 "Valid" 3508 "Valid" 3507 "Valid" 3506 "Valid" 3505 "Valid" 3504 "Valid" 3503 "Valid" 3502 "Valid" 3501 "Valid" 3500 "Valid" 3499 "Valid" 3498 "Valid" 3497 "Valid" 3496 "Valid" 3495 "Valid" 3494 "Valid" 3493 "Valid" 3492 "Valid" 3491 "Valid" 3490 "Valid" 3489 "Valid" 3488 "Valid" 3487 "Valid" 3486 "Valid" 3485 "Valid" 3484 "Valid" 3483 "Valid" 3482 "Valid" 3481 "Valid" 3480 "Valid" 3479 "Valid" 3478 "Valid" 3477 "Valid" 3476 "Valid" 3475 "Valid" 3474 "Valid" 3473 "Valid" 3472 "Valid" 3471 "Valid" 3470 "Valid" 3469 "Valid" 3468 "Valid" 3467 "Valid" 3466 "Valid" 3465 "Valid" 3464 "Valid" 3463 "Valid" 3462 "Valid" 3461 "Valid" 3460 "Valid" 3459 "Valid" 3458 "Valid" 3457 "Valid" 3456 "Valid" 3455 "Valid" 3454 "Valid" 3453 "Valid" 3452 "Valid" 3451 "Valid" 3450 "Valid" 3449 "Valid" 3448 "Valid" 3447 "Valid" 3446 "Valid" 3445 "Valid" 3444 "Valid" 3443 "Valid" 3442 "Valid" 3441 "Valid" 3440 "Valid" 3439 "Valid" 3438 "Valid" 3437 "Valid" 3436 "Valid" 3435 "Valid" 3434 "Valid" 3433 "Valid" 3432 "Valid" 3431 "Valid" 3430 "Valid" 3429 "Valid" 3428 "Valid" 3427 "Valid" 3426 "Valid" 3425 "Valid" 3424 "Valid" 3423 "Valid" 3422 "Valid" 3421 "Valid" 3420 "Valid" 3419 "Valid" 3418 "Valid" 3417 "Valid" 3416 "Valid" 3415 "Valid" 3414 "Valid" 3413 "Valid" 3412 "Valid" 3411 "Valid" 3410 "Valid" 3409 "Valid" 3408 "Valid" 3407 "Valid" 3406 "Valid" 3405 "Valid" 3404 "Valid" 3403 "Valid" 3402 "Valid" 3401 "Valid" 3400 "Valid" 3399 "Valid" 3398 "Valid" 3397 "Valid" 3396 "Valid" 3395 "Valid" 3394 "Valid" 3393 "Valid" 3392 "Valid" 3391 "Valid" 3390 "Valid" 3389 "Valid" 3388 "Valid" 3387 "Valid" 3386 "Valid" 3385 "Valid" 3384 "Valid" 3383 "Valid" 3382 "Valid" 3381 "Valid" 3380 "Valid" 3379 "Valid" 3378 "Valid" 3377 "Valid" 3376 "Valid" 3375 "Valid" 3374 "Valid" 3373 "Valid" 3372 "Valid" 3371 "Valid" 3370 "Valid" 3369 "Valid" 3368 "Valid" 3367 "Valid" 3366 "Valid" 3365 "Valid" 3364 "Valid" 3363 "Valid" 3362 "Valid" 3361 "Valid" 3360 "Valid" 3359 "Valid" 3358 "Valid" 3357 "Valid" 3356 "Valid" 3355 "Valid" 3354 "Valid" 3353 "Valid" 3352 "Valid" 3351 "Valid" 3350 "Valid" 3349 "Valid" 3348 "Valid" 3347 "Valid" 3346 "Valid" 3345 "Valid" 3344 "Valid" 3343 "Valid" 3342 "Valid" 3341 "Valid" 3340 "Valid" 3339 "Valid" 3338 "Valid" 3337 "Valid" 3336 "Valid" 3335 "Valid" 3334 "Valid" 3333 "Valid" 3332 "Valid" 3331 "Valid" 3330 "Valid" 3329 "Valid" 3328 "Valid" 3327 "Valid" 3326 "Valid" 3325 "Valid" 3324 "Valid" 3323 "Valid" 3322 "Valid" 3321 "Valid" 3320 "Valid" 3319 "Valid" 3318 "Valid" 3317 "Valid" 3316 "Valid" 3315 "Valid" 3314 "Valid" 3313 "Valid" 3312 "Valid" 3311 "Valid" 3310 "Valid" 3309 "Valid" 3308 "Valid" 3307 "Valid" 3306 "Valid" 3305 "Valid" 3304 "Valid" 3303 "Valid" 3302 "Valid" 3301 "Valid" 3300 "Valid" 3299 "Valid" 3298 "Valid" 3297 "Valid" 3296 "Valid" 3295 "Valid" 3294 "Valid" 3293 "Valid" 3292 "Valid" 3291 "Valid" 3290 "Valid" 3289 "Valid" 3288 "Valid" 3287 "Valid" 3286 "Valid" 3285 "Valid" 3284 "Valid" 3283 "Valid" 3282 "Valid" 3281 "Valid" 3280 "Valid" 3279 "Valid" 3278 "Valid" 3277 "Valid" 3276 "Valid" 3275 "Valid" 3274 "Valid" 3273 "Valid" 3272 "Valid" 3271 "Valid" 3270 "Valid" 3269 "Valid" 3268 "Valid" 3267 "Valid" 3266 "Valid" 3265 "Valid" 3264 "Valid" 3263 "Valid" 3262 "Valid" 3261 "Valid" 3260 "Valid" 3259 "Valid" 3258 "Valid" 3257 "Valid" 3256 "Valid" 3255 "Valid" 3254 "Valid" 3253 "Valid" 3252 "Valid" 3251 "Valid" 3250 "Valid" 3249 "Valid" 3248 "Valid" 3247 "Valid" 3246 "Valid" 3245 "Valid" 3244 "Valid" 3243 "Valid" 3242 "Valid" 3241 "Valid" 3240 "Valid" 3239 "Valid" 3238 "Valid" 3237 "Valid" 3236 "Valid" 3235 "Valid" 3234 "Valid" 3233 "Valid" 3232 "Valid" 3231 "Valid" 3230 "Valid" 3229 "Valid" 3228 "Valid" 3227 "Valid" 3226 "Valid" 3225 "Valid" 3224 "Valid" 3223 "Valid" 3222 "Valid" 3221 "Valid" 3220 "Valid" 3219 "Valid" 3218 "Valid" 3217 "Valid" 3216 "Valid" 3215 "Valid" 3214 "Valid" 3213 "Valid" 3212 "Valid" 3211 "Valid" 3210 "Valid" 3209 "Valid" 3208 "Valid" 3207 "Valid" 3206 "Valid" 3205 "Valid" 3204 "Valid" 3203 "Valid" 3202 "Valid" 3201 "Valid" 3200 "Valid" 3199 "Valid" 3198 "Valid" 3197 "Valid" 3196 "Valid" 3195 "Valid" 3194 "Valid" 3193 "Valid" 3192 "Valid" 3191 "Valid" 3190 "Valid" 3189 "Valid" 3188 "Valid" 3187 "Valid" 3186 "Valid" 3185 "Valid" 3184 "Valid" 3183 "Valid" 3182 "Valid" 3181 "Valid" 3180 "Valid" 3179 "Valid" 3178 "Valid" 3177 "Valid" 3176 "Valid" 3175 "Valid" 3174 "Valid" 3173 "Valid" 3172 "Valid" 3171 "Valid" 3170 "Valid" 3169 "Valid" 3168 "Valid" 3167 "Valid" 3166 "Valid" 3165 "Valid" 3164 "Valid" 3163 "Valid" 3162 "Valid" 3161 "Valid" 3160 "Valid" 3159 "Valid" 3158 "Valid" 3157 "Valid" 3156 "Valid" 3155 "Valid" 3154 "Valid" 3153 "Valid" 3152 "Valid" 3151 "Valid" 3150 "Valid" 3149 "Valid" 3148 "Valid" 3147 "Valid" 3146 "Valid" 3145 "Valid" 3144 "Valid" 3143 "Valid" 3142 "Valid" 3141 "Valid" 3140 "Valid" 3139 "Valid" 3138 "Valid" 3137 "Valid" 3136 "Valid" 3135 "Valid" 3134 "Valid" 3133 "Valid" 3132 "Valid" 3131 "Valid" 3130 "Valid" 3129 "Valid" 3128 "Valid" 3127 "Valid" 3126 "Valid" 3125 "Valid" 3124 "Valid" 3123 "Valid" 3122 "Valid" 3121 "Valid" 3120 "Valid" 3119 "Valid" 3118 "Valid" 3117 "Valid" 3116 "Valid" 3115 "Valid" 3114 "Valid" 3113 "Valid" 3112 "Valid" 3111 "Valid" 3110 "Valid" 3109 "Valid" 3108 "Valid" 3107 "Valid" 3106 "Valid" 3105 "Valid" 3104 "Valid" 3103 "Valid" 3102 "Valid" 3101 "Valid" 3100 "Valid" 3099 "Valid" 3098 "Valid" 3097 "Valid" 3096 "Valid" 3095 "Valid" 3094 "Valid" 3093 "Valid" 3092 "Valid" 3091 "Valid" 3090 "Valid" 3089 "Valid" 3088 "Valid" 3087 "Valid" 3086 "Valid" 3085 "Valid" 3084 "Valid" 3083 "Valid" 3082 "Valid" 3081 "Valid" 3080 "Valid" 3079 "Valid" 3078 "Valid" 3077 "Valid" 3076 "Valid" 3075 "Valid" 3074 "Valid" 3073 "Valid" 3072 "Valid" 3071 "Valid" 3070 "Valid" 3069 "Valid" 3068 "Valid" 3067 "Valid" 3066 "Valid" 3065 "Valid" 3064 "Valid" 3063 "Valid" 3062 "Valid" 3061 "Valid" 3060 "Valid" 3059 "Valid" 3058 "Valid" 3057 "Valid" 3056 "Valid" 3055 "Valid" 3054 "Valid" 3053 "Valid" 3052 "Valid" 3051 "Valid" 3050 "Valid" 3049 "Valid" 3048 "Valid" 3047 "Valid" 3046 "Valid" 3045 "Valid" 3044 "Valid" 3043 "Valid" 3042 "Valid" 3041 "Valid" 3040 "Valid" 3039 "Valid" 3038 "Valid" 3037 "Valid" 3036 "Valid" 3035 "Valid" 3034 "Valid" 3033 "Valid" 3032 "Valid" 3031 "Valid" 3030 "Valid" 3029 "Valid" 3028 "Valid" 3027 "Valid" 3026 "Valid" 3025 "Valid" 3024 "Valid" 3023 "Valid" 3022 "Valid" 3021 "Valid" 3020 "Valid" 3019 "Valid" 3018 "Valid" 3017 "Valid" 3016 "Valid" 3015 "Valid" 3014 "Valid" 3013 "Valid" 3012 "Valid" 3011 "Valid" 3010 "Valid" 3009 "Valid" 3008 "Valid" 3007 "Valid" 3006 "Valid" 3005 "Valid" 3004 "Valid" 3003 "Valid" 3002 "Valid" 3001 "Valid" 3000 "Valid" 2999 "Valid" 2998 "Valid" 2997 "Valid" 2996 "Valid" 2995 "Valid" 2994 "Valid" 2993 "Valid" 2992 "Valid" 2991 "Valid" 2990 "Valid" 2989 "Valid" 2988 "Valid" 2987 "Valid" 2986 "Valid" 2985 "Valid" 2984 "Valid" 2983 "Valid" 2982 "Valid" 2981 "Valid" 2980 "Valid" 2979 "Valid" 2978 "Valid" 2977 "Valid" 2976 "Valid" 2975 "Valid" 2974 "Valid" 2973 "Valid" 2972 "Valid" 2971 "Valid" 2970 "Valid" 2969 "Valid" 2968 "Valid" 2967 "Valid" 2966 "Valid" 2965 "Valid" 2964 "Valid" 2963 "Valid" 2962 "Valid" 2961 "Valid" 2960 "Valid" 2959 "Valid" 2958 "Valid" 2957 "Valid" 2956 "Valid" 2955 "Valid" 2954 "Valid" 2953 "Valid" 2952 "Valid" 2951 "Valid" 2950 "Valid" 2949 "Valid" 2948 "Valid" 2947 "Valid" 2946 "Valid" 2945 "Valid" 2944 "Valid" 2943 "Valid" 2942 "Valid" 2941 "Valid" 2940 "Valid" 2939 "Valid" 2938 "Valid" 2937 "Valid" 2936 "Valid" 2935 "Valid" 2934 "Valid" 2933 "Valid" 2932 "Valid" 2931 "Valid" 2930 "Valid" 2929 "Valid" 2928 "Valid" 2927 "Valid" 2926 "Valid" 2925 "Valid" 2924 "Valid" 2923 "Valid" 2922 "Valid" 2921 "Valid" 2920 "Valid" 2919 "Valid" 2918 "Valid" 2917 "Valid" 2916 "Valid" 2915 "Valid" 2914 "Valid" 2913 "Valid" 2912 "Valid" 2911 "Valid" 2910 "Valid" 2909 "Valid" 2908 "Valid" 2907 "Valid" 2906 "Valid" 2905 "Valid" 2904 "Valid" 2903 "Valid" 2902 "Valid" 2901 "Valid" 2900 "Valid" 2899 "Valid" 2898 "Valid" 2897 "Valid" 2896 "Valid" 2895 "Valid" 2894 "Valid" 2893 "Valid" 2892 "Valid" 2891 "Valid" 2890 "Valid" 2889 "Valid" 2888 "Valid" 2887 "Valid" 2886 "Valid" 2885 "Valid" 2884 "Valid" 2883 "Valid" 2882 "Valid" 2881 "Valid" 2880 "Valid" 2879 "Valid" 2878 "Valid" 2877 "Valid" 2876 "Valid" 2875 "Valid" 2874 "Valid" 2873 "Valid" 2872 "Valid" 2871 "Valid" 2870 "Valid" 2869 "Valid" 2868 "Valid" 2867 "Valid" 2866 "Valid" 2865 "Valid" 2864 "Valid" 2863 "Valid" 2862 "Valid" 2861 "Valid" 2860 "Valid" 2859 "Valid" 2858 "Valid" 2857 "Valid" 2856 "Valid" 2855 "Valid" 2854 "Valid" 2853 "Valid" 2852 "Valid" 2851 "Valid" 2850 "Valid" 2849 "Valid" 2848 "Valid" 2847 "Valid" 2846 "Valid" 2845 "Valid" 2844 "Valid" 2843 "Valid" 2842 "Valid" 2841 "Valid" 2840 "Valid" 2839 "Valid" 2838 "Valid" 2837 "Valid" 2836 "Valid" 2835 "Valid" 2834 "Valid" 2833 "Valid" 2832 "Valid" 2831 "Valid" 2830 "Valid" 2829 "Valid" 2828 "Valid" 2827 "Valid" 2826 "Valid" 2825 "Valid" 2824 "Valid" 2823 "Valid" 2822 "Valid" 2821 "Valid" 2820 "Valid" 2819 "Valid" 2818 "Valid" 2817 "Valid" 2816 "Valid" 2815 "Valid" 2814 "Valid" 2813 "Valid" 2812 "Valid" 2811 "Valid" 2810 "Valid" 2809 "Valid" 2808 "Valid" 2807 "Valid" 2806 "Valid" 2805 "Valid" 2804 "Valid" 2803 "Valid" 2802 "Valid" 2801 "Valid" 2800 "Valid" 2799 "Valid" 2798 "Valid" 2797 "Valid" 2796 "Valid" 2795 "Valid" 2794 "Valid" 2793 "Valid" 2792 "Valid" 2791 "Valid" 2790 "Valid" 2789 "Valid" 2788 "Valid" 2787 "Valid" 2786 "Valid" 2785 "Valid" 2784 "Valid" 2783 "Valid" 2782 "Valid" 2781 "Valid" 2780 "Valid" 2779 "Valid" 2778 "Valid" 2777 "Valid" 2776 "Valid" 2775 "Valid" 2774 "Valid" 2773 "Valid" 2772 "Valid" 2771 "Valid" 2770 "Valid" 2769 "Valid" 2768 "Valid" 2767 "Valid" 2766 "Valid" 2765 "Valid" 2764 "Valid" 2763 "Valid" 2762 "Valid" 2761 "Valid" 2760 "Valid" 2759 "Valid" 2758 "Valid" 2757 "Valid" 2756 "Valid" 2755 "Valid" 2754 "Valid" 2753 "Valid" 2752 "Valid" 2751 "Valid" 2750 "Valid" 2749 "Valid" 2748 "Valid" 2747 "Valid" 2746 "Valid" 2745 "Valid" 2744 "Valid" 2743 "Valid" 2742 "Valid" 2741 "Valid" 2740 "Valid" 2739 "Valid" 2738 "Valid" 2737 "Valid" 2736 "Valid" 2735 "Valid" 2734 "Valid" 2733 "Valid" 2732 "Valid" 2731 "Valid" 2730 "Valid" 2729 "Valid" 2728 "Valid" 2727 "Valid" 2726 "Valid" 2725 "Valid" 2724 "Valid" 2723 "Valid" 2722 "Valid" 2721 "Valid" 2720 "Valid" 2719 "Valid" 2718 "Valid" 2717 "Valid" 2716 "Valid" 2715 "Valid" 2714 "Valid" 2713 "Valid" 2712 "Valid" 2711 "Valid" 2710 "Valid" 2709 "Valid" 2708 "Valid" 2707 "Valid" 2706 "Valid" 2705 "Valid" 2704 "Valid" 2703 "Valid" 2702 "Valid" 2701 "Valid" 2700 "Valid" 2699 "Valid" 2698 "Valid" 2697 "Valid" 2696 "Valid" 2695 "Valid" 2694 "Valid" 2693 "Valid" 2692 "Valid" 2691 "Valid" 2690 "Valid" 2689 "Valid" 2688 "Valid" 2687 "Valid" 2686 "Valid" 2685 "Valid" 2684 "Valid" 2683 "Valid" 2682 "Valid" 2681 "Valid" 2680 "Valid" 2679 "Valid" 2678 "Valid" 2677 "Valid" 2676 "Valid" 2675 "Valid" 2674 "Valid" 2673 "Valid" 2672 "Valid" 2671 "Valid" 2670 "Valid" 2669 "Valid" 2668 "Valid" 2667 "Valid" 2666 "Valid" 2665 "Valid" 2664 "Valid" 2663 "Valid" 2662 "Valid" 2661 "Valid" 2660 "Valid" 2659 "Valid" 2658 "Valid" 2657 "Valid" 2656 "Valid" 2655 "Valid" 2654 "Valid" 2653 "Valid" 2652 "Valid" 2651 "Valid" 2650 "Valid" 2649 "Valid" 2648 "Valid" 2647 "Valid" 2646 "Valid" 2645 "Valid" 2644 "Valid" 2643 "Valid" 2642 "Valid" 2641 "Valid" 2640 "Valid" 2639 "Valid" 2638 "Valid" 2637 "Valid" 2636 "Valid" 2635 "Valid" 2634 "Valid" 2633 "Valid" 2632 "Valid" 2631 "Valid" 2630 "Valid" 2629 "Valid" 2628 "Valid" 2627 "Valid" 2626 "Valid" 2625 "Valid" 2624 "Valid" 2623 "Valid" 2622 "Valid" 2621 "Valid" 2620 "Valid" 2619 "Valid" 2618 "Valid" 2617 "Valid" 2616 "Valid" 2615 "Valid" 2614 "Valid" 2613 "Valid" 2612 "Valid" 2611 "Valid" 2610 "Valid" 2609 "Valid" 2608 "Valid" 2607 "Valid" 2606 "Valid" 2605 "Valid" 2604 "Valid" 2603 "Valid" 2602 "Valid" 2601 "Valid" 2600 "Valid" 2599 "Valid" 2598 "Valid" 2597 "Valid" 2596 "Valid" 2595 "Valid" 2594 "Valid" 2593 "Valid" 2592 "Valid" 2591 "Valid" 2590 "Valid" 2589 "Valid" 2588 "Valid" 2587 "Valid" 2586 "Valid" 2585 "Valid" 2584 "Valid" 2583 "Valid" 2582 "Valid" 2581 "Valid" 2580 "Valid" 2579 "Valid" 2578 "Valid" 2577 "Valid" 2576 "Valid" 2575 "Valid" 2574 "Valid" 2573 "Valid" 2572 "Valid" 2571 "Valid" 2570 "Valid" 2569 "Valid" 2568 "Valid" 2567 "Valid" 2566 "Valid" 2565 "Valid" 2564 "Valid" 2563 "Valid" 2562 "Valid" 2561 "Valid" 2560 "Valid" 2559 "Valid" 2558 "Valid" 2557 "Valid" 2556 "Valid" 2555 "Valid" 2554 "Valid" 2553 "Valid" 2552 "Valid" 2551 "Valid" 2550 "Valid" 2549 "Valid" 2548 "Valid" 2547 "Valid" 2546 "Valid" 2545 "Valid" 2544 "Valid" 2543 "Valid" 2542 "Valid" 2541 "Valid" 2540 "Valid" 2539 "Valid" 2538 "Valid" 2537 "Valid" 2536 "Valid" 2535 "Valid" 2534 "Valid" 2533 "Valid" 2532 "Valid" 2531 "Valid" 2530 "Valid" 2529 "Valid" 2528 "Valid" 2527 "Valid" 2526 "Valid" 2525 "Valid" 2524 "Valid" 2523 "Valid" 2522 "Valid" 2521 "Valid" 2520 "Valid" 2519 "Valid" 2518 "Valid" 2517 "Valid" 2516 "Valid" 2515 "Valid" 2514 "Valid" 2513 "Valid" 2512 "Valid" 2511 "Valid" 2510 "Valid" 2509 "Valid" 2508 "Valid" 2507 "Valid" 2506 "Valid" 2505 "Valid" 2504 "Valid" 2503 "Valid" 2502 "Valid" 2501 "Valid" 2500 "Valid" 2499 "Valid" 2498 "Valid" 2497 "Valid" 2496 "Valid" 2495 "Valid" 2494 "Valid" 2493 "Valid" 2492 "Valid" 2491 "Valid" 2490 "Valid" 2489 "Valid" 2488 "Valid" 2487 "Valid" 2486 "Valid" 2485 "Valid" 2484 "Valid" 2483 "Valid" 2482 "Valid" 2481 "Valid" 2480 "Valid" 2479 "Valid" 2478 "Valid" 2477 "Valid" 2476 "Valid" 2475 "Valid" 2474 "Valid" 2473 "Valid" 2472 "Valid" 2471 "Valid" 2470 "Valid" 2469 "Valid" 2468 "Valid" 2467 "Valid" 2466 "Valid" 2465 "Valid" 2464 "Valid" 2463 "Valid" 2462 "Valid" 2461 "Valid" 2460 "Valid" 2459 "Valid" 2458 "Valid" 2457 "Valid" 2456 "Valid" 2455 "Valid" 2454 "Valid" 2453 "Valid" 2452 "Valid" 2451 "Valid" 2450 "Valid" 2449 "Valid" 2448 "Valid" 2447 "Valid" 2446 "Valid" 2445 "Valid" 2444 "Valid" 2443 "Valid" 2442 "Valid" 2441 "Valid" 2440 "Valid" 2439 "Valid" 2438 "Valid" 2437 "Valid" 2436 "Valid" 2435 "Valid" 2434 "Valid" 2433 "Valid" 2432 "Valid" 2431 "Valid" 2430 "Valid" 2429 "Valid" 2428 "Valid" 2427 "Valid" 2426 "Valid" 2425 "Valid" 2424 "Valid" 2423 "Valid" 2422 "Valid" 2421 "Valid" 2420 "Valid" 2419 "Valid" 2418 "Valid" 2417 "Valid" 2416 "Valid" 2415 "Valid" 2414 "Valid" 2413 "Valid" 2412 "Valid" 2411 "Valid" 2410 "Valid" 2409 "Valid" 2408 "Valid" 2407 "Valid" 2406 "Valid" 2405 "Valid" 2404 "Valid" 2403 "Valid" 2402 "Valid" 2401 "Valid" 2400 "Valid" 2399 "Valid" 2398 "Valid" 2397 "Valid" 2396 "Valid" 2395 "Valid" 2394 "Valid" 2393 "Valid" 2392 "Valid" 2391 "Valid" 2390 "Valid" 2389 "Valid" 2388 "Valid" 2387 "Valid" 2386 "Valid" 2385 "Valid" 2384 "Valid" 2383 "Valid" 2382 "Valid" 2381 "Valid" 2380 "Valid" 2379 "Valid" 2378 "Valid" 2377 "Valid" 2376 "Valid" 2375 "Valid" 2374 "Valid" 2373 "Valid" 2372 "Valid" 2371 "Valid" 2370 "Valid" 2369 "Valid" 2368 "Valid" 2367 "Valid" 2366 "Valid" 2365 "Valid" 2364 "Valid" 2363 "Valid" 2362 "Valid" 2361 "Valid" 2360 "Valid" 2359 "Valid" 2358 "Valid" 2357 "Valid" 2356 "Valid" 2355 "Valid" 2354 "Valid" 2353 "Valid" 2352 "Valid" 2351 "Valid" 2350 "Valid" 2349 "Valid" 2348 "Valid" 2347 "Valid" 2346 "Valid" 2345 "Valid" 2344 "Valid" 2343 "Valid" 2342 "Valid" 2341 "Valid" 2340 "Valid" 2339 "Valid" 2338 "Valid" 2337 "Valid" 2336 "Valid" 2335 "Valid" 2334 "Valid" 2333 "Valid" 2332 "Valid" 2331 "Valid" 2330 "Valid" 2329 "Valid" 2328 "Valid" 2327 "Valid" 2326 "Valid" 2325 "Valid" 2324 "Valid" 2323 "Valid" 2322 "Valid" 2321 "Valid" 2320 "Valid" 2319 "Valid" 2318 "Valid" 2317 "Valid" 2316 "Valid" 2315 "Valid" 2314 "Valid" 2313 "Valid" 2312 "Valid" 2311 "Valid" 2310 "Valid" 2309 "Valid" 2308 "Valid" 2307 "Valid" 2306 "Valid" 2305 "Valid" 2304 "Valid" 2303 "Valid" 2302 "Valid" 2301 "Valid" 2300 "Valid" 2299 "Valid" 2298 "Valid" 2297 "Valid" 2296 "Valid" 2295 "Valid" 2294 "Valid" 2293 "Valid" 2292 "Valid" 2291 "Valid" 2290 "Valid" 2289 "Valid" 2288 "Valid" 2287 "Valid" 2286 "Valid" 2285 "Valid" 2284 "Valid" 2283 "Valid" 2282 "Valid" 2281 "Valid" 2280 "Valid" 2279 "Valid" 2278 "Valid" 2277 "Valid" 2276 "Valid" 2275 "Valid" 2274 "Valid" 2273 "Valid" 2272 "Valid" 2271 "Valid" 2270 "Valid" 2269 "Valid" 2268 "Valid" 2267 "Valid" 2266 "Valid" 2265 "Valid" 2264 "Valid" 2263 "Valid" 2262 "Valid" 2261 "Valid" 2260 "Valid" 2259 "Valid" 2258 "Valid" 2257 "Valid" 2256 "Valid" 2255 "Valid" 2254 "Valid" 2253 "Valid" 2252 "Valid" 2251 "Valid" 2250 "Valid" 2249 "Valid" 2248 "Valid" 2247 "Valid" 2246 "Valid" 2245 "Valid" 2244 "Valid" 2243 "Valid" 2242 "Valid" 2241 "Valid" 2240 "Valid" 2239 "Valid" 2238 "Valid" 2237 "Valid" 2236 "Valid" 2235 "Valid" 2234 "Valid" 2233 "Valid" 2232 "Valid" 2231 "Valid" 2230 "Valid" 2229 "Valid" 2228 "Valid" 2227 "Valid" 2226 "Valid" 2225 "Valid" 2224 "Valid" 2223 "Valid" 2222 "Valid" 2221 "Valid" 2220 "Valid" 2219 "Valid" 2218 "Valid" 2217 "Valid" 2216 "Valid" 2215 "Valid" 2214 "Valid" 2213 "Valid" 2212 "Valid" 2211 "Valid" 2210 "Valid" 2209 "Valid" 2208 "Valid" 2207 "Valid" 2206 "Valid" 2205 "Valid" 2204 "Valid" 2203 "Valid" 2202 "Valid" 2201 "Valid" 2200 "Valid" 2199 "Valid" 2198 "Valid" 2197 "Valid" 2196 "Valid" 2195 "Valid" 2194 "Valid" 2193 "Valid" 2192 "Valid" 2191 "Valid" 2190 "Valid" 2189 "Valid" 2188 "Valid" 2187 "Valid" 2186 "Valid" 2185 "Valid" 2184 "Valid" 2183 "Valid" 2182 "Valid" 2181 "Valid" 2180 "Valid" 2179 "Valid" 2178 "Valid" 2177 "Valid" 2176 "Valid" 2175 "Valid" 2174 "Valid" 2173 "Valid" 2172 "Valid" 2171 "Valid" 2170 "Valid" 2169 "Valid" 2168 "Valid" 2167 "Valid" 2166 "Valid" 2165 "Valid" 2164 "Valid" 2163 "Valid" 2162 "Valid" 2161 "Valid" 2160 "Valid" 2159 "Valid" 2158 "Valid" 2157 "Valid" 2156 "Valid" 2155 "Valid" 2154 "Valid" 2153 "Valid" 2152 "Valid" 2151 "Valid" 2150 "Valid" 2149 "Valid" 2148 "Valid" 2147 "Valid" 2146 "Valid" 2145 "Valid" 2144 "Valid" 2143 "Valid" 2142 "Valid" 2141 "Valid" 2140 "Valid" 2139 "Valid" 2138 "Valid" 2137 "Valid" 2136 "Valid" 2135 "Valid" 2134 "Valid" 2133 "Valid" 2132 "Valid" 2131 "Valid" 2130 "Valid" 2129 "Valid" 2128 "Valid" 2127 "Valid" 2126 "Valid" 2125 "Valid" 2124 "Valid" 2123 "Valid" 2122 "Valid" 2121 "Valid" 2120 "Valid" 2119 "Valid" 2118 "Valid" 2117 "Valid" 2116 "Valid" 2115 "Valid" 2114 "Valid" 2113 "Valid" 2112 "Valid" 2111 "Valid" 2110 "Valid" 2109 "Valid" 2108 "Valid" 2107 "Valid" 2106 "Valid" 2105 "Valid" 2104 "Valid" 2103 "Valid" 2102 "Valid" 2101 "Valid" 2100 "Valid" 2099 "Valid" 2098 "Valid" 2097 "Valid" 2096 "Valid" 2095 "Valid" 2094 "Valid" 2093 "Valid" 2092 "Valid" 2091 "Valid" 2090 "Valid" 2089 "Valid" 2088 "Valid" 2087 "Valid" 2086 "Valid" 2085 "Valid" 2084 "Valid" 2083 "Valid" 2082 "Valid" 2081 "Valid" 2080 "Valid" 2079 "Valid" 2078 "Valid" 2077 "Valid" 2076 "Valid" 2075 "Valid" 2074 "Valid" 2073 "Valid" 2072 "Valid" 2071 "Valid" 2070 "Valid" 2069 "Valid" 2068 "Valid" 2067 "Valid" 2066 "Valid" 2065 "Valid" 2064 "Valid" 2063 "Valid" 2062 "Valid" 2061 "Valid" 2060 "Valid" 2059 "Valid" 2058 "Valid" 2057 "Valid" 2056 "Valid" 2055 "Valid" 2054 "Valid" 2053 "Valid" 2052 "Valid" 2051 "Valid" 2050 "Valid" 2049 "Valid" 2048 "Valid" 2047 "Valid" 2046 "Valid" 2045 "Valid" 2044 "Valid" 2043 "Valid" 2042 "Valid" 2041 "Valid" 2040 "Valid" 2039 "Valid" 2038 "Valid" 2037 "Valid" 2036 "Valid" 2035 "Valid" 2034 "Valid" 2033 "Valid" 2032 "Valid" 2031 "Valid" 2030 "Valid" 2029 "Valid" 2028 "Valid" 2027 "Valid" 2026 "Valid" 2025 "Valid" 2024 "Valid" 2023 "Valid" 2022 "Valid" 2021 "Valid" 2020 "Valid" 2019 "Valid" 2018 "Valid" 2017 "Valid" 2016 "Valid" 2015 "Valid" 2014 "Valid" 2013 "Valid" 2012 "Valid" 2011 "Valid" 2010 "Valid" 2009 "Valid" 2008 "Valid" 2007 "Valid" 2006 "Valid" 2005 "Valid" 2004 "Valid" 2003 "Valid" 2002 "Valid" 2001 "Valid" 2000 "Valid" 1999 "Valid" 1998 "Valid" 1997 "Valid" 1996 "Valid" 1995 "Valid" 1994 "Valid" 1993 "Valid" 1992 "Valid" 1991 "Valid" 1990 "Valid" 1989 "Valid" 1988 "Valid" 1987 "Valid" 1986 "Valid" 1985 "Valid" 1984 "Valid" 1983 "Valid" 1982 "Valid" 1981 "Valid" 1980 "Valid" 1979 "Valid" 1978 "Valid" 1977 "Valid" 1976 "Valid" 1975 "Valid" 1974 "Valid" 1973 "Valid" 1972 "Valid" 1971 "Valid" 1970 "Valid" 1969 "Valid" 1968 "Valid" 1967 "Valid" 1966 "Valid" 1965 "Valid" 1964 "Valid" 1963 "Valid" 1962 "Valid" 1961 "Valid" 1960 "Valid" 1959 "Valid" 1958 "Valid" 1957 "Valid" 1956 "Valid" 1955 "Valid" 1954 "Valid" 1953 "Valid" 1952 "Valid" 1951 "Valid" 1950 "Valid" 1949 "Valid" 1948 "Valid" 1947 "Valid" 1946 "Valid" 1945 "Valid" 1944 "Valid" 1943 "Valid" 1942 "Valid" 1941 "Valid" 1940 "Valid" 1939 "Valid" 1938 "Valid" 1937 "Valid" 1936 "Valid" 1935 "Valid" 1934 "Valid" 1933 "Valid" 1932 "Valid" 1931 "Valid" 1930 "Valid" 1929 "Valid" 1928 "Valid" 1927 "Valid" 1926 "Valid" 1925 "Valid" 1924 "Valid" 1923 "Valid" 1922 "Valid" 1921 "Valid" 1920 "Valid" 1919 "Valid" 1918 "Valid" 1917 "Valid" 1916 "Valid" 1915 "Valid" 1914 "Valid" 1913 "Valid" 1912 "Valid" 1911 "Valid" 1910 "Valid" 1909 "Valid" 1908 "Valid" 1907 "Valid" 1906 "Valid" 1905 "Valid" 1904 "Valid" 1903 "Valid" 1902 "Valid" 1901 "Valid" 1900 "Valid" 1899 "Valid" 1898 "Valid" 1897 "Valid" 1896 "Valid" 1895 "Valid" 1894 "Valid" 1893 "Valid" 1892 "Valid" 1891 "Valid" 1890 "Valid" 1889 "Valid" 1888 "Valid" 1887 "Valid" 1886 "Valid" 1885 "Valid" 1884 "Valid" 1883 "Valid" 1882 "Valid" 1881 "Valid" 1880 "Valid" 1879 "Valid" 1878 "Valid" 1877 "Valid" 1876 "Valid" 1875 "Valid" 1874 "Valid" 1873 "Valid" 1872 "Valid" 1871 "Valid" 1870 "Valid" 1869 "Valid" 1868 "Valid" 1867 "Valid" 1866 "Valid" 1865 "Valid" 1864 "Valid" 1863 "Valid" 1862 "Valid" 1861 "Valid" 1860 "Valid" 1859 "Valid" 1858 "Valid" 1857 "Valid" 1856 "Valid" 1855 "Valid" 1854 "Valid" 1853 "Valid" 1852 "Valid" 1851 "Valid" 1850 "Valid" 1849 "Valid" 1848 "Valid" 1847 "Valid" 1846 "Valid" 1845 "Valid" 1844 "Valid" 1843 "Valid" 1842 "Valid" 1841 "Valid" 1840 "Valid" 1839 "Valid" 1838 "Valid" 1837 "Valid" 1836 "Valid" 1835 "Valid" 1834 "Valid" 1833 "Valid" 1832 "Valid" 1831 "Valid" 1830 "Valid" 1829 "Valid" 1828 "Valid" 1827 "Valid" 1826 "Valid" 1825 "Valid" 1824 "Valid" 1823 "Valid" 1822 "Valid" 1821 "Valid" 1820 "Valid" 1819 "Valid" 1818 "Valid" 1817 "Valid" 1816 "Valid" 1815 "Valid" 1814 "Valid" 1813 "Valid" 1812 "Valid" 1811 "Valid" 1810 "Valid" 1809 "Valid" 1808 "Valid" 1807 "Valid" 1806 "Valid" 1805 "Valid" 1804 "Valid" 1803 "Valid" 1802 "Valid" 1801 "Valid" 1800 "Valid" 1799 "Valid" 1798 "Valid" 1797 "Valid" 1796 "Valid" 1795 "Valid" 1794 "Valid" 1793 "Valid" 1792 "Valid" 1791 "Valid" 1790 "Valid" 1789 "Valid" 1788 "Valid" 1787 "Valid" 1786 "Valid" 1785 "Valid" 1784 "Valid" 1783 "Valid" 1782 "Valid" 1781 "Valid" 1780 "Valid" 1779 "Valid" 1778 "Valid" 1777 "Valid" 1776 "Valid" 1775 "Valid" 1774 "Valid" 1773 "Valid" 1772 "Valid" 1771 "Valid" 1770 "Valid" 1769 "Valid" 1768 "Valid" 1767 "Valid" 1766 "Valid" 1765 "Valid" 1764 "Valid" 1763 "Valid" 1762 "Valid" 1761 "Valid" 1760 "Valid" 1759 "Valid" 1758 "Valid" 1757 "Valid" 1756 "Valid" 1755 "Valid" 1754 "Valid" 1753 "Valid" 1752 "Valid" 1751 "Valid" 1750 "Valid" 1749 "Valid" 1748 "Valid" 1747 "Valid" 1746 "Valid" 1745 "Valid" 1744 "Valid" 1743 "Valid" 1742 "Valid" 1741 "Valid" 1740 "Valid" 1739 "Valid" 1738 "Valid" 1737 "Valid" 1736 "Valid" 1735 "Valid" 1734 "Valid" 1733 "Valid" 1732 "Valid" 1731 "Valid" 1730 "Valid" 1729 "Valid" 1728 "Valid" 1727 "Valid" 1726 "Valid" 1725 "Valid" 1724 "Valid" 1723 "Valid" 1722 "Valid" 1721 "Valid" 1720 "Valid" 1719 "Valid" 1718 "Valid" 1717 "Valid" 1716 "Valid" 1715 "Valid" 1714 "Valid" 1713 "Valid" 1712 "Valid" 1711 "Valid" 1710 "Valid" 1709 "Valid" 1708 "Valid" 1707 "Valid" 1706 "Valid" 1705 "Valid" 1704 "Valid" 1703 "Valid" 1702 "Valid" 1701 "Valid" 1700 "Valid" 1699 "Valid" 1698 "Valid" 1697 "Valid" 1696 "Valid" 1695 "Valid" 1694 "Valid" 1693 "Valid" 1692 "Valid" 1691 "Valid" 1690 "Valid" 1689 "Valid" 1688 "Valid" 1687 "Valid" 1686 "Valid" 1685 "Valid" 1684 "Valid" 1683 "Valid" 1682 "Valid" 1681 "Valid" 1680 "Valid" 1679 "Valid" 1678 "Valid" 1677 "Valid" 1676 "Valid" 1675 "Valid" 1674 "Valid" 1673 "Valid" 1672 "Valid" 1671 "Valid" 1670 "Valid" 1669 "Valid" 1668 "Valid" 1667 "Valid" 1666 "Valid" 1665 "Valid" 1664 "Valid" 1663 "Valid" 1662 "Valid" 1661 "Valid" 1660 "Valid" 1659 "Valid" 1658 "Valid" 1657 "Valid" 1656 "Valid" 1655 "Valid" 1654 "Valid" 1653 "Valid" 1652 "Valid" 1651 "Valid" 1650 "Valid" 1649 "Valid" 1648 "Valid" 1647 "Valid" 1646 "Valid" 1645 "Valid" 1644 "Valid" 1643 "Valid" 1642 "Valid" 1641 "Valid" 1640 "Valid" 1639 "Valid" 1638 "Valid" 1637 "Valid" 1636 "Valid" 1635 "Valid" 1634 "Valid" 1633 "Valid" 1632 "Valid" 1631 "Valid" 1630 "Valid" 1629 "Valid" 1628 "Valid" 1627 "Valid" 1626 "Valid" 1625 "Valid" 1624 "Valid" 1623 "Valid" 1622 "Valid" 1621 "Valid" 1620 "Valid" 1619 "Valid" 1618 "Valid" 1617 "Valid" 1616 "Valid" 1615 "Valid" 1614 "Valid" 1613 "Valid" 1612 "Valid" 1611 "Valid" 1610 "Valid" 1609 "Valid" 1608 "Valid" 1607 "Valid" 1606 "Valid" 1605 "Valid" 1604 "Valid" 1603 "Valid" 1602 "Valid" 1601 "Valid" 1600 "Valid" 1599 "Valid" 1598 "Valid" 1597 "Valid" 1596 "Valid" 1595 "Valid" 1594 "Valid" 1593 "Valid" 1592 "Valid" 1591 "Valid" 1590 "Valid" 1589 "Valid" 1588 "Valid" 1587 "Valid" 1586 "Valid" 1585 "Valid" 1584 "Valid" 1583 "Valid" 1582 "Valid" 1581 "Valid" 1580 "Valid" 1579 "Valid" 1578 "Valid" 1577 "Valid" 1576 "Valid" 1575 "Valid" 1574 "Valid" 1573 "Valid" 1572 "Valid" 1571 "Valid" 1570 "Valid" 1569 "Valid" 1568 "Valid" 1567 "Valid" 1566 "Valid" 1565 "Valid" 1564 "Valid" 1563 "Valid" 1562 "Valid" 1561 "Valid" 1560 "Valid" 1559 "Valid" 1558 "Valid" 1557 "Valid" 1556 "Valid" 1555 "Valid" 1554 "Valid" 1553 "Valid" 1552 "Valid" 1551 "Valid" 1550 "Valid" 1549 "Valid" 1548 "Valid" 1547 "Valid" 1546 "Valid" 1545 "Valid" 1544 "Valid" 1543 "Valid" 1542 "Valid" 1541 "Valid" 1540 "Valid" 1539 "Valid" 1538 "Valid" 1537 "Valid" 1536 "Valid" 1535 "Valid" 1534 "Valid" 1533 "Valid" 1532 "Valid" 1531 "Valid" 1530 "Valid" 1529 "Valid" 1528 "Valid" 1527 "Valid" 1526 "Valid" 1525 "Valid" 1524 "Valid" 1523 "Valid" 1522 "Valid" 1521 "Valid" 1520 "Valid" 1519 "Valid" 1518 "Valid" 1517 "Valid" 1516 "Valid" 1515 "Valid" 1514 "Valid" 1513 "Valid" 1512 "Valid" 1511 "Valid" 1510 "Valid" 1509 "Valid" 1508 "Valid" 1507 "Valid" 1506 "Valid" 1505 "Valid" 1504 "Valid" 1503 "Valid" 1502 "Valid" 1501 "Valid" 1500 "Valid" 1499 "Valid" 1498 "Valid" 1497 "Valid" 1496 "Valid" 1495 "Valid" 1494 "Valid" 1493 "Valid" 1492 "Valid" 1491 "Valid" 1490 "Valid" 1489 "Valid" 1488 "Valid" 1487 "Valid" 1486 "Valid" 1485 "Valid" 1484 "Valid" 1483 "Valid" 1482 "Valid" 1481 "Valid" 1480 "Valid" 1479 "Valid" 1478 "Valid" 1477 "Valid" 1476 "Valid" 1475 "Valid" 1474 "Valid" 1473 "Valid" 1472 "Valid" 1471 "Valid" 1470 "Valid" 1469 "Valid" 1468 "Valid" 1467 "Valid" 1466 "Valid" 1465 "Valid" 1464 "Valid" 1463 "Valid" 1462 "Valid" 1461 "Valid" 1460 "Valid" 1459 "Valid" 1458 "Valid" 1457 "Valid" 1456 "Valid" 1455 "Valid" 1454 "Valid" 1453 "Valid" 1452 "Valid" 1451 "Valid" 1450 "Valid" 1449 "Valid" 1448 "Valid" 1447 "Valid" 1446 "Valid" 1445 "Valid" 1444 "Valid" 1443 "Valid" 1442 "Valid" 1441 "Valid" 1440 "Valid" 1439 "Valid" 1438 "Valid" 1437 "Valid" 1436 "Valid" 1435 "Valid" 1434 "Valid" 1433 "Valid" 1432 "Valid" 1431 "Valid" 1430 "Valid" 1429 "Valid" 1428 "Valid" 1427 "Valid" 1426 "Valid" 1425 "Valid" 1424 "Valid" 1423 "Valid" 1422 "Valid" 1421 "Valid" 1420 "Valid" 1419 "Valid" 1418 "Valid" 1417 "Valid" 1416 "Valid" 1415 "Valid" 1414 "Valid" 1413 "Valid" 1412 "Valid" 1411 "Valid" 1410 "Valid" 1409 "Valid" 1408 "Valid" 1407 "Valid" 1406 "Valid" 1405 "Valid" 1404 "Valid" 1403 "Valid" 1402 "Valid" 1401 "Valid" 1400 "Valid" 1399 "Valid" 1398 "Valid" 1397 "Valid" 1396 "Valid" 1395 "Valid" 1394 "Valid" 1393 "Valid" 1392 "Valid" 1391 "Valid" 1390 "Valid" 1389 "Valid" 1388 "Valid" 1387 "Valid" 1386 "Valid" 1385 "Valid" 1384 "Valid" 1383 "Valid" 1382 "Valid" 1381 "Valid" 1380 "Valid" 1379 "Valid" 1378 "Valid" 1377 "Valid" 1376 "Valid" 1375 "Valid" 1374 "Valid" 1373 "Valid" 1372 "Valid" 1371 "Valid" 1370 "Valid" 1369 "Valid" 1368 "Valid" 1367 "Valid" 1366 "Valid" 1365 "Valid" 1364 "Valid" 1363 "Valid" 1362 "Valid" 1361 "Valid" 1360 "Valid" 1359 "Valid" 1358 "Valid" 1357 "Valid" 1356 "Valid" 1355 "Valid" 1354 "Valid" 1353 "Valid" 1352 "Valid" 1351 "Valid" 1350 "Valid" 1349 "Valid" 1348 "Valid" 1347 "Valid" 1346 "Valid" 1345 "Valid" 1344 "Valid" 1343 "Valid" 1342 "Valid" 1341 "Valid" 1340 "Valid" 1339 "Valid" 1338 "Valid" 1337 "Valid" 1336 "Valid" 1335 "Valid" 1334 "Valid" 1333 "Valid" 1332 "Valid" 1331 "Valid" 1330 "Valid" 1329 "Valid" 1328 "Valid" 1327 "Valid" 1326 "Valid" 1325 "Valid" 1324 "Valid" 1323 "Valid" 1322 "Valid" 1321 "Valid" 1320 "Valid" 1319 "Valid" 1318 "Valid" 1317 "Valid" 1316 "Valid" 1315 "Valid" 1314 "Valid" 1313 "Valid" 1312 "Valid" 1311 "Valid" 1310 "Valid" 1309 "Valid" 1308 "Valid" 1307 "Valid" 1306 "Valid" 1305 "Valid" 1304 "Valid" 1303 "Valid" 1302 "Valid" 1301 "Valid" 1300 "Valid" 1299 "Valid" 1298 "Valid" 1297 "Valid" 1296 "Valid" 1295 "Valid" 1294 "Valid" 1293 "Valid" 1292 "Valid" 1291 "Valid" 1290 "Valid" 1289 "Valid" 1288 "Valid" 1287 "Valid" 1286 "Valid" 1285 "Valid" 1284 "Valid" 1283 "Valid" 1282 "Valid" 1281 "Valid" 1280 "Valid" 1279 "Valid" 1278 "Valid" 1277 "Valid" 1276 "Valid" 1275 "Valid" 1274 "Valid" 1273 "Valid" 1272 "Valid" 1271 "Valid" 1270 "Valid" 1269 "Valid" 1268 "Valid" 1267 "Valid" 1266 "Valid" 1265 "Valid" 1264 "Valid" 1263 "Valid" 1262 "Valid" 1261 "Valid" 1260 "Valid" 1259 "Valid" 1258 "Valid" 1257 "Valid" 1256 "Valid" 1255 "Valid" 1254 "Valid" 1253 "Valid" 1252 "Valid" 1251 "Valid" 1250 "Valid" 1249 "Valid" 1248 "Valid" 1247 "Valid" 1246 "Valid" 1245 "Valid" 1244 "Valid" 1243 "Valid" 1242 "Valid" 1241 "Valid" 1240 "Valid" 1239 "Valid" 1238 "Valid" 1237 "Valid" 1236 "Valid" 1235 "Valid" 1234 "Valid" 1233 "Valid" 1232 "Valid" 1231 "Valid" 1230 "Valid" 1229 "Valid" 1228 "Valid" 1227 "Valid" 1226 "Valid" 1225 "Valid" 1224 "Valid" 1223 "Valid" 1222 "Valid" 1221 "Valid" 1220 "Valid" 1219 "Valid" 1218 "Valid" 1217 "Valid" 1216 "Valid" 1215 "Valid" 1214 "Valid" 1213 "Valid" 1212 "Valid" 1211 "Valid" 1210 "Valid" 1209 "Valid" 1208 "Valid" 1207 "Valid" 1206 "Valid" 1205 "Valid" 1204 "Valid" 1203 "Valid" 1202 "Valid" 1201 "Valid" 1200 "Valid" 1199 "Valid" 1198 "Valid" 1197 "Valid" 1196 "Valid" 1195 "Valid" 1194 "Valid" 1193 "Valid" 1192 "Valid" 1191 "Valid" 1190 "Valid" 1189 "Valid" 1188 "Valid" 1187 "Valid" 1186 "Valid" 1185 "Valid" 1184 "Valid" 1183 "Valid" 1182 "Valid" 1181 "Valid" 1180 "Valid" 1179 "Valid" 1178 "Valid" 1177 "Valid" 1176 "Valid" 1175 "Valid" 1174 "Valid" 1173 "Valid" 1172 "Valid" 1171 "Valid" 1170 "Valid" 1169 "Valid" 1168 "Valid" 1167 "Valid" 1166 "Valid" 1165 "Valid" 1164 "Valid" 1163 "Valid" 1162 "Valid" 1161 "Valid" 1160 "Valid" 1159 "Valid" 1158 "Valid" 1157 "Valid" 1156 "Valid" 1155 "Valid" 1154 "Valid" 1153 "Valid" 1152 "Valid" 1151 "Valid" 1150 "Valid" 1149 "Valid" 1148 "Valid" 1147 "Valid" 1146 "Valid" 1145 "Valid" 1144 "Valid" 1143 "Valid" 1142 "Valid" 1141 "Valid" 1140 "Valid" 1139 "Valid" 1138 "Valid" 1137 "Valid" 1136 "Valid" 1135 "Valid" 1134 "Valid" 1133 "Valid" 1132 "Valid" 1131 "Valid" 1130 "Valid" 1129 "Valid" 1128 "Valid" 1127 "Valid" 1126 "Valid" 1125 "Valid" 1124 "Valid" 1123 "Valid" 1122 "Valid" 1121 "Valid" 1120 "Valid" 1119 "Valid" 1118 "Valid" 1117 "Valid" 1116 "Valid" 1115 "Valid" 1114 "Valid" 1113 "Valid" 1112 "Valid" 1111 "Valid" 1110 "Valid" 1109 "Valid" 1108 "Valid" 1107 "Valid" 1106 "Valid" 1105 "Valid" 1104 "Valid" 1103 "Valid" 1102 "Valid" 1101 "Valid" 1100 "Valid" 1099 "Valid" 1098 "Valid" 1097 "Valid" 1096 "Valid" 1095 "Valid" 1094 "Valid" 1093 "Valid" 1092 "Valid" 1091 "Valid" 1090 "Valid" 1089 "Valid" 1088 "Valid" 1087 "Valid" 1086 "Valid" 1085 "Valid" 1084 "Valid" 1083 "Valid" 1082 "Valid" 1081 "Valid" 1080 "Valid" 1079 "Valid" 1078 "Valid" 1077 "Valid" 1076 "Valid" 1075 "Valid" 1074 "Valid" 1073 "Valid" 1072 "Valid" 1071 "Valid" 1070 "Valid" 1069 "Valid" 1068 "Valid" 1067 "Valid" 1066 "Valid" 1065 "Valid" 1064 "Valid" 1063 "Valid" 1062 "Valid" 1061 "Valid" 1060 "Valid" 1059 "Valid" 1058 "Valid" 1057 "Valid" 1056 "Valid" 1055 "Valid" 1054 "Valid" 1053 "Valid" 1052 "Valid" 1051 "Valid" 1050 "Valid" 1049 "Valid" 1048 "Valid" 1047 "Valid" 1046 "Valid" 1045 "Valid" 1044 "Valid" 1043 "Valid" 1042 "Valid" 1041 "Valid" 1040 "Valid" 1039 "Valid" 1038 "Valid" 1037 "Valid" 1036 "Valid" 1035 "Valid" 1034 "Valid" 1033 "Valid" 1032 "Valid" 1031 "Valid" 1030 "Valid" 1029 "Valid" 1028 "Valid" 1027 "Valid" 1026 "Valid" 1025 "Valid" 1024 "Valid" 1023 "Valid" 1022 "Valid" 1021 "Valid" 1020 "Valid" 1019 "Valid" 1018 "Valid" 1017 "Valid" 1016 "Valid" 1015 "Valid" 1014 "Valid" 1013 "Valid" 1012 "Valid" 1011 "Valid" 1010 "Valid" 1009 "Valid" 1008 "Valid" 1007 "Valid" 1006 "Valid" 1005 "Valid" 1004 "Valid" 1003 "Valid" 1002 "Valid" 1001 "Valid" 1000 "Valid" 999 "Valid" 998 "Valid" 997 "Valid" 996 "Valid" 995 "Valid" 994 "Valid" 993 "Valid" 992 "Valid" 991 "Valid" 990 "Valid" 989 "Valid" 988 "Valid" 987 "Valid" 986 "Valid" 985 "Valid" 984 "Valid" 983 "Valid" 982 "Valid" 981 "Valid" 980 "Valid" 979 "Valid" 978 "Valid" 977 "Valid" 976 "Valid" 975 "Valid" 974 "Valid" 973 "Valid" 972 "Valid" 971 "Valid" 970 "Valid" 969 "Valid" 968 "Valid" 967 "Valid" 966 "Valid" 965 "Valid" 964 "Valid" 963 "Valid" 962 "Valid" 961 "Valid" 960 "Valid" 959 "Valid" 958 "Valid" 957 "Valid" 956 "Valid" 955 "Valid" 954 "Valid" 953 "Valid" 952 "Valid" 951 "Valid" 950 "Valid" 949 "Valid" 948 "Valid" 947 "Valid" 946 "Valid" 945 "Valid" 944 "Valid" 943 "Valid" 942 "Valid" 941 "Valid" 940 "Valid" 939 "Valid" 938 "Valid" 937 "Valid" 936 "Valid" 935 "Valid" 934 "Valid" 933 "Valid" 932 "Valid" 931 "Valid" 930 "Valid" 929 "Valid" 928 "Valid" 927 "Valid" 926 "Valid" 925 "Valid" 924 "Valid" 923 "Valid" 922 "Valid" 921 "Valid" 920 "Valid" 919 "Valid" 918 "Valid" 917 "Valid" 916 "Valid" 915 "Valid" 914 "Valid" 913 "Valid" 912 "Valid" 911 "Valid" 910 "Valid" 909 "Valid" 908 "Valid" 907 "Valid" 906 "Valid" 905 "Valid" 904 "Valid" 903 "Valid" 902 "Valid" 901 "Valid" 900 "Valid" 899 "Valid" 898 "Valid" 897 "Valid" 896 "Valid" 895 "Valid" 894 "Valid" 893 "Valid" 892 "Valid" 891 "Valid" 890 "Valid" 889 "Valid" 888 "Valid" 887 "Valid" 886 "Valid" 885 "Valid" 884 "Valid" 883 "Valid" 882 "Valid" 881 "Valid" 880 "Valid" 879 "Valid" 878 "Valid" 877 "Valid" 876 "Valid" 875 "Valid" 874 "Valid" 873 "Valid" 872 "Valid" 871 "Valid" 870 "Valid" 869 "Valid" 868 "Valid" 867 "Valid" 866 "Valid" 865 "Valid" 864 "Valid" 863 "Valid" 862 "Valid" 861 "Valid" 860 "Valid" 859 "Valid" 858 "Valid" 857 "Valid" 856 "Valid" 855 "Valid" 854 "Valid" 853 "Valid" 852 "Valid" 851 "Valid" 850 "Valid" 849 "Valid" 848 "Valid" 847 "Valid" 846 "Valid" 845 "Valid" 844 "Valid" 843 "Valid" 842 "Valid" 841 "Valid" 840 "Valid" 839 "Valid" 838 "Valid" 837 "Valid" 836 "Valid" 835 "Valid" 834 "Valid" 833 "Valid" 832 "Valid" 831 "Valid" 830 "Valid" 829 "Valid" 828 "Valid" 827 "Valid" 826 "Valid" 825 "Valid" 824 "Valid" 823 "Valid" 822 "Valid" 821 "Valid" 820 "Valid" 819 "Valid" 818 "Valid" 817 "Valid" 816 "Valid" 815 "Valid" 814 "Valid" 813 "Valid" 812 "Valid" 811 "Valid" 810 "Valid" 809 "Valid" 808 "Valid" 807 "Valid" 806 "Valid" 805 "Valid" 804 "Valid" 803 "Valid" 802 "Valid" 801 "Valid" 800 "Valid" 799 "Valid" 798 "Valid" 797 "Valid" 796 "Valid" 795 "Valid" 794 "Valid" 793 "Valid" 792 "Valid" 791 "Valid" 790 "Valid" 789 "Valid" 788 "Valid" 787 "Valid" 786 "Valid" 785 "Valid" 784 "Valid" 783 "Valid" 782 "Valid" 781 "Valid" 780 "Valid" 779 "Valid" 778 "Valid" 777 "Valid" 776 "Valid" 775 "Valid" 774 "Valid" 773 "Valid" 772 "Valid" 771 "Valid" 770 "Valid" 769 "Valid" 768 "Valid" 767 "Valid" 766 "Valid" 765 "Valid" 764 "Valid" 763 "Valid" 762 "Valid" 761 "Valid" 760 "Valid" 759 "Valid" 758 "Valid" 757 "Valid" 756 "Valid" 755 "Valid" 754 "Valid" 753 "Valid" 752 "Valid" 751 "Valid" 750 "Valid" 749 "Valid" 748 "Valid" 747 "Valid" 746 "Valid" 745 "Valid" 744 "Valid" 743 "Valid" 742 "Valid" 741 "Valid" 740 "Valid" 739 "Valid" 738 "Valid" 737 "Valid" 736 "Valid" 735 "Valid" 734 "Valid" 733 "Valid" 732 "Valid" 731 "Valid" 730 "Valid" 729 "Valid" 728 "Valid" 727 "Valid" 726 "Valid" 725 "Valid" 724 "Valid" 723 "Valid" 722 "Valid" 721 "Valid" 720 "Valid" 719 "Valid" 718 "Valid" 717 "Valid" 716 "Valid" 715 "Valid" 714 "Valid" 713 "Valid" 712 "Valid" 711 "Valid" 710 "Valid" 709 "Valid" 708 "Valid" 707 "Valid" 706 "Valid" 705 "Valid" 704 "Valid" 703 "Valid" 702 "Valid" 701 "Valid" 700 "Valid" 699 "Valid" 698 "Valid" 697 "Valid" 696 "Valid" 695 "Valid" 694 "Valid" 693 "Valid" 692 "Valid" 691 "Valid" 690 "Valid" 689 "Valid" 688 "Valid" 687 "Valid" 686 "Valid" 685 "Valid" 684 "Valid" 683 "Valid" 682 "Valid" 681 "Valid" 680 "Valid" 679 "Valid" 678 "Valid" 677 "Valid" 676 "Valid" 675 "Valid" 674 "Valid" 673 "Valid" 672 "Valid" 671 "Valid" 670 "Valid" 669 "Valid" 668 "Valid" 667 "Valid" 666 "Valid" 665 "Valid" 664 "Valid" 663 "Valid" 662 "Valid" 661 "Valid" 660 "Valid" 659 "Valid" 658 "Valid" 657 "Valid" 656 "Valid" 655 "Valid" 654 "Valid" 653 "Valid" 652 "Valid" 651 "Valid" 650 "Valid" 649 "Valid" 648 "Valid" 647 "Valid" 646 "Valid" 645 "Valid" 644 "Valid" 643 "Valid" 642 "Valid" 641 "Valid" 640 "Valid" 639 "Valid" 638 "Valid" 637 "Valid" 636 "Valid" 635 "Valid" 634 "Valid" 633 "Valid" 632 "Valid" 631 "Valid" 630 "Valid" 629 "Valid" 628 "Valid" 627 "Valid" 626 "Valid" 625 "Valid" 624 "Valid" 623 "Valid" 622 "Valid" 621 "Valid" 620 "Valid" 619 "Valid" 618 "Valid" 617 "Valid" 616 "Valid" 615 "Valid" 614 "Valid" 613 "Valid" 612 "Valid" 611 "Valid" 610 "Valid" 609 "Valid" 608 "Valid" 607 "Valid" 606 "Valid" 605 "Valid" 604 "Valid" 603 "Valid" 602 "Valid" 601 "Valid" 600 "Valid" 599 "Valid" 598 "Valid" 597 "Valid" 596 "Valid" 595 "Valid" 594 "Valid" 593 "Valid" 592 "Valid" 591 "Valid" 590 "Valid" 589 "Valid" 588 "Valid" 587 "Valid" 586 "Valid" 585 "Valid" 584 "Valid" 583 "Valid" 582 "Valid" 581 "Valid" 580 "Valid" 579 "Valid" 578 "Valid" 577 "Valid" 576 "Valid" 575 "Valid" 574 "Valid" 573 "Valid" 572 "Valid" 571 "Valid" 570 "Valid" 569 "Valid" 568 "Valid" 567 "Valid" 566 "Valid" 565 "Valid" 564 "Valid" 563 "Valid" 562 "Valid" 561 "Valid" 560 "Valid" 559 "Valid" 558 "Valid" 557 "Valid" 556 "Valid" 555 "Valid" 554 "Valid" 553 "Valid" 552 "Valid" 551 "Valid" 550 "Valid" 549 "Valid" 548 "Valid" 547 "Valid" 546 "Valid" 545 "Valid" 544 "Valid" 543 "Valid" 542 "Valid" 541 "Valid" 540 "Valid" 539 "Valid" 538 "Valid" 537 "Valid" 536 "Valid" 535 "Valid" 534 "Valid" 533 "Valid" 532 "Valid" 531 "Valid" 530 "Valid" 529 "Valid" 528 "Valid" 527 "Valid" 526 "Valid" 525 "Valid" 524 "Valid" 523 "Valid" 522 "Valid" 521 "Valid" 520 "Valid" 519 "Valid" 518 "Valid" 517 "Valid" 516 "Valid" 515 "Valid" 514 "Valid" 513 "Valid" 512 "Valid" 511 "Valid" 510 "Valid" 509 "Valid" 508 "Valid" 507 "Valid" 506 "Valid" 505 "Valid" 504 "Valid" 503 "Valid" 502 "Valid" 501 "Valid" 500 "Valid" 499 "Valid" 498 "Valid" 497 "Valid" 496 "Valid" 495 "Valid" 494 "Valid" 493 "Valid" 492 "Valid" 491 "Valid" 490 "Valid" 489 "Valid" 488 "Valid" 487 "Valid" 486 "Valid" 485 "Valid" 484 "Valid" 483 "Valid" 482 "Valid" 481 "Valid" 480 "Valid" 479 "Valid" 478 "Valid" 477 "Valid" 476 "Valid" 475 "Valid" 474 "Valid" 473 "Valid" 472 "Valid" 471 "Valid" 470 "Valid" 469 "Valid" 468 "Valid" 467 "Valid" 466 "Valid" 465 "Valid" 464 "Valid" 463 "Valid" 462 "Valid" 461 "Valid" 460 "Valid" 459 "Valid" 458 "Valid" 457 "Valid" 456 "Valid" 455 "Valid" 454 "Valid" 453 "Valid" 452 "Valid" 451 "Valid" 450 "Valid" 449 "Valid" 448 "Valid" 447 "Valid" 446 "Valid" 445 "Valid" 444 "Valid" 443 "Valid" 442 "Valid" 441 "Valid" 440 "Valid" 439 "Valid" 438 "Valid" 437 "Valid" 436 "Valid" 435 "Valid" 434 "Valid" 433 "Valid" 432 "Valid" 431 "Valid" 430 "Valid" 429 "Valid" 428 "Valid" 427 "Valid" 426 "Valid" 425 "Valid" 424 "Valid" 423 "Valid" 422 "Valid" 421 "Valid" 420 "Valid" 419 "Valid" 418 "Valid" 417 "Valid" 416 "Valid" 415 "Valid" 414 "Valid" 413 "Valid" 412 "Valid" 411 "Valid" 410 "Valid" 409 "Valid" 408 "Valid" 407 "Valid" 406 "Valid" 405 "Valid" 404 "Valid" 403 "Valid" 402 "Valid" 401 "Valid" 400 "Valid" 399 "Valid" 398 "Valid" 397 "Valid" 396 "Valid" 395 "Valid" 394 "Valid" 393 "Valid" 392 "Valid" 391 "Valid" 390 "Valid" 389 "Valid" 388 "Valid" 387 "Valid" 386 "Valid" 385 "Valid" 384 "Valid" 383 "Valid" 382 "Valid" 381 "Valid" 380 "Valid" 379 "Valid" 378 "Valid" 377 "Valid" 376 "Valid" 375 "Valid" 374 "Valid" 373 "Valid" 372 "Valid" 371 "Valid" 370 "Valid" 369 "Valid" 368 "Valid" 367 "Valid" 366 "Valid" 365 "Valid" 364 "Valid" 363 "Valid" 362 "Valid" 361 "Valid" 360 "Valid" 359 "Valid" 358 "Valid" 357 "Valid" 356 "Valid" 355 "Valid" 354 "Valid" 353 "Valid" 352 "Valid" 351 "Valid" 350 "Valid" 349 "Valid" 348 "Valid" 347 "Valid" 346 "Valid" 345 "Valid" 344 "Valid" 343 "Valid" 342 "Valid" 341 "Valid" 340 "Valid" 339 "Valid" 338 "Valid" 337 "Valid" 336 "Valid" 335 "Valid" 334 "Valid" 333 "Valid" 332 "Valid" 331 "Valid" 330 "Valid" 329 "Valid" 328 "Valid" 327 "Valid" 326 "Valid" 325 "Valid" 324 "Valid" 323 "Valid" 322 "Valid" 321 "Valid" 320 "Valid" 319 "Valid" 318 "Valid" 317 "Valid" 316 "Valid" 315 "Valid" 314 "Valid" 313 "Valid" 312 "Valid" 311 "Valid" 310 "Valid" 309 "Valid" 308 "Valid" 307 "Valid" 306 "Valid" 305 "Valid" 304 "Valid" 303 "Valid" 302 "Valid" 301 "Valid" 300 "Valid" 299 "Valid" 298 "Valid" 297 "Valid" 296 "Valid" 295 "Valid" 294 "Valid" 293 "Valid" 292 "Valid" 291 "Valid" 290 "Valid" 289 "Valid" 288 "Valid" 287 "Valid" 286 "Valid" 285 "Valid" 284 "Valid" 283 "Valid" 282 "Valid" 281 "Valid" 280 "Valid" 279 "Valid" 278 "Valid" 277 "Valid" 276 "Valid" 275 "Valid" 274 "Valid" 273 "Valid" 272 "Valid" 271 "Valid" 270 "Valid" 269 "Valid" 268 "Valid" 267 "Valid" 266 "Valid" 265 "Valid" 264 "Valid" 263 "Valid" 262 "Valid" 261 "Valid" 260 "Valid" 259 "Valid" 258 "Valid" 257 "Valid" 256 "Valid" 255 "Valid" 254 "Valid" 253 "Valid" 252 "Valid" 251 "Valid" 250 "Valid" 249 "Valid" 248 "Valid" 247 "Valid" 246 "Valid" 245 "Valid" 244 "Valid" 243 "Valid" 242 "Valid" 241 "Valid" 240 "Valid" 239 "Valid" 238 "Valid" 237 "Valid" 236 "Valid" 235 "Valid" 234 "Valid" 233 "Valid" 232 "Valid" 231 "Valid" 230 "Valid" 229 "Valid" 228 "Valid" 227 "Valid" 226 "Valid" 225 "Valid" 224 "Valid" 223 "Valid" 222 "Valid" 221 "Valid" 220 "Valid" 219 "Valid" 218 "Valid" 217 "Valid" 216 "Valid" 215 "Valid" 214 "Valid" 213 "Valid" 212 "Valid" 211 "Valid" 210 "Valid" 209 "Valid" 208 "Valid" 207 "Valid" 206 "Valid" 205 "Valid" 204 "Valid" 203 "Valid" 202 "Valid" 201 "Valid" 200 "Valid" 199 "Valid" 198 "Valid" 197 "Valid" 196 "Valid" 195 "Valid" 194 "Valid" 193 "Valid" 192 "Valid" 191 "Valid" 190 "Valid" 189 "Valid" 188 "Valid" 187 "Valid" 186 "Valid" 185 "Valid" 184 "Valid" 183 "Valid" 182 "Valid" 181 "Valid" 180 "Valid" 179 "Valid" 178 "Valid" 177 "Valid" 176 "Valid" 175 "Valid" 174 "Valid" 173 "Valid" 172 "Valid" 171 "Valid" 170 "Valid" 169 "Valid" 168 "Valid" 167 "Valid" 166 "Valid" 165 "Valid" 164 "Valid" 163 "Valid" 162 "Valid" 161 "Valid" 160 "Valid" 159 "Valid" 158 "Valid" 157 "Valid" 156 "Valid" 155 "Valid" 154 "Valid" 153 "Valid" 152 "Valid" 151 "Valid" 150 "Valid" 149 "Valid" 148 "Valid" 147 "Valid" 146 "Valid" 145 "Valid" 144 "Valid" 143 "Valid" 142 "Valid" 141 "Valid" 140 "Valid" 139 "Valid" 138 "Valid" 137 "Valid" 136 "Valid" 135 "Valid" 134 "Valid" 133 "Valid" 132 "Valid" 131 "Valid" 130 "Valid" 129 "Valid" 128 "Valid" 127 "Valid" 126 "Valid" 125 "Valid" 124 "Valid" 123 "Valid" 122 "Valid" 121 "Valid" 120 "Valid" 119 "Valid" 118 "Valid" 117 "Valid" 116 "Valid" 115 "Valid" 114 "Valid" 113 "Valid" 112 "Valid" 111 "Valid" 110 "Valid" 109 "Valid" 108 "Valid" 107 "Valid" 106 "Valid" 105 "Valid" 104 "Valid" 103 "Valid" 102 "Valid" 101 "Valid" 100 "Valid" 99 "Valid" 98 "Valid" 97 "Valid" 96 "Valid" 95 "Valid" 94 "Valid" 93 "Valid" 92 "Valid" 91 "Valid" 90 "Valid" 89 "Valid" 88 "Valid" 87 "Valid" 86 "Valid" 85 "Valid" 84 "Valid" 83 "Valid" 82 "Valid" 81 "Valid" 80 "Valid" 79 "Valid" 78 "Valid" 77 "Valid" 76 "Valid" 75 "Valid" 74 "Valid" 73 "Valid" 72 "Valid" 71 "Valid" 70 "Valid" 69 "Valid" 68 "Valid" 67 "Valid" 66 "Valid" 65 "Valid" 64 "Valid" 63 "Valid" 62 "Valid" 61 "Valid" 60 "Valid" 59 "Valid" 58 "Valid" 57 "Valid" 56 "Valid" 55 "Valid" 54 "Valid" 53 "Valid" 52 "Valid" 51 "Valid" 50 "Valid" 49 "Valid" 48 "Valid" 47 "Valid" 46 "Valid" 45 "Valid" 44 "Valid" 43 "Valid" 42 "Valid" 41 "Valid" 40 "Valid" 39 "Valid" 38 "Valid" 37 "Valid" 36 "Valid" 35 "Valid" 34 "Valid" 33 "Valid" 32 "Valid" 31 "Valid" 30 "Valid" 29 "Valid" 28 "Valid" 27 "Valid" 26 "Valid" 25 "Valid" 24 "Valid" 23 "Valid" 22 "Valid" 21 "Valid" 20 "Valid" 19 "Valid" 18 "Valid" 17 "Valid" 16 "Valid" 15 "Valid" 14 "Valid" 13 "Valid" 12 "Valid" 11 "Valid" 10 "Valid" 9 "Valid" 8 "Valid" 7 "Valid" 6 "Valid" 5 "Valid" 4 "Valid" 3 "Valid" 2 "Valid" 1 "Valid" 0 "Valid" ;
VAL_ 515 EVCC_CP_DutyCycleFault 1 "Fault" 0 "No fault" ;
VAL_ 515 EVCC_COUNTRY_SUPPORT 3 "EU+USA" 2 "USA" 1 "EU" 0 "init" ;
VAL_ 515 EVCC_CP_DutyCycleValue 255 "Invalid" ;
VAL_ 515 EVCC_CPSts 7 "CP signal is abnormal" 6 "CP is 12V PWM" 5 "CP is 6V high level" 4 "CP is 6V PWM" 3 "CP is 9V PWM" 2 "CP is 9V high level" 1 "CP is 12V high level" 0 "no CP signal" ;
VAL_ 515 EVCC_S2Swtsts 3 "Error" 2 "reserved" 1 "close" 0 "open" ;
VAL_ 515 EVCC_CC_ConnectSts 3 "Invalid" 2 "Partial connected" 1 "Connected" 0 "Not connected" ;
VAL_ 515 EVCC_CC_ConnectDischarSts 3 "Invalid" 2 "Partial connected" 1 "Connected" 0 "Not connected" ;
VAL_ 515 EVCC_CC2_ConnectSts 3 "Invalid" 2 "Partial connected" 1 "Connected" 0 "Not connected" ;
VAL_ 515 EVCC_CC2_Alarm 1 "Fault" 0 "Normal" ;
VAL_ 515 EVCC_ChargeType 5 "V2L( AC )" 4 "DC charge ( DIN70121 )" 3 "DC charge ( ISO15118 )" 2 "AC charge ( ISO15118 )" 1 "AC charge ( basic signal )" 0 "Unknown" ;
VAL_ 515 EVCC_FaultLevel 7 "Reseverd" 6 "Reseverd" 5 "Reseverd" 4 "Reseverd" 3 "Level3" 2 "Level2" 1 "Level1" 0 "Normal" ;
VAL_ 515 EVCC_CPMaxVolt 1023 "Invalid" ;
VAL_ 515 EVCC_DCPlusTemp 255 "Invalid" ;
VAL_ 515 EVCC_DCMinusTemp 255 "Invalid" ;
VAL_ 515 EVCC_CPVolt 127 "Invalid" ;
VAL_ 515 EVCC_ChargingStage 255 "Invalid" 254 "Reserved" 253 "Reserved" 252 "Reserved" 251 "Reserved" 250 "Reserved" 249 "Reserved" 248 "Reserved" 247 "Reserved" 246 "Reserved" 245 "Reserved" 244 "Reserved" 243 "Reserved" 242 "Reserved" 241 "Reserved" 240 "Reserved" 239 "Reserved" 238 "Reserved" 237 "Reserved" 236 "Reserved" 235 "Reserved" 234 "Reserved" 233 "Reserved" 232 "Reserved" 231 "Reserved" 230 "Reserved" 229 "Reserved" 228 "Reserved" 227 "Reserved" 226 "Reserved" 225 "Reserved" 224 "Reserved" 223 "Reserved" 222 "Reserved" 221 "Reserved" 220 "Reserved" 219 "Reserved" 218 "Reserved" 217 "Reserved" 216 "Reserved" 215 "Reserved" 214 "Reserved" 213 "Reserved" 212 "Reserved" 211 "Reserved" 210 "Reserved" 209 "Reserved" 208 "Reserved" 207 "Reserved" 206 "Reserved" 205 "Reserved" 204 "Reserved" 203 "Reserved" 202 "Reserved" 201 "Reserved" 200 "Reserved" 199 "Reserved" 198 "Reserved" 197 "Reserved" 196 "Reserved" 195 "Reserved" 194 "Reserved" 193 "Reserved" 192 "Reserved" 191 "Reserved" 190 "Reserved" 189 "Reserved" 188 "Reserved" 187 "Reserved" 186 "Reserved" 185 "Reserved" 184 "Reserved" 183 "Reserved" 182 "Reserved" 181 "Reserved" 180 "Reserved" 179 "Reserved" 178 "Reserved" 177 "Reserved" 176 "Reserved" 175 "Reserved" 174 "Reserved" 173 "Reserved" 172 "Reserved" 171 "Reserved" 170 "Reserved" 169 "Reserved" 168 "Reserved" 167 "Reserved" 166 "Reserved" 165 "Reserved" 164 "Reserved" 163 "Reserved" 162 "Reserved" 161 "Reserved" 160 "Reserved" 159 "Reserved" 158 "Reserved" 157 "Reserved" 156 "Reserved" 155 "Reserved" 154 "Reserved" 153 "Reserved" 152 "Reserved" 151 "Reserved" 150 "Reserved" 149 "Reserved" 148 "Reserved" 147 "Reserved" 146 "Reserved" 145 "Reserved" 144 "AEF_Discharge" 143 "Reserved" 142 "Reserved" 141 "Reserved" 140 "Reserved" 139 "Reserved" 138 "Reserved" 137 "Reserved" 136 "Reserved" 135 "Reserved" 134 "Reserved" 133 "Reserved" 132 "Reserved" 131 "Reserved" 130 "Reserved" 129 "C2_ChargingLoop" 128 "B2_WaitS2Close" 127 "Reserved" 126 "Reserved" 125 "Reserved" 124 "Reserved" 123 "Reserved" 122 "Reserved" 121 "Reserved" 120 "Reserved" 119 "Reserved" 118 "Reserved" 117 "Reserved" 116 "Reserved" 115 "Reserved" 114 "Reserved" 113 "Reserved" 112 "B1" 111 "Reserved" 110 "Reserved" 109 "Reserved" 108 "Reserved" 107 "Reserved" 106 "Reserved" 105 "Reserved" 104 "Reserved" 103 "Reserved" 102 "Reserved" 101 "Reserved" 100 "Reserved" 99 "DisLink" 98 "Stop_WaitBSD" 97 "Stop_WaitBST" 96 "EmcStop" 95 "Reserved" 94 "Reserved" 93 "Reserved" 92 "Reserved" 91 "Reserved" 90 "ISO2_DessionStop" 89 "ISO2_WeldingDetection_OPT" 88 "ISO2_PowerDelivery_WaitCP_B" 87 "ISO2_MeteringReceipt_OPT" 86 "ISO2_ChargingStatus" 85 "ISO2_CurrentDemand" 84 "ISO2_PowerDelivery_WaitBCL" 83 "ISO2_PowerDelivery_CRODelay" 82 "ISO2_PowerDelivery_WaitBROAA" 81 "ISO2_PowerDelivery" 80 "ISO2_Precharge_WaitPrecharge" 79 "ISO2_Precharge_WaitBCP" 78 "ISO2_Precharge_WaitBRM" 77 "ISO2_Precharge" 76 "ISO2_CableCheck_WaitInsulation" 75 "ISO2_CableCheck_WaitCP_C" 74 "ISO2_CableCheck" 73 "ISO2_ChargeParameterDiscovery_WaitBHM" 72 "ISO2_ChargeParameterDiscovery" 71 "ISO2_Authorization" 70 "ISO2_PaymentDetails_PNC" 69 "ISO2_CertificateUpdate_PNC" 68 "ISO2_CertificateInstalltion_PNC" 67 "ISO2_ServicePaymentSelection" 66 "ISO2_ServiceDetail_OPT" 65 "ISO2_ServiceDiscovery" 64 "ISO2_SessionSetup" 63 "Reserved" 62 "Reserved" 61 "Reserved" 60 "Reserved" 59 "Reserved" 58 "Reserved" 57 "Reserved" 56 "Reserved" 55 "Reserved" 54 "Reserved" 53 "Reserved" 52 "DIN_SessionStop" 51 "DIN_WeldingDetection_OPT" 50 "DIN_PowerDelivery_WaitCP_B" 49 "DIN_CurrentDemand" 48 "DIN_PowerDelivery_WaitBCL" 47 "DIN_PowerDelivery_CRODelay" 46 "DIN_PowerDelivery_WaitBROAA" 45 "DIN_PowerDelivery" 44 "DIN_Precharge_WaitPrecharge" 43 "DIN_Precharge_WaitBCP" 42 "DIN_Precharge_WaitBRM" 41 "DIN_Precharge" 40 "DIN_CableCheck_WaitInsulation" 39 "DIN_CableCheck_WaitCP_C " 38 "DIN_CbaleCheck" 37 "DIN_ChargeParameterDiscovery_WaitBHM" 36 "DIN_ChargeParameterDiscovery" 35 "DIN_ContractAuthentication" 34 "DIN_ServicePaymentSelection" 33 "DIN_ServiceDiscovery" 32 "DIN_SessionSetup" 31 "Reserved" 30 "Reserved" 29 "Reserved" 28 "Reserved" 27 "Reserved" 26 "Reserved" 25 "Reserved" 24 "Connecting_SupportAppProtocol" 23 "Matched_TCPSuccess" 22 "Matched_SDPSuccess" 21 "Matched_WaitHLC" 20 "Matched" 19 "Matching_SlacRetry" 18 "Matching_SlacJoin" 17 "Matching_SlacAtten" 16 "Matching" 15 "Reserved" 14 "Reserved" 13 "Reserved" 12 "Reserved" 11 "Reserved" 10 "Reserved" 9 "Reserved" 8 "Reserved" 7 "Reserved" 6 "Reserved" 5 "Reserved" 4 "Reserved" 3 "BCD_Delay" 2 "AEF" 1 "PlugOut" 0 "Int" ;
VAL_ 1113 EVCC_PLCAvgAttenuation 255 "Invalid" ;
VAL_ 1113 EVCC_StopChrgnReason 3 "Reserve" 2 "EVSE request stop" 1 "BMS request stop" 0 "No reason" ;
VAL_ 1113 EVCC_A_POSITIVE 3 "Reserve" 2 "No A+ signal" 1 "A+ signal" 0 "Unknown" ;
VAL_ 1113 EVCC_GB_RX_ERROR 10 "GBERR_RX_BSD_TIMEOUT" 9 "GBERR_RX_BST_TIMEOUT" 8 "GBERR_RX_BCS_TIMEOUT" 7 "GBERR_RX_BCL_TIMEOUT" 6 "GBERR_RX_BRO_TIMEOUT" 5 "GBERR_RX_BCP_TIMEOUT" 4 "GBERR_RX_BRM_TIMEOUT" 3 "GBERR_RX_BHM_TIMEOUT" 2 "GBERR_CHARGE_RX_BEM " 1 "GBERR_CHARGE_RX_BST" 0 "no error" ;
VAL_ 1113 EVCC_GB_CHM_ERROR 2 "GBERR_BHM_DATA_INVALID" 1 "GBERR_RX_BHM_DATA_ERROR" 0 "no error" ;
VAL_ 1113 EVCC_GB_CML_ERROR 1 "GBERR_RX_BRO_DATA_ERROR" 0 "no error" ;
VAL_ 1113 EVCC_APP_DM_ERROR 4 "EVCC_APP_DISMATCH_MESSAGESETS" 3 "EVCC_APP_DISMATCH_PWM" 2 "EVCC_APP_DISMATCH_PAYMENT_MODE" 1 "EVCC_APP_DISMATCH_TRANSFER_MODE" 0 "no error" ;
VAL_ 1113 EVCC_GB_SPECIAL_ERROR 5 "GBERR_GUNLOCK_TIMEOUT" 4 "GBERR_EV_READY_TIMEOUT" 3 "GBERR_PRECHARGE_TIMEOUT" 2 "GBERR_INSULATION_TIMEOUT" 1 "GBERR_GUNLOCK_STATUS" 0 "no error" ;
VAL_ 1113 EVCC_GB_CRM_ERROR 2 "GBERR_RX_BCP_DATA_ERROR" 1 "GBERR_RX_BRM_DATA_ERROR" 0 "no error" ;
VAL_ 1113 EVCC_GB_CRO_ERROR 1 "GBERR_RX_BCL_DATA_ERROR" 0 "no error" ;
VAL_ 1113 EVCC_GB_CCS_ERROR 2 "GBERR_RX_BCS_DATA_ERROR" 1 "GBERR_RX_BCL_DATA_ERROR2" 0 "no error" ;
VAL_ 1113 EVCC_GB_CST_ERROR 1 "GBERR_RX_BST_DATA_ERROR" 0 "no error" ;
VAL_ 1113 EVCC_GB_CSD_ERROR 1 "GBERR_RX_BSD_DATA_ERROR" 0 "no error" ;
VAL_ 1113 EVCC_MATCHING_ERROR 5 "EVCC_MATCHING_C" 4 "EVCC_MATCHING_PLUGOUT" 3 "EVCC_MATCHING_AEF" 2 "EVCC_MATCHING_FAILED" 1 "EVCC_MATCHING_TIMEOUT" 0 "no error" ;
VAL_ 1113 EVCC_MATCHED_ERROR 1 "EVCC_MATCHED_DISCONNECT_TIMEOUT" 0 "no error" ;
VAL_ 1113 EVCC_BC_B1_ERROR 3 "EVCC_BC_B1_DETECT_APP" 2 "EVCC_BC_B1_DETECT_AEF" 1 "EVCC_BC_B1_C_STATE" 0 "no error" ;
VAL_ 1113 EVCC_BC_B2_ERROR 2 "EVCC_BC_B2_DETECT_AEF" 1 "EVCC_BC_B2_DETECT_APP" 0 "no error" ;
VAL_ 1113 EVCC_BC_STATE_REQ_TO 1 "EVCC_BC_STATE_REQ_TIMEOUT" 0 "no error" ;
VAL_ 1113 EVCC_BC_C2_ERROR 3 "EVCC_BC_C2_DETECT_APP" 2 "EVCC_BC_C2_DETECT_B" 1 "EVCC_BC_C2_DETECT_AEF" 0 "no error" ;
VAL_ 1113 EVCC_BC_EMC_ERROR 5 "EVCC_BC_EMC_TAIL_TIMEOUT" 4 "EVCC_BC_EMC_LEVEL3_TIMEOUT" 3 "EVCC_BC_EMC_LEVEL3_APP" 2 "EVCC_BC_EMC_LEVEL2_TIMEOUT" 1 "EVCC_BC_EMC_APP_LEVEL2" 0 "no error" ;
VAL_ 1113 EVCC_BC_STOP_ERROR 6 "EVCC_BC_STOP_TAIL_TIMEOUT" 5 "EVCC_BC_STOP_TAILWORK" 4 "EVCC_BC_STOP_STATE_TIMEOUT" 3 "EVCC_BC_STOP_AEF " 2 "EVCC_BC_STOP_TIMEOUT " 1 "EVCC_BC_STOP_APPNORMAL" 0 "no error" ;
VAL_ 1113 EVCC_CONNECTING_ERROR 7 "EVCC_CONNECTING_MSG_TIMEOUT" 6 "EVCC_CONNECTING_INVALID_SCHEMAID " 5 "EVCC_CONNECTING_NEGOTIATION" 4 "EVCC_CONNECTING_LINK_MISS" 3 "EVCC_CONNECTING_DETECT_C " 2 "EVCC_CONNECTING_DETECT_AEF" 1 "EVCC_CONNECTING_TIMEOUT" 0 "no error" ;
VAL_ 1113 EVCC_SLEEP_AEF_DETECT 1 "EVCC_SLEEP_AEF_DETECT" 0 "no error" ;
VAL_ 1113 EVCC_V2G_REQ_TO_ERROR 17 "EVCC_V2G_REQ_TO_WDETECTION" 16 "EVCC_V2G_REQ_TO_CURRENTDEMAND" 15 "EVCC_V2G_REQ_TO_PRECHARGE" 14 "EVCC_V2G_REQ_TO_CABLECHECK" 13 "EVCC_V2G_REQ_TO_CHARGINGSTATUS" 12 "EVCC_V2G_REQ_TO_METERINGRECEIPT" 11 "EVCC_V2G_REQ_TO_SSTOP" 10 "EVCC_V2G_REQ_TO_CINSTALLATION" 9 "EVCC_V2G_REQ_TO_CUPDATE" 8 "EVCC_V2G_REQ_TO_POWERDELIVERY" 7 "EVCC_V2G_REQ_TO_CPD " 6 "EVCC_V2G_REQ_TO_AUTHORIZATION " 5 "EVCC_V2G_REQ_TO_PAYMENTDETAILS" 4 "EVCC_V2G_REQ_TO_PSS" 3 "EVCC_V2G_REQ_TO_SDETAIL" 2 "EVCC_V2G_REQ_TO_SDISCOVERY " 1 "EVCC_V2G_REQ_TO_SSETUP " 0 "no error" ;
VAL_ 1113 EVCC_V2G_RES_TO_ERROR 17 "EVCC_V2G_RES_TO_WDETECTION" 16 "EVCC_V2G_RES_TO_CURRENTDEMAND" 15 "EVCC_V2G_RES_TO_PRECHARGE" 14 "EVCC_V2G_RES_TO_CABLECHECK" 13 "EVCC_V2G_RES_TO_CHARGINGSTATUS" 12 "EVCC_V2G_RES_TO_METERINGRECEIPT" 11 "EVCC_V2G_RES_TO_SSTOP" 10 "EVCC_V2G_RES_TO_CINSTALLATION" 9 "EVCC_V2G_RES_TO_CUPDATE" 8 "EVCC_V2G_RES_TO_POWERDELIVERY" 7 "EVCC_V2G_RES_TO_CPD " 6 "EVCC_V2G_RES_TO_AUTHORIZATION " 5 "EVCC_V2G_RES_TO_PAYMENTDETAILS" 4 "EVCC_V2G_RES_TO_PSS" 3 "EVCC_V2G_RES_TO_SDETAIL" 2 "EVCC_V2G_RES_TO_SDISCOVERY " 1 "EVCC_V2G_RES_TO_SSETUP " 0 "no error" ;
VAL_ 1113 EVCC_V2G_ERROR 8 "EVCC_V2G_PWM_INVALID" 7 "EVCC_V2G_CONNECTING_TIMEOUT" 6 "EVCC_V2G_APP_ERROR" 5 "EVCC_V2G_DETECT_C2_LOCK_FAILED" 4 "EVCC_V2G_DETECT_B2_LOCK_FAILED" 3 "EVCC_V2G_NET_MISS " 2 "EVCC_V2G_LINK_MISS" 1 "EVCC_V2G_DETECT_AEF" 0 "no error" ;
VAL_ 1113 EVCC_SSETUP_ERROR 4 "EVCC_SSETUP_RES_APP_DEAL_FAILED" 3 "EVCC_SSETUP_WAIT_REQ_FAILED" 2 "EVCC_SSETUP_SEND_REQ_FAILED" 1 "EVCC_SSETUP_REQ_APP_DEAL_FAILED" 0 "no error" ;
VAL_ 1113 EVCC_SDISCOVERY_ERROR 4 "EVCC_SDISCOVERY_RES_APP_DEAL_FAILED" 3 "EVCC_SDISCOVERY_WAIT_REQ_FAILED" 2 "EVCC_SDISCOVERY_SEND_REQ_FAILED" 1 "EVCC_SDISCOVERY_REQ_APP_DEAL_FAILED" 0 "no error" ;
VAL_ 1113 EVCC_PSS_ERROR 4 "EVCC_PSS_RES_APP_DEAL_FAILED" 3 "EVCC_PSS_WAIT_REQ_FAILED" 2 "EVCC_PSS_SEND_REQ_FAILED" 1 "EVCC_PSS_REQ_APP_DEAL_FAILED" 0 "no error" ;
VAL_ 1113 EVCC_AUTHORIZATION_ERROR 6 "EVCC_AUTHORIZATION_ONGOING_TIMEOUT" 5 "EVCC_AUTHORIZATION_SIGNATURE_FAILED" 4 "EVCC_AUTHORIZATION_RES_APP_DEAL_FAILED" 3 "EVCC_AUTHORIZATION_WAIT_REQ_FAILED" 2 "EVCC_AUTHORIZATION_SEND_REQ_FAILED" 1 "EVCC_AUTHORIZATION_REQ_APP_DEAL_FAILED" 0 "no error" ;
VAL_ 1113 EVCC_CPD_ERROR 5 "EVCC_CPD_ONGOING_TIMEOUT" 4 "EVCC_CPD_RES_APP_DEAL_FAILED" 3 "EVCC_CPD_WAIT_REQ_FAILED" 2 "EVCC_CPD_SEND_REQ_FAILED" 1 "EVCC_CPD_REQ_APP_DEAL_FAILED" 0 "no error" ;
VAL_ 1113 EVCC_POWERDELIVERY_CP_STATE 1 "EVCC_POWERDELIVERY_CP_STATE" 0 "no error" ;
VAL_ 1113 EVCC_CHARGINGSTATUS_ERROR 4 "EVCC_CHARGINGSTATUS_RES_APP_DEAL_FAILED" 3 "EVCC_CHARGINGSTATUS_WAIT_REQ_FAILED" 2 "EVCC_CHARGINGSTATUS_SEND_REQ_FAILED" 1 "EVCC_CHARGINGSTATUS_REQ_APP_DEAL_FAILED" 0 "no error" ;
VAL_ 1113 EVCC_SSTOP_ERROR 4 "EVCC_SSTOP_RES_APP_DEAL_FAILED" 3 "EVCC_SSTOP_WAIT_REQ_FAILED" 2 "EVCC_SSTOP_SEND_REQ_FAILED" 1 "EVCC_SSTOP_REQ_APP_DEAL_FAILED" 0 "no error" ;
VAL_ 1113 EVCC_CABLECHECK_ERROR 6 "EVCC_CABLECHECK_CP_CTRL" 5 "EVCC_CABLECHECK_TIMEOUT" 4 "EVCC_CABLECHECK_RES_APP_DEAL_FAILED" 3 "EVCC_CABLECHECK_WAIT_REQ_FAILED" 2 "EVCC_CABLECHECK_SEND_REQ_FAILED" 1 "EVCC_CABLECHECK_REQ_APP_DEAL_FAILED" 0 "no error" ;
VAL_ 1113 EVCC_PRECHARGE_ERROR 5 "EVCC_PRECHARGE_TIMEOUT" 4 "EVCC_PRECHARGE_RES_APP_DEAL_FAILED" 3 "EVCC_PRECHARGE_WAIT_REQ_FAILED" 2 "EVCC_PRECHARGE_SEND_REQ_FAILED" 1 "EVCC_PRECHARGE_REQ_APP_DEAL_FAILED" 0 "no error" ;
VAL_ 1113 EVCC_CURRENTDEMAND_ERROR 4 "EVCC_CURRENTDEMAND_RES_APP_DEAL_FAILED" 3 "EVCC_CURRENTDEMAND_WAIT_REQ_FAILED" 2 "EVCC_CURRENTDEMAND_SEND_REQ_FAILED" 1 "EVCC_CURRENTDEMAND_REQ_APP_DEAL_FAILED" 0 "no error" ;
VAL_ 1113 EVCC_WDETECTION_ERROR 4 "EVCC_WDETECTION_RES_APP_DEAL_FAILED" 3 "EVCC_WDETECTION_WAIT_REQ_FAILED" 2 "EVCC_WDETECTION_SEND_REQ_FAILED" 1 "EVCC_WDETECTION_REQ_APP_DEAL_FAILED" 0 "no error" ;
VAL_ 1113 EVCC_V2GTP_ERROR 5 "EVCC_OSI_V2GTP_PAYLOAD_LEN" 4 "EVCC_OSI_V2GTP_HEAD_ERROR" 3 "EVCC_OSI_V2GTP_DATA_OVERFLOW " 2 "EVCC_OSI_V2GTP_TYPE_ERROR" 1 "EVCC_OSI_V2GTP_RECEIVE_DATA_INVALID" 0 "no error" ;
VAL_ 1113 EVCC_EXI_ERROR 6 "EVCC_OSI_EXI_DIN_DECODE_FAILED" 5 "EVCC_OSI_EXI_DIN_ENCODE_FAILED" 4 "EVCC_OSI_EXI_MSG_DECODE_FAILED" 3 "EVCC_OSI_EXI_MSG_ENCODE_FAILED" 2 "EVCC_OSI_EXI_APP_HAND_DECODE_FAILED" 1 "EVCC_OSI_EXI_APP_HAND_ENCODE_FAILED" 0 "no error" ;
VAL_ 1113 EVCC_NET_ERROR 11 "EVCC_OSI_NET_UDP_BIND_CARD" 10 "EVCC_OSI_NET_DISMATCH" 9 "EVCC_OSI_NET_SDP_RES_LEN " 8 "EVCC_OSI_NET_SDP_RES_HEAD" 7 "EVCC_OSI_NET_UDP_RECV_ERR" 6 "EVCC_OSI_NET_TCP_SEND_ERR" 5 "EVCC_OSI_NET_TCP_CONNECT_ERR " 4 "EVCC_OSI_NET_TCP_SOCKET_ERR" 3 "EVCC_OSI_NET_UDP_SEND_ERR" 2 "EVCC_OSI_NET_UDP_BIND_ERR" 1 "EVCC_OSI_NET_UDP_SETSOCKOPT_ERR" 0 "no error" ;
VAL_ 1113 EVCC_EMC_ERROR 6 "EVCC_EMC_TAILWORK_TIMEOUT" 5 "EVCC_EMC_TAILWORK_FAILED" 4 "EVCC_EMC_LEVEL3_TIMEOUT" 3 "EVCC_EMC_LEVEL3_FAILED " 2 "EVCC_EMC_LEVEL2_TIMEOUT" 1 "EVCC_EMC_LEVEL2_FAILED " 0 "no error" ;
VAL_ 1113 EVCC_DIN_ERROR 13 "EVCC_DIN_B1_ERROR" 12 "EVCC_DIN_COMSETUP" 11 "EVCC_DIN_READYTOCHARGE" 10 "EVCC_DIN_APP_ERROR" 9 "EVCC_DIN_C2_LOCK_ERROR" 8 "EVCC_DIN_MSG_PARA" 7 "EVCC_DIN_NET_ERROR" 6 "EVCC_DIN_EVCC_SLAC_ERROR" 5 "EVCC_DIN_MSG_TIMEOUT" 4 "EVCC_DIN_PWM_INVALID" 3 "EVCC_DIN_AEF_ERROR" 2 "EVCC_DIN_SUBMODULE_ERROR" 1 "EVCC_DIN_SUBMODULE_NOPAUSE" 0 "no error" ;
VAL_ 1113 EVCC_DIN_SSETUP_ERROR 6 "EVCC_DIN_SSETUP_APP_RES" 5 "EVCC_DIN_SSETUP_FAIL_PWM" 4 "EVCC_DIN_SSETUP_SEQUENCE" 3 "EVCC_DIN_SSETUP_PARA" 2 "EVCC_DIN_SSETUP_SEND" 1 "EVCC_DIN_SSETUP_APP_REQ" 0 "no error" ;
VAL_ 1113 EVCC_DIN_SDISCOVERY_ERROR 6 "EVCC_DIN_SDISCOVERY_APP_RES" 5 "EVCC_DIN_SDISCOVERY_FAIL_PWM" 4 "EVCC_DIN_SDISCOVERY_SEQUENCE" 3 "EVCC_DIN_SDISCOVERY_PARA" 2 "EVCC_DIN_SDISCOVERY_SEND" 1 "EVCC_DIN_SDISCOVERY_APP_REQ" 0 "no error" ;
VAL_ 1113 EVCC_DIN_SPS_ERROR 6 "EVCC_DIN_SPS_APP_RES" 5 "EVCC_DIN_SPS_FAIL_PWM" 4 "EVCC_DIN_SPS_SEQUENCE" 3 "EVCC_DIN_SPS_PARA" 2 "EVCC_DIN_SPS_SEND" 1 "EVCC_DIN_SPS_APP_REQ" 0 "no error" ;
VAL_ 1113 EVCC_DIN_CAUTHENTICATION_ERROR 7 "EVCC_DIN_CAUTHENTICATION_TIMEOUT" 6 "EVCC_DIN_CAUTHENTICATION_APP_RES" 5 "EVCC_DIN_CAUTHENTICATION_FAIL_PWM" 4 "EVCC_DIN_CAUTHENTICATION_SEQUENCE" 3 "EVCC_DIN_CAUTHENTICATION_PARA" 2 "EVCC_DIN_CAUTHENTICATION_SEND" 1 "EVCC_DIN_CAUTHENTICATION_APP_REQ" 0 "no error" ;
VAL_ 1113 EVCC_DIN_CPD_ERROR 6 "EVCC_DIN_CPD_TIMEOUT" 5 "EVCC_DIN_CPD_APP_RES" 4 "EVCC_DIN_CPD_RESCODE" 3 "EVCC_DIN_CPD_PARA" 2 "EVCC_DIN_CPD_SEND" 1 "EVCC_DIN_CPD_APP_REQ" 0 "no error" ;
VAL_ 1113 EVCC_DIN_CABLECHECK_ERROR 7 "EVCC_DIN_CABLECHECK_STATE_CTRL" 6 "EVCC_DIN_CABLECHECK_TIMEOUT" 5 "EVCC_DIN_CABLECHECK_APP_RES" 4 "EVCC_DIN_CABLECHECK_RESCODE" 3 "EVCC_DIN_CABLECHECK_PARA" 2 "EVCC_DIN_CABLECHECK_SEND" 1 "EVCC_DIN_CABLECHECK_APP_REQ" 0 "no error" ;
VAL_ 1113 EVCC_DIN_PRECHARGE_ERROR 6 "EVCC_DIN_PRECHARGE_TIMEOUT" 5 "EVCC_DIN_PRECHARGE_APP_RES" 4 "EVCC_DIN_PRECHARGE_RESCODE" 3 "EVCC_DIN_PRECHARGE_PARA" 2 "EVCC_DIN_PRECHARGE_SEND" 1 "EVCC_DIN_PRECHARGE_APP_REQ" 0 "no error" ;
VAL_ 1113 EVCC_DIN_POWERDELIVERY_ERROR 6 "EVCC_DIN_POWERDELIVERY_STATE_CTRL" 5 "EVCC_DIN_POWERDELIVERY_APP_RES" 4 "EVCC_DIN_POWERDELIVERY_RESCODE" 3 "EVCC_DIN_POWERDELIVERY_PARA" 2 "EVCC_DIN_POWERDELIVERY_SEND" 1 "EVCC_DIN_POWERDELIVERY_APP_REQ" 0 "no error" ;
VAL_ 1113 EVCC_DIN_CURRENTDEMAND_ERROR 5 "EVCC_DIN_CURRENTDEMAND_APP_RES" 4 "EVCC_DIN_CURRENTDEMAND_RESCODE" 3 "EVCC_DIN_CURRENTDEMAND_PARA" 2 "EVCC_DIN_CURRENTDEMAND_SEND" 1 "EVCC_DIN_CURRENTDEMAND_APP_REQ" 0 "no error" ;
VAL_ 1113 EVCC_DIN_WDETECTION_ERROR 5 "EVCC_DIN_WDETECTION_APP_RES" 4 "EVCC_DIN_WDETECTION_RESCODE" 3 "EVCC_DIN_WDETECTION_PARA" 2 "EVCC_DIN_WDETECTION_SEND" 1 "EVCC_DIN_WDETECTION_APP_REQ" 0 "no error" ;
VAL_ 1113 EVCC_DIN_SSTOP_ERROR 6 "EVCC_DIN_SSTOP_STATE_CTRL" 5 "EVCC_DIN_SSTOP_APP_RES" 4 "EVCC_DIN_SSTOP_RESCODE" 3 "EVCC_DIN_SSTOP_PARA" 2 "EVCC_DIN_SSTOP_SEND" 1 "EVCC_DIN_SSTOP_APP_REQ" 0 "no error" ;
VAL_ 1113 EVCC_DIN_METERINGRECEIPT_ERROR 4 "EVCC_METERINGRECEIPT_RES_APP_DEAL_FAILED" 3 "EVCC_METERINGRECEIPT_WAIT_REQ_FAILED" 2 "EVCC_METERINGRECEIPT_SEND_REQ_FAILED" 1 "EVCC_METERINGRECEIPT_REQ_APP_DEAL_FAILED " 0 "no error" ;
VAL_ 1113 EVCC_SLAC_RETRY_TIMEOUT 1 "EVCC_SLAC_RETRY_TIMEOUT" 0 "no error" ;
VAL_ 1113 EVCC_SLAC_AMPMAP_ERROR 3 "EVCC_SLAC_AMPMAP_CNF_PARA_ERR" 2 "EVCC_SLAC_AMPMAP_CNF_RETRY_OVERFLOW " 1 "EVCC_SLAC_AMPMAP_CNF_TIMEOUT " 0 "no error" ;
VAL_ 1113 EVCC_SLAC_ATTEN_ERROR 2 "EVCC_SLAC_ATTEN_PARM_CNF_PARA_ERR" 1 "EVCC_SLAC_ATTEN_NO_SECC_FOUND " 0 "no error" ;
VAL_ 1113 EVCC_SLAC_BCB_FAILED 1 "EVCC_SLAC_BCB_FAILED" 0 "no error" ;
VAL_ 1113 EVCC_SLAC_JOIN_ERROR 4 "EVCC_SLAC_JOIN_MATCH_CNF_PARA" 3 "EVCC_SLAC_JOIN_NET_TIMEOUT" 2 "EVCC_SLAC_JOIN_SET_KET_RETRY_OVERFLOW " 1 "EVCC_SLAC_JOIN_MATCH_RETRY_OVERFLOW " 0 "no error" ;
VAL_ 1113 EVCC_SLAC_PAUSE_RETRY_OVERFLOW 1 "EVCC_SLAC_PAUSE_RETRY_OVERFLOW" 0 "no error" ;
VAL_ 1113 EVCC_SLAC_RESUME_ERROR 2 "EVCC_SLAC_RESUME_JOIN_TIME" 1 "EVCC_SLAC_RESUME_RETRY_OVERFLOW" 0 "no error" ;
VAL_ 1113 EVCC_SLAC_ETH_ERROR 3 "EVCC_SLAC_ETH_MAC_ERR" 2 "EVCC_SLAC_ETH_TYPE_ERR " 1 "EVCC_SLAC_ETH_LEN_ERR" 0 "no error" ;
VAL_ 1113 EVCC_SLAC_DISLINK_RETRY_OVERFLOW 1 "EVCC_SLAC_DISLINK_RETRY_OVERFLOW" 0 "no error" ;
VAL_ 1113 EVCC_SLAC_INIT_RETRY_OVERFLOW 1 "EVCC_SLAC_INIT_RETRY_OVERFLOW" 0 "no error" ;
VAL_ 1113 EVCC_APP_PSS_ERROR 2 "EVCC_APP_PSS_DECIDE_MESSAGE" 1 "EVCC_APP_PSS_FAILED_RESPONSE" 0 "no error" ;
VAL_ 1113 EVCC_APP_CPD_ERROR 3 "EVCC_APP_CPD_RES_MID" 2 "EVCC_APP_CPD_DEAL_RES" 1 "EVCC_APP_CPD_REQ_MID" 0 "no error" ;
VAL_ 1113 EVCC_APP_DTC_ERROR 3 "EVCC_APP_DTC_CCPC_ERROR_STOP" 2 "EVCC_APP_DTC_CCPC_UNEXPECTED_STOP" 1 "EVCC_APP_DTC_GUN_LOCK" 0 "no error" ;
VAL_ 1113 EVCC_DIN_CCPC_ERROR 4 "EVCC_DIN_EVSE_MALFUNCTION" 3 "EVCC_DIN_EVSE_EMC_SHUTDOWN" 2 "EVCC_DIN_EVSE_MIN_CUR_INVALID" 1 "EVCC_DIN_EVSE_MIN_VOL_INVALID" 0 "no error" ;
VAL_ 1113 EVCC_V2G_CCPC_ERROR 4 "EVCC_ISO1_EVSE_MALFUNCTION" 3 "EVCC_ISO1_EVSE_EMC_SHUTDOWN" 2 "EVCC_ISO1_EVSE_MIN_CUR_INVALID " 1 "EVCC_ISO1_EVSE_MIN_VOL_INVALID " 0 "no error" ;
VAL_ 1113 EVCC_GunConnectSt 3 "Reserved" 2 "The connection is abnormal." 1 "Connect" 0 "Disconnect" ;
VAL_ 1113 EVCC_ElectronicLockSignal_Rel 3 "Unlock sig sent" 2 "Lock sig sent" 1 "No order" 0 "Reserved" ;
VAL_ 1113 EVCC_BatVolConfig 3 "Reserved" 2 "800V" 1 "400V" 0 "Not Configured" ;
VAL_ 571 HoodSts 3 "Reserved" 2 "full_open" 1 "Ajar " 0 "Close" ;
VAL_ 571 LHFdoorSts 3 "Reserved" 2 "full_open" 1 "Ajar " 0 "Close" ;
VAL_ 603 FLZCU_2_PowerMode 3 "Reserved" 2 "ON" 1 "Comfortable" 0 "Off" ;
VAL_ 1181 FLZCU_9_PowerMode 3 "Reserved" 2 "ON" 1 "Comfortable" 0 "Off" ;
VAL_ 1181 FLZCU_9_EleclctroicLockReq 3 "reserved" 2 "lock" 1 "unlock" 0 "default" ;
VAL_ 1181 FLZCU_9_CentralLockingReq 3 "reserved" 2 "lock" 1 "unlock" 0 "default" ;
VAL_ 692 FRZCU_3_ClntTHvBattIn 255 "Error" 254 "Init
" ;
VAL_ 692 FRZCU_3_ClntTHvBattOut 255 "Error" 254 "Init
" ;
VAL_ 692 FRZCU_3_DCPortTemp_P 255 "Error" 254 "Init
" ;
VAL_ 692 FRZCU_3_DCPortTemp_N 255 "Error" 254 "Init
" ;
VAL_ 692 FRZCU_3_CLMHVILFault 1 "Fault" 0 "No fault                             " ;
VAL_ 692 FRZCU_3_HvilChkFltSt 3 "Short circuit to power fault" 2 "Short circuit to ground fault" 1 "Open circuit fault" 0 "no fault" ;
VAL_ 469 FMCU_TorqMax 4095 "Invalid" ;
VAL_ 469 FMCU_TorqMin 4095 "Invalid" ;
VAL_ 469 FMCU_TorqAct 4095 "Invalid" ;
VAL_ 469 FMCU_ModeSt 15 "reserved" 14 "reserved" 13 "reserved" 12 "reserved" 11 "Offset Calibration(DHT)" 10 "Spd Control(Reserved)" 9 "Volt Control(Reserved)" 8 "Fault" 7 "Afterrun" 6 "PowerDown" 5 "Boost_Mode(Reserved)" 4 "Activeheat_Mode" 3 "Tq Control" 2 "HV Ready " 1 "Standby" 0 "INIT (Initialization)" ;
VAL_ 469 FMCU_SpdAct 65535 "Invalid" ;
VAL_ 469 FMCU_TrqActDampingReq 4095 "Invalid" ;
VAL_ 469 FMCU_FMCUDeratSts 15 "reserved" 14 "reserved" 13 "reserved" 12 "reserved" 11 "reserved" 10 "reserved" 9 "IacOverCurRegenDerate" 8 "IacOverCurDrivDerate" 7 "UDcUnderVolDerate" 6 "UDcOverVolDerate" 5 "MotorOverTempDerate" 4 "MotorOverSpdDerate" 3 "WaterovertempDerate" 2 "DiffSpeedDerate" 1 "InvOverTempDerate" 0 "NoFault" ;
VAL_ 469 FMCU_UdcAct 1023 "Invalid" ;
VAL_ 469 FMCU_IdcAct 2047 "Invalid" ;
VAL_ 469 FMCU_ErrLvl 6 "Err_level6" 5 "Err_level5" 4 "Err_level4                                                                              " 3 "Err_level3" 2 "Err_level2                                                                              " 1 "Err_level1                                                                              " 0 "No Error                                                                                     " ;
VAL_ 469 FMCU_InterlockStatus 1 "Interlock (Not Fault)" 0 "Not Interlock (Fault) " ;
VAL_ 469 FMCU_DampActive 1 "Active" 0 "Not Active" ;
VAL_ 469 FMCU_E_ClutchErrLvl 3 "Err_Level3" 2 "Err_Level2                                                                              " 1 "Err_Level1                                                                              " 0 "No Error                                                                                     " ;
VAL_ 469 FMCU_E_ClutchActMod 4 "Fault Mode" 3 "Peak Timeout" 2 "Hold Mmode" 1 "Peak Mode" 0 "Open Mode" ;
VAL_ 469 FMCU_E_ClutchStus 1 "Fault" 0 "Normal" ;
VAL_ 469 FMCU_E_ClutchEngMilLampReq 1 "Request For MIL Light" 0 "No Request For MIL Light" ;
VAL_ 1115 FMCU_InvTemp 255 "Invalid" ;
VAL_ 1115 FMCU_RotorTemperature 511 "Invalid" ;
VAL_ 1115 FMCU_StatTemp 511 "Invalid" ;
VAL_ 1115 FMCU_InvSampTemp 255 "Invalid" ;
VAL_ 1088 FMCU_IGBTmode 7 "Reserved" 6 "Reserved" 5 "Reserved" 4 "Reserved" 3 "Reserved" 2 "PWM_Run" 1 "ASC " 0 "FW" ;
